VERSION ""

NS_ :

BS_:

BU_: GW ZCU_L ADC10 Tester

BO_ 719 IFC_FD3: 64 ADC10
 SG_ AttentionDivsAlarmTimGrad : 445|2@0+ (1,0) [0|3] "NoUnit" Vector__XXX
 SG_ TraLightCtrlSts : 383|3@0+ (1,0) [0|7] "NoUnit" Vector__XXX
 SG_ RR_SideCamaErrSts : 373|3@0+ (1,0) [0|7] "NoUnit" Vector__XXX
 SG_ LR_SideCamaErrSts : 360|3@0+ (1,0) [0|7] "NoUnit" Vector__XXX
 SG_ TraLightSwtResp : 344|1@0+ (1,0) [0|1] "NoUnit" Vector__XXX
 SG_ TraLightRmdInfoDisp : 349|5@0+ (1,0) [0|31] "NoUnit" Vector__XXX
 SG_ TraLightWarnInfoDisp : 337|4@0+ (1,0) [0|15] "NoUnit" Vector__XXX
 SG_ TSR_TFL_EgoVeh : 341|4@0+ (1,0) [0|15] "NoUnit" Vector__XXX
 SG_ TSR_TFL7_LightColor : 328|3@0+ (1,0) [0|7] "NoUnit" Vector__XXX
 SG_ TSR_TFL7_LightType : 332|4@0+ (1,0) [0|15] "NoUnit" Vector__XXX
 SG_ TSR_TFL6_LightColor : 335|3@0+ (1,0) [0|7] "NoUnit" Vector__XXX
 SG_ TSR_TFL6_LightType : 319|4@0+ (1,0) [0|15] "NoUnit" Vector__XXX
 SG_ TSR_TFL5_LightColor : 307|3@0+ (1,0) [0|7] "NoUnit" Vector__XXX
 SG_ TSR_TFL5_LightType : 311|4@0+ (1,0) [0|15] "NoUnit" Vector__XXX
 SG_ TSR_TFL4_LightColor : 298|3@0+ (1,0) [0|7] "NoUnit" Vector__XXX
 SG_ TSR_TFL4_LightType : 302|4@0+ (1,0) [0|15] "NoUnit" Vector__XXX
 SG_ TSR_TFL3_LightColor : 289|3@0+ (1,0) [0|7] "NoUnit" Vector__XXX
 SG_ TSR_TFL3_LightType : 293|4@0+ (1,0) [0|15] "NoUnit" Vector__XXX
 SG_ TSR_TFL2_LightColor : 280|3@0+ (1,0) [0|7] "NoUnit" Vector__XXX
 SG_ TSR_TFL2_LightType : 284|4@0+ (1,0) [0|15] "NoUnit" Vector__XXX
 SG_ TSR_TFL1_LightColor : 287|3@0+ (1,0) [0|7] "NoUnit" Vector__XXX
 SG_ TSR_TFL7_LightTime : 279|8@0+ (1,0) [0|255] "s" Vector__XXX
 SG_ TSR_TFL6_LightTime : 271|8@0+ (1,0) [0|255] "s" Vector__XXX
 SG_ NavDecActive : 239|4@0+ (1,0) [0|15] "NoUnit" Vector__XXX
 SG_ LCMode_Swt_Resp : 227|2@0+ (1,0) [0|3] "NoUnit" Vector__XXX
 SG_ RainMode_Swt_Resp : 228|1@0+ (1,0) [0|1] "NoUnit" Vector__XXX
 SG_ TSR_Traffic_Light_Ri : 230|2@0+ (1,0) [0|3] "NoUnit" Vector__XXX
 SG_ Zebra_Mark_Dx : 223|9@0+ (0.5,0) [0|150] "m" Vector__XXX
 SG_ TSR_Traffic_Light_Le : 210|2@0+ (1,0) [0|3] "NoUnit" Vector__XXX
 SG_ TSR_Traffic_Light_Through : 212|2@0+ (1,0) [0|3] "NoUnit" Vector__XXX
 SG_ TSR_Traffic_Light : 214|2@0+ (1,0) [0|3] "NoUnit" Vector__XXX
 SG_ Grid_Mark_Dx : 207|9@0+ (0.5,0) [0|150] "m" Vector__XXX
 SG_ LaneChngCfmSwt_Resp : 189|1@0+ (1,0) [0|1] "NoUnit" Vector__XXX
 SG_ ALC_SwtReq_Resp : 190|1@0+ (1,0) [0|1] "NoUnit" Vector__XXX
 SG_ AutoSpdSetSwt_Resp : 191|1@0+ (1,0) [0|1] "NoUnit" Vector__XXX
 SG_ VoiceBrdcSwt_Resp : 176|1@0+ (1,0) [0|1] "NoUnit" Vector__XXX
 SG_ UsrManSts_Resp : 180|4@0+ (1,0) [0|15] "NoUnit" Vector__XXX
 SG_ HWA_InhibitWarn : 183|3@0+ (1,0) [0|7] "NoUnit" Vector__XXX
 SG_ Grid_Mark_Detn : 169|2@0+ (1,0) [0|3] "NoUnit" Vector__XXX
 SG_ Zebra_Mark_Detn : 171|2@0+ (1,0) [0|3] "NoUnit" Vector__XXX
 SG_ Stop_Mark_Detn : 173|2@0+ (1,0) [0|3] "NoUnit" Vector__XXX
 SG_ IFC_Line02_Source : 174|1@0+ (1,0) [0|1] "NoUnit" Vector__XXX
 SG_ Stop_Mark_Dx : 167|9@0+ (0.5,0) [0|150] "m" Vector__XXX
 SG_ TSR_Traffic_Light_Posn : 153|2@0+ (1,0) [0|3] "NoUnit" Vector__XXX
 SG_ NOH_WarnInfoDisp : 157|4@0+ (1,0) [0|15] "NoUnit" Vector__XXX
 SG_ MRC_TakOver_Req : 159|2@0+ (1,0) [0|3] "NoUnit" Vector__XXX
 SG_ IFC_Line01_Source : 144|1@0+ (1,0) [0|1] "NoUnit" Vector__XXX
 SG_ MRC_InterSysInfoDisp : 148|4@0+ (1,0) [0|15] "NoUnit" Vector__XXX
 SG_ HWA_TakOver_Trig : 151|3@0+ (1,0) [0|7] "NoUnit" Vector__XXX
 SG_ HWA_TakOver_Req : 137|2@0+ (1,0) [0|3] "NoUnit" Vector__XXX
 SG_ HWA_WarnInfoDisp : 141|4@0+ (1,0) [0|15] "NoUnit" Vector__XXX
 SG_ HWA_ALC_Trig : 143|2@0+ (1,0) [0|3] "NoUnit" Vector__XXX
 SG_ RollingCounter_IFC7 : 123|4@0+ (1,0) [0|14] "NoUnit" Vector__XXX
 SG_ HMA_Sts : 127|3@0+ (1,0) [0|7] "NoUnit" Vector__XXX
 SG_ HMA_HibeamReq : 113|2@0+ (1,0) [0|3] "NoUnit" Vector__XXX
 SG_ IDC_L2_FWshrReq : 119|2@0+ (1,0) [0|3] "NoUnit" Vector__XXX
 SG_ TSRSpdLimWarnAu : 104|1@0+ (1,0) [0|1] "NoUnit" Vector__XXX
 SG_ IDC_L2_FWiperReq : 107|3@0+ (1,0) [0|7] "NoUnit" Vector__XXX
 SG_ TSRWarnResp : 108|1@0+ (1,0) [0|1] "NoUnit" Vector__XXX
 SG_ IDC_L2_TurnLightReq : 110|2@0+ (1,0) [0|3] "NoUnit" Vector__XXX
 SG_ IDC_L2_EmgyLightReq : 111|1@0+ (1,0) [0|1] "NoUnit" Vector__XXX
 SG_ TSR_Snvty : 100|5@0+ (1,-15) [-15|15] "kph" Vector__XXX
 SG_ TSRSpdLimWarn : 101|1@0+ (1,0) [0|1] "NoUnit" Vector__XXX
 SG_ TSRTrfcSignVal : 93|8@0+ (1,0) [0|255] "NoUnit" Vector__XXX
 SG_ TSRTrfcSignValCfdc : 95|2@0+ (1,0) [0|3] "NoUnit" Vector__XXX
 SG_ TSRSpdLimSts : 81|2@0+ (1,0) [0|3] "NoUnit" Vector__XXX
 SG_ TSRSpdLim : 87|6@0+ (1,0) [0|63] "NoUnit" Vector__XXX
 SG_ TSRSts : 74|3@0+ (1,0) [0|7] "NoUnit" Vector__XXX
 SG_ TSRSpdLimCfdc : 76|2@0+ (1,0) [0|3] "NoUnit" Vector__XXX
 SG_ TSRSpdLimUnit : 78|2@0+ (1,0) [0|3] "NoUnit" Vector__XXX
 SG_ TSRResp : 79|1@0+ (1,0) [0|1] "NoUnit" Vector__XXX
 SG_ Checksum_IFC7 : 71|8@0+ (1,0) [0|255] "NoUnit" Vector__XXX
 SG_ TSR_TFL1_LightType : 63|4@0+ (1,0) [0|15] "NoUnit" Vector__XXX
 SG_ TSR_TFL5_LightTime : 55|8@0+ (1,0) [0|255] "s" Vector__XXX
 SG_ TSR_TFL4_LightTime : 47|8@0+ (1,0) [0|255] "s" Vector__XXX
 SG_ TSR_TFL3_LightTime : 39|8@0+ (1,0) [0|255] "s" Vector__XXX
 SG_ TSR_TFL2_LightTime : 31|8@0+ (1,0) [0|255] "s" Vector__XXX
 SG_ TSR_TFL1_LightTime : 23|8@0+ (1,0) [0|255] "s" Vector__XXX
 SG_ TSRConSpdLimWarn : 9|1@0+ (1,0) [0|1] "NoUnit" Vector__XXX
 SG_ TSRConSpdLim : 15|6@0+ (1,0) [0|63] "NoUnit" Vector__XXX

BO_ 846 ACC_FD5: 16 ADC10
 SG_ Sync_SyncTime : 39|32@0+ (1,0) [0|4294967295] "NoUnit" Vector__XXX
 SG_ Sync_OVS : 25|2@0+ (1,0) [0|3] "NoUnit" Vector__XXX
 SG_ Sync_SGW : 26|1@0+ (1,0) [0|1] "NoUnit" Vector__XXX
 SG_ Sync_Resd : 31|5@0+ (1,0) [0|31] "NoUnit" Vector__XXX
 SG_ Sync_Counter : 19|4@0+ (1,0) [0|15] "NoUnit" Vector__XXX
 SG_ Sync_TimeDomain : 23|4@0+ (1,0) [0|15] "NoUnit" Vector__XXX
 SG_ Sync_CRC : 15|8@0+ (1,0) [0|255] "NoUnit" Vector__XXX
 SG_ Sync_Type : 7|8@0+ (1,0) [0|255] "NoUnit" Vector__XXX

BO_ 259 ECM_FD2: 64 GW
 SG_ MAC_Check_ECM_FD2 : 471|48@0+ (1,0) [0|281474976710655] "NoUnit"  ADC10
 SG_ FreshnessValue_ECM_FD2 : 455|16@0+ (1,0) [0|65535] "NoUnit"  ADC10
 SG_ EngState_PHEV : 351|3@0+ (1,0) [0|7] "NoUnit"  ADC10

BO_ 273 ECM1: 8 GW
 SG_ EngSpdVldty : 63|2@0+ (1,0) [0|3] "NoUnit"  ADC10
 SG_ EngSpd : 47|16@0+ (0.125,0) [0|8191.875] "rpm"  ADC10

BO_ 283 VCU_FD2: 64 GW
 SG_ VMCFucActvSts : 423|4@0+ (1,0) [0|15] "NoUnit"  ADC10
 SG_ AccrPedlAntiMsstpngSts : 209|2@0+ (1,0) [0|3] "NoUnit"  ADC10
 SG_ IOTACoolingResp : 211|2@0+ (1,0) [0|3] "NoUnit"  ADC10
 SG_ VCU_MaxSpdLimit : 207|12@0+ (0.1,0) [0|300] "kph"  ADC10
 SG_ RollingCounter_VCU26 : 187|4@0+ (1,0) [0|14] "NoUnit"  ADC10
 SG_ DrvTrqReqOvld : 189|2@0+ (1,0) [0|3] "NoUnit"  ADC10
 SG_ ActTotWheelTrq : 171|13@0+ (5,-20475) [-20475|20475] "Nm"  ADC10
 SG_ VCU_DrvReqTqWhl : 167|12@0+ (5,-6000) [-6000|14470] "Nm"  ADC10
 SG_ MaxPsblPosWheelTrq : 147|12@0+ (5,0) [0|20470] "Nm"  ADC10
 SG_ MinPsblNegWheelTrq : 143|12@0+ (5,-20470) [-20470|0] "Nm"  ADC10
 SG_ Checksum_VCU26 : 135|8@0+ (1,0) [0|255] "NoUnit"  ADC10
 SG_ RollingCounter_VCU21 : 123|4@0+ (1,0) [0|14] "NoUnit"  ADC10
 SG_ DrvgPrkgTrqRespFlg : 125|2@0+ (1,0) [0|3] "NoUnit"  ADC10
 SG_ DrvgPrkgTrqAvailSts : 127|2@0+ (1,0) [0|3] "NoUnit"  ADC10
 SG_ DrvTrqReqOvrdvld : 89|1@0+ (1,0) [0|1] "NoUnit"  ADC10
 SG_ Checksum_VCU21 : 71|8@0+ (1,0) [0|255] "NoUnit"  ADC10
 SG_ RollingCounter_VCU12 : 59|4@0+ (1,0) [0|14] "NoUnit"  ADC10
 SG_ PTDrvMod : 62|3@0+ (1,0) [0|7] "NoUnit"  ADC10
 SG_ DrvMod : 20|5@0+ (1,0) [0|31] "NoUnit"  ADC10
 SG_ VCU_ACCComIf : 23|1@0+ (1,0) [0|1] "NoUnit"  ADC10
 SG_ ActDrvMod : 15|5@0+ (1,0) [0|31] "NoUnit"  ADC10
 SG_ Checksum_VCU12 : 7|8@0+ (1,0) [0|255] "NoUnit"  ADC10

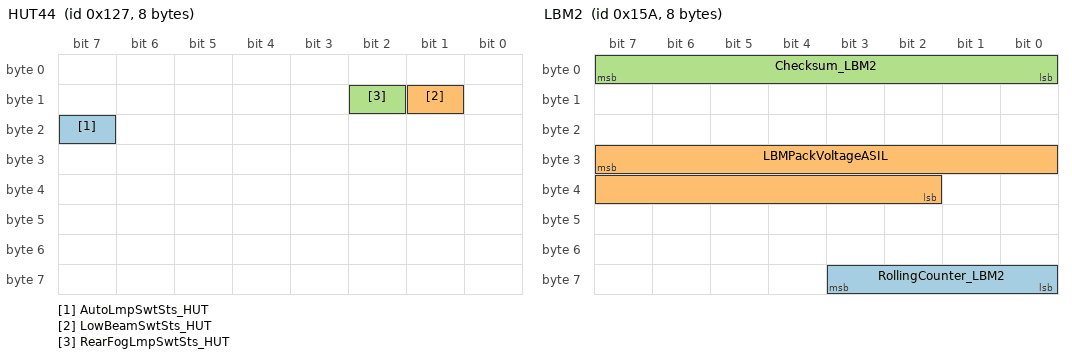
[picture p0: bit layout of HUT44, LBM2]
BO_ 295 HUT44: 8 GW
 SG_ AutoLmpSwtSts_HUT : 23|1@0+ (1,0) [0|1] "NoUnit"  ADC10
 SG_ LowBeamSwtSts_HUT : 9|1@0+ (1,0) [0|1] "NoUnit"  ADC10
 SG_ RearFogLmpSwtSts_HUT : 10|1@0+ (1,0) [0|1] "NoUnit"  ADC10

BO_ 302 IBC_FD1: 64 GW
 SG_ RollingCounter_IBC_FD1_5 : 315|4@0+ (1,0) [0|14] "NoUnit"  ADC10
 SG_ APCFailrSts : 318|3@0+ (1,0) [0|7] "NoUnit"  ADC10
 SG_ BrkgOvrdVld : 306|1@0+ (1,0) [0|1] "NoUnit"  ADC10
 SG_ MEBavailability : 308|1@0+ (1,0) [0|1] "NoUnit"  ADC10
 SG_ APCSts : 311|3@0+ (1,0) [0|7] "NoUnit"  ADC10
 SG_ RPAavailability : 297|2@0+ (1,0) [0|3] "NoUnit"  ADC10
 SG_ APAavailability : 298|1@0+ (1,0) [0|1] "NoUnit"  ADC10
 SG_ CddApActvVehHld : 299|1@0+ (1,0) [0|1] "NoUnit"  ADC10
 SG_ AVPavailability : 301|2@0+ (1,0) [0|3] "NoUnit"  ADC10
 SG_ DrvBrkOvrdFlg : 303|2@0+ (1,0) [0|3] "NoUnit"  ADC10
 SG_ Checksum_IBC_FD1_5 : 263|8@0+ (1,0) [0|255] "NoUnit"  ADC10
 SG_ HydBrkgActTrq : 163|14@0+ (1,-1) [0|16383] "Nm"  ADC10
 SG_ HydBrkgTrqReq : 145|14@0+ (1,-1) [0|16383] "Nm"  ADC10
 SG_ DrvBrkgTrqReq : 143|14@0+ (1,-1) [0|16383] "Nm"  ADC10
 SG_ RollingCounter_IBC_FD1_2 : 123|4@0+ (1,0) [0|14] "NoUnit"  ADC10
 SG_ BrkHldActvSts : 113|2@0+ (1,0) [0|3] "NoUnit"  ADC10
 SG_ BrkHldAvailSts : 115|2@0+ (1,0) [0|3] "NoUnit"  ADC10
 SG_ BrkgTrqModResp : 119|2@0+ (1,0) [0|3] "NoUnit"  ADC10
 SG_ PrkgBrkgTrqAvailSts : 90|3@0+ (1,0) [0|7] "NoUnit"  ADC10
 SG_ DrvgBrkgTrqAvailSts : 93|3@0+ (1,0) [0|7] "NoUnit"  ADC10
 SG_ Checksum_IBC_FD1_2 : 71|8@0+ (1,0) [0|255] "NoUnit"  ADC10
 SG_ RollingCounter_IBC_FD1_1 : 59|4@0+ (1,0) [0|14] "NoUnit"  ADC10
 SG_ PushrodStauts : 51|2@0+ (1,0) [0|3] "NoUnit"  ADC10
 SG_ InpRodStk : 47|10@0+ (0.05,-5) [-5|46.15] "mm"  ADC10
 SG_ InpRodStkSts : 32|1@0+ (1,0) [0|1] "NoUnit"  ADC10
 SG_ FWA_Warn : 34|2@0+ (1,0) [0|3] "NoUnit"  ADC10
 SG_ PlungerPressSts : 35|1@0+ (1,0) [0|1] "NoUnit"  ADC10
 SG_ PlungerPress : 31|12@0+ (0.3,-5) [-5|301.9] "Bar"  ADC10
 SG_ Checksum_IBC_FD1_1 : 7|8@0+ (1,0) [0|255] "NoUnit"  ADC10

BO_ 311 ESP_FD2: 64 GW
 SG_ MAC_Check_ESP_FD2 : 471|48@0+ (1,0) [0|281474976710655] "NoUnit"  ADC10
 SG_ FreshnessValue_ESP_FD2 : 455|16@0+ (1,0) [0|65535] "NoUnit"  ADC10
 SG_ RWSAngMinLimn : 437|10@0+ (0.01,-10) [-10|0] "Deg"  ADC10
 SG_ RWSAngMaxLimn : 431|10@0+ (0.01,0) [0|10] "Deg"  ADC10
 SG_ RollingCounter_ABS3 : 379|4@0+ (1,0) [0|14] "NoUnit"  ADC10
 SG_ ABSActv : 347|1@0+ (1,0) [0|1] "NoUnit"  ADC10
 SG_ EBDActv : 351|1@0+ (1,0) [0|1] "NoUnit"  ADC10
 SG_ VehSpd : 332|13@0+ (0.05625,0) [0|299.98125] "kph"  ADC10
 SG_ VehSpdVld : 333|1@0+ (1,0) [0|1] "NoUnit"  ADC10
 SG_ EBDFailSts : 334|1@0+ (1,0) [0|1] "NoUnit"  ADC10
 SG_ ABSFailSts : 335|1@0+ (1,0) [0|1] "NoUnit"  ADC10
 SG_ Checksum_ABS3 : 327|8@0+ (1,0) [0|255] "NoUnit"  ADC10
 SG_ DrvTrqIncReqActv_FA : 318|1@0+ (1,0) [0|1] "NoUnit"  ADC10
 SG_ DrvTrqRedReqActv_FA : 319|1@0+ (1,0) [0|1] "NoUnit"  ADC10
 SG_ DrvTrqRedFastReq_FA : 287|16@0+ (1,-3000) [-3000|14475] "Nm"  ADC10
 SG_ DrvTrqIncReq_FA : 271|16@0+ (1,-3000) [-3000|5000] "Nm"  ADC10
 SG_ RollingCounter_ESP7 : 251|4@0+ (1,0) [0|14] "NoUnit"  ADC10
 SG_ APS_EngTrqReqEna : 247|1@0+ (1,0) [0|1] "NoUnit"  ADC10
 SG_ EngTrqReq : 231|16@0+ (1,-16383) [-16383|16384] "Nm"  ADC10
 SG_ LgtCtrlrFailr : 220|3@0+ (1,0) [0|7] "NoUnit"  ADC10
 SG_ FourWhlsBrkTrq : 207|14@0+ (1,0) [0|16383] "NoUnit"  ADC10
 SG_ Checksum_ESP7 : 199|8@0+ (1,0) [0|255] "NoUnit"  ADC10
 SG_ RollingCounter_ESP1 : 187|4@0+ (1,0) [0|14] "NoUnit"  ADC10
 SG_ MSRActv_RA : 174|1@0+ (1,0) [0|1] "NoUnit"  ADC10
 SG_ ESP_MasterCylBrkPress : 159|16@0+ (0.03125,-42.5) [-42.5|425] "Bar"  ADC10
 SG_ ESP_MasterCylBrkPressVld : 144|1@0+ (1,0) [0|1] "NoUnit"  ADC10
 SG_ VDCActv : 148|1@0+ (1,0) [0|1] "NoUnit"  ADC10
 SG_ MSRActv : 149|1@0+ (1,0) [0|1] "NoUnit"  ADC10
 SG_ PTCActv : 150|1@0+ (1,0) [0|1] "NoUnit"  ADC10
 SG_ BTCActv : 151|1@0+ (1,0) [0|1] "NoUnit"  ADC10
 SG_ PTCActv_RA : 136|1@0+ (1,0) [0|1] "NoUnit"  ADC10
 SG_ BTCActv_RA : 137|1@0+ (1,0) [0|1] "NoUnit"  ADC10
 SG_ ESPFuncOffSts : 140|1@0+ (1,0) [0|1] "NoUnit"  ADC10
 SG_ ESPBrkLmpCtrl : 142|1@0+ (1,0) [0|1] "NoUnit"  ADC10
 SG_ ESPFailSts : 143|1@0+ (1,0) [0|1] "NoUnit"  ADC10
 SG_ Checksum_ESP1 : 135|8@0+ (1,0) [0|255] "NoUnit"  ADC10
 SG_ RollingCounter_ESP2 : 123|4@0+ (1,0) [0|14] "NoUnit"  ADC10
 SG_ DrivingModDis : 119|5@0+ (1,0) [0|31] "NoUnit"  ADC10
 SG_ DrivingModReq_ESP : 96|5@0+ (1,0) [0|31] "NoUnit"  ADC10
 SG_ AVHErrSts : 99|2@0+ (1,0) [0|3] "NoUnit"  ADC10
 SG_ AVHSts : 101|2@0+ (1,0) [0|3] "NoUnit"  ADC10
 SG_ CDPActv : 103|1@0+ (1,0) [0|1] "NoUnit"  ADC10
 SG_ HDCCtrl : 91|2@0+ (1,0) [0|3] "NoUnit"  ADC10
 SG_ CDDActv : 92|1@0+ (1,0) [0|1] "NoUnit"  ADC10
 SG_ CDDAvailable : 93|1@0+ (1,0) [0|1] "NoUnit"  ADC10
 SG_ AWBAvailable : 94|1@0+ (1,0) [0|1] "NoUnit"  ADC10
 SG_ AWBActv : 95|1@0+ (1,0) [0|1] "NoUnit"  ADC10
 SG_ HHCSts : 80|1@0+ (1,0) [0|1] "NoUnit"  ADC10
 SG_ AEBIBActv : 81|1@0+ (1,0) [0|1] "NoUnit"  ADC10
 SG_ AEBBAActv : 82|1@0+ (1,0) [0|1] "NoUnit"  ADC10
 SG_ AEBAvailable : 83|1@0+ (1,0) [0|1] "NoUnit"  ADC10
 SG_ ABPAvailable : 84|1@0+ (1,0) [0|1] "NoUnit"  ADC10
 SG_ ABPActv : 85|1@0+ (1,0) [0|1] "NoUnit"  ADC10
 SG_ ABAavailable : 86|1@0+ (1,0) [0|1] "NoUnit"  ADC10
 SG_ ABAActv : 87|1@0+ (1,0) [0|1] "NoUnit"  ADC10
 SG_ ESP_DiagActv : 73|1@0+ (1,0) [0|1] "NoUnit"  ADC10
 SG_ CTABrkAvailable : 74|1@0+ (1,0) [0|1] "NoUnit"  ADC10
 SG_ BrkDskOvrheatd : 75|1@0+ (1,0) [0|1] "NoUnit"  ADC10
 SG_ NoBrkForce : 76|1@0+ (1,0) [0|1] "NoUnit"  ADC10
 SG_ VehStandstill : 78|2@0+ (1,0) [0|3] "NoUnit"  ADC10
 SG_ Checksum_ESP2 : 71|8@0+ (1,0) [0|255] "NoUnit"  ADC10
 SG_ RWSAngLimnSts : 54|3@0+ (1,0) [0|7] "NoUnit"  ADC10
 SG_ RWSAngLimnVld : 55|1@0+ (1,0) [0|1] "NoUnit"  ADC10

BO_ 315 ESP_FD3: 64 GW
 SG_ MAC_Check_ESP_FD3 : 471|48@0+ (1,0) [0|281474976710655] "NoUnit"  ADC10
 SG_ FreshnessValue_ESP_FD3 : 455|16@0+ (1,0) [0|65535] "NoUnit"  ADC10
 SG_ RollingCounter_ABS2 : 379|4@0+ (1,0) [0|14] "NoUnit"  ADC10
 SG_ WssRREdgesSumVld : 382|1@0+ (1,0) [0|1] "NoUnit"  ADC10
 SG_ WssRLEdgesSumVld : 383|1@0+ (1,0) [0|1] "NoUnit"  ADC10
 SG_ WssRLEdgesSum : 375|8@0+ (1,0) [0|255] "NoUnit"  ADC10
 SG_ WssRREdgesSum : 367|8@0+ (1,0) [0|255] "NoUnit"  ADC10
 SG_ RRWheelSpd : 348|13@0+ (0.05625,0) [0|299.98125] "kph"  ADC10
 SG_ RRWheelSpdVld : 349|1@0+ (1,0) [0|1] "NoUnit"  ADC10
 SG_ RRWheelDriveDirection : 351|2@0+ (1,0) [0|3] "NoUnit"  ADC10
 SG_ RLWheelSpd : 332|13@0+ (0.05625,0) [0|299.98125] "kph"  ADC10
 SG_ RLWheelSpdVld : 333|1@0+ (1,0) [0|1] "NoUnit"  ADC10
 SG_ RLWheelDriveDirection : 335|2@0+ (1,0) [0|3] "NoUnit"  ADC10
 SG_ Checksum_ABS2 : 327|8@0+ (1,0) [0|255] "NoUnit"  ADC10
 SG_ DrvTrqIncReqActv_RA : 255|1@0+ (1,0) [0|1] "NoUnit"  ADC10
 SG_ DrvTrqRedReqActv_RA : 232|1@0+ (1,0) [0|1] "NoUnit"  ADC10
 SG_ DrvTrqRedReq_RA : 223|16@0+ (1,-6000) [-6000|14475] "Nm"  ADC10
 SG_ DrvTrqIncReq_RA : 207|16@0+ (1,-6000) [-6000|14475] "Nm"  ADC10
 SG_ RollingCounter_EPB1 : 123|4@0+ (1,0) [0|14] "NoUnit"  ADC10
 SG_ ESP_DSTSts : 116|3@0+ (1,0) [0|7] "NoUnit"  ADC10
 SG_ EPBRedLmpSts : 89|2@0+ (1,0) [0|3] "NoUnit"  ADC10
 SG_ EPBErrSts : 91|2@0+ (1,0) [0|3] "NoUnit"  ADC10
 SG_ EPBSts : 93|2@0+ (1,0) [0|3] "NoUnit"  ADC10
 SG_ EPB_SwtPosn : 95|2@0+ (1,0) [0|3] "NoUnit"  ADC10
 SG_ EPB_SwtPosnVld : 80|1@0+ (1,0) [0|1] "NoUnit"  ADC10
 SG_ Checksum_EPB1 : 71|8@0+ (1,0) [0|255] "NoUnit"  ADC10
 SG_ RollingCounter_ABS1 : 59|4@0+ (1,0) [0|14] "NoUnit"  ADC10
 SG_ WssFREdgesSumVld : 62|1@0+ (1,0) [0|1] "NoUnit"  ADC10
 SG_ WssFLEdgesSumVld : 63|1@0+ (1,0) [0|1] "NoUnit"  ADC10
 SG_ WssFREdgesSum : 55|8@0+ (1,0) [0|255] "NoUnit"  ADC10
 SG_ WssFLEdgesSum : 47|8@0+ (1,0) [0|255] "NoUnit"  ADC10
 SG_ FRWheelSpd : 28|13@0+ (0.05625,0) [0|299.98125] "kph"  ADC10
 SG_ FRWheelSpdVld : 29|1@0+ (1,0) [0|1] "NoUnit"  ADC10
 SG_ FRWheelDriveDirection : 31|2@0+ (1,0) [0|3] "NoUnit"  ADC10
 SG_ FLWheelSpd : 12|13@0+ (0.05625,0) [0|299.98125] "kph"  ADC10
 SG_ FLWheelSpdVld : 13|1@0+ (1,0) [0|1] "NoUnit"  ADC10
 SG_ FLWheelDriveDirection : 15|2@0+ (1,0) [0|3] "NoUnit"  ADC10
 SG_ Checksum_ABS1 : 7|8@0+ (1,0) [0|255] "NoUnit"  ADC10

BO_ 320 RWA_FD2: 24 GW
 SG_ RollingCounter_RWA_FD2_2 : 123|4@0+ (1,0) [0|14] "NoUnit"  ADC10
 SG_ SBWActr_PinionAngSpd_Backup : 81|15@0+ (0.1,-1016.1) [-1016|1016] "DegPerSec"  ADC10
 SG_ SBWActr_PinionAng_Backup : 79|14@0+ (0.1,-780.1) [-780|780] "Deg"  ADC10
 SG_ Checksum_RWA_FD2_2 : 71|8@0+ (1,0) [0|255] "NoUnit"  ADC10

BO_ 326 VDC_FD1: 24 GW
 SG_ SuspLvlTrigSrc : 83|3@0+ (1,0) [0|7] "NoUnit"  ADC10
 SG_ TarLvlChg : 51|3@0+ (1,0) [0|7] "NoUnit"  ADC10
 SG_ CurrLvlCtrlMode : 54|3@0+ (1,0) [0|7] "NoUnit"  ADC10
 SG_ LvlAdjmtSts : 10|3@0+ (1,0) [0|7] "NoUnit"  ADC10

BO_ 327 EPS_FD1: 64 GW
 SG_ RollingCounter_EPS3 : 187|4@0+ (1,0) [0|14] "NoUnit"  ADC10
 SG_ EPS_HADHndShkRespSt : 190|3@0+ (1,0) [0|7] "NoUnit"  ADC10
 SG_ EPS_AngCmdOverRange : 191|1@0+ (1,0) [0|1] "NoUnit"  ADC10
 SG_ EPS_AvailStsforHAD : 177|2@0+ (1,0) [0|3] "NoUnit"  ADC10
 SG_ EPS_SteerWheelAngVld : 178|1@0+ (1,0) [0|1] "NoUnit"  ADC10
 SG_ EPS_HADerror_Reason : 183|4@0+ (1,0) [0|15] "NoUnit"  ADC10
 SG_ EPS_SteerWheelSpdSign : 168|1@0+ (1,0) [0|1] "NoUnit"  ADC10
 SG_ EPS_SteerWheelSpd : 167|15@0+ (0.1,0) [0|1016] "DegPerSec"  ADC10
 SG_ EPS_SteerWheelAngSign : 152|1@0+ (1,0) [0|1] "NoUnit"  ADC10
 SG_ EPS_SteerWheelAng : 151|15@0+ (0.1,0) [0|780] "Deg"  ADC10
 SG_ Checksum_EPS3 : 135|8@0+ (1,0) [0|255] "NoUnit"  ADC10
 SG_ RollingCounter_EPS2 : 123|4@0+ (1,0) [0|14] "NoUnit"  ADC10
 SG_ EPS_LKATrqOvlDlvdSts : 125|2@0+ (1,0) [0|3] "NoUnit"  ADC10
 SG_ EPS_DrvInpTrqVal_HighResVld : 126|1@0+ (1,0) [0|1] "NoUnit"  ADC10
 SG_ EPS_LKATorqOvrlDlvdVld : 127|1@0+ (1,0) [0|1] "NoUnit"  ADC10
 SG_ EPS_LKATorqOvrlDlvd : 111|16@0+ (0.01,-15) [-15|15] "Nm"  ADC10
 SG_ EPS_LKAAngDlvdSts : 83|2@0+ (1,0) [0|3] "NoUnit"  ADC10
 SG_ EPS_DrvInpTrqVal_HighReslolution : 79|12@0+ (0.015625,-31.984375) [-31.984375|32] "Nm"  ADC10
 SG_ Checksum_EPS2 : 71|8@0+ (1,0) [0|255] "NoUnit"  ADC10
 SG_ RollingCounter_EPS1 : 59|4@0+ (1,0) [0|14] "NoUnit"  ADC10
 SG_ EPS_SteerMod : 55|3@0+ (1,0) [0|7] "NoUnit"  ADC10
 SG_ SteerSysFltTyp : 39|4@0+ (1,0) [0|15] "NoUnit"  ADC10
 SG_ EPS_AvailSts : 29|2@0+ (1,0) [0|3] "NoUnit"  ADC10
 SG_ EPS_InterferDetdVld : 30|1@0+ (1,0) [0|1] "NoUnit"  ADC10
 SG_ EPS_InterferDetd : 31|1@0+ (1,0) [0|1] "NoUnit"  ADC10
 SG_ EPS_DSTCtrlSts : 11|3@0+ (1,0) [0|7] "NoUnit"  ADC10
 SG_ EPS_FailSts : 13|2@0+ (1,0) [0|3] "NoUnit"  ADC10
 SG_ EPS_TrqSnsrSts : 14|1@0+ (1,0) [0|1] "NoUnit"  ADC10
 SG_ Checksum_EPS1 : 7|8@0+ (1,0) [0|255] "NoUnit"  ADC10

BO_ 332 RWA_FD1: 24 GW
 SG_ RollingCounter_RWA_FD1_2 : 123|4@0+ (1,0) [0|14] "NoUnit"  ADC10
 SG_ SBWActr_PinionAngSpd : 81|15@0+ (0.1,-1016.1) [-1016|1016] "DegPerSec"  ADC10
 SG_ SBWActr_PinionAng : 79|14@0+ (0.1,-780.1) [-780|780] "Deg"  ADC10
 SG_ Checksum_RWA_FD1_2 : 71|8@0+ (1,0) [0|255] "NoUnit"  ADC10

BO_ 346 LBM2: 8 GW
 SG_ RollingCounter_LBM2 : 59|4@0+ (1,0) [0|14] "NoUnit"  ADC10
 SG_ LBMPackVoltageASIL : 31|14@0+ (0.001,0) [0|16.382] "V"  ADC10
 SG_ Checksum_LBM2 : 7|8@0+ (1,0) [0|255] "NoUnit"  ADC10

BO_ 356 EPS_FD2: 64 GW
 SG_ RollingCounter_EPS_FD2_3 : 187|4@0+ (1,0) [0|14] "NoUnit"  ADC10
 SG_ Checksum_EPS_FD2_3 : 135|8@0+ (1,0) [0|255] "NoUnit"  ADC10
 SG_ RollingCounter_EPS_FD2_2 : 123|4@0+ (1,0) [0|14] "NoUnit"  ADC10
 SG_ EPS_LKATrqOvlDlvdSts_Backup : 115|2@0+ (1,0) [0|3] "NoUnit"  ADC10
 SG_ EPS_LKAAngDlvdSts_Backup : 117|2@0+ (1,0) [0|3] "NoUnit"  ADC10
 SG_ EPS_HADHndShkRespSt_Backup : 104|3@0+ (1,0) [0|7] "NoUnit"  ADC10
 SG_ EPS_AvailSts_Backup : 107|3@0+ (1,0) [0|3] "NoUnit"  ADC10
 SG_ EPS_DrvInpTrqVal_HiRes_Backup : 103|12@0+ (0.015625,-31.984375) [-31.984375|32] "Nm"  ADC10
 SG_ EPS_DrvInpTrqVal_HiResVld_Backup : 88|1@0+ (1,0) [0|1] "NoUnit"  ADC10
 SG_ EPS_AvailStsforHAD_Backup : 90|2@0+ (1,0) [0|3] "NoUnit"  ADC10
 SG_ EPS_HADerror_Reason_Backup : 94|4@0+ (1,0) [0|15] "NoUnit"  ADC10
 SG_ EPS_LKATorqOvrlDlvdVld_Backup : 95|1@0+ (1,0) [0|1] "NoUnit"  ADC10
 SG_ EPS_LKATorqOvrlDlvd_Backup : 79|16@0+ (0.01,-15) [-15|15] "Nm"  ADC10
 SG_ Checksum_EPS_FD2_2 : 71|8@0+ (1,0) [0|255] "NoUnit"  ADC10
 SG_ RollingCounter_EPS_FD2_1 : 59|4@0+ (1,0) [0|14] "NoUnit"  ADC10
 SG_ EPS_TrqSnsrSts_Backup : 60|1@0+ (1,0) [0|1] "NoUnit"  ADC10
 SG_ EPS_InterferDetdVld_Backup : 48|1@0+ (1,0) [0|1] "NoUnit"  ADC10
 SG_ EPS_SteerWheelSpd_Backup : 47|15@0+ (0.1,0) [0|1016] "DegPerSec"  ADC10
 SG_ EPS_SteerWheelSpdSign_Backup : 32|1@0+ (1,0) [0|1] "NoUnit"  ADC10
 SG_ EPS_SteerWheelAng_Backup : 31|15@0+ (0.1,0) [0|780] "Deg"  ADC10
 SG_ EPS_SteerWheelAngVld_Backup : 16|1@0+ (1,0) [0|1] "NoUnit"  ADC10
 SG_ EPS_SteerWheelAngSign_Backup : 17|1@0+ (1,0) [0|1] "NoUnit"  ADC10
 SG_ EPS_InterferDetd_Backup : 12|1@0+ (1,0) [0|1] "NoUnit"  ADC10
 SG_ EPS_AngCmdOverRange_Backup : 13|1@0+ (1,0) [0|1] "NoUnit"  ADC10
 SG_ EPS_FailSts_Backup : 15|2@0+ (1,0) [0|3] "NoUnit"  ADC10
 SG_ Checksum_EPS_FD2_1 : 7|8@0+ (1,0) [0|255] "NoUnit"  ADC10

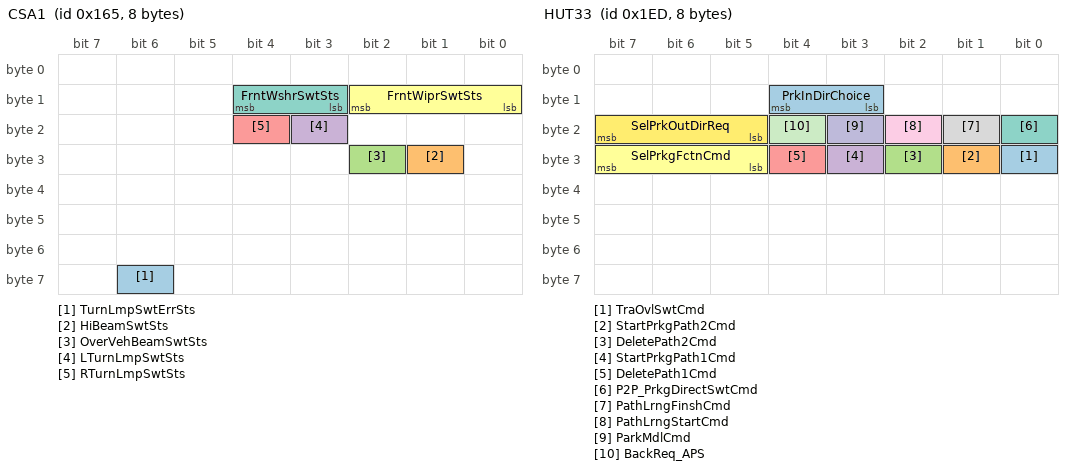
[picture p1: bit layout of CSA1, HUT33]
BO_ 357 CSA1: 8 GW
 SG_ TurnLmpSwtErrSts : 62|1@0+ (1,0) [0|1] "NoUnit"  ADC10
 SG_ HiBeamSwtSts : 25|1@0+ (1,0) [0|1] "NoUnit"  ADC10
 SG_ OverVehBeamSwtSts : 26|1@0+ (1,0) [0|1] "NoUnit"  ADC10
 SG_ LTurnLmpSwtSts : 19|1@0+ (1,0) [0|1] "NoUnit"  ADC10
 SG_ RTurnLmpSwtSts : 20|1@0+ (1,0) [0|1] "NoUnit"  ADC10
 SG_ FrntWiprSwtSts : 10|3@0+ (1,0) [0|7] "NoUnit"  ADC10
 SG_ FrntWshrSwtSts : 12|2@0+ (1,0) [0|3] "NoUnit"  ADC10

BO_ 367 RSDS_FD1: 64 GW
 SG_ RSDS_ObjRelAccelY_Ri : 427|10@0+ (0.03125,-16) [-16|15.9688] "MtrPerSecSq"  ADC10
 SG_ RSDS_ObjRelAccelX_Ri : 421|10@0+ (0.03125,-16) [-16|15.9688] "MtrPerSecSq"  ADC10
 SG_ RSDS_ObjRelAccelX_Le : 415|10@0+ (0.03125,-16) [-16|15.9688] "MtrPerSecSq"  ADC10
 SG_ RSDS_ObjRAccelYStd_Ri : 405|5@0+ (0.375,0) [0|11.625] "MtrPerSecSq"  ADC10
 SG_ RSDS_ObjRAccelXStd_Ri : 394|5@0+ (0.375,0) [0|11.625] "MtrPerSecSq"  ADC10
 SG_ RSDS_ObjRelVelYStd_Ri : 399|5@0+ (0.375,0) [0|11.625] "mps"  ADC10
 SG_ RSDS_ObjRelVelXStd_Ri : 375|5@0+ (0.375,0) [0|11.625] "mps"  ADC10
 SG_ RSDS_ObjDistYStd_Ri : 364|5@0+ (0.375,0) [0|11.625] "m"  ADC10
 SG_ RSDS_ObjDistXStd_Ri : 353|5@0+ (0.375,0) [0|11.625] "m"  ADC10
 SG_ RSDS_ObjRAccelYStd_Le : 358|5@0+ (0.375,0) [0|11.625] "MtrPerSecSq"  ADC10
 SG_ RSDS_ObjRAccelXStd_Le : 347|5@0+ (0.375,0) [0|11.625] "MtrPerSecSq"  ADC10
 SG_ RSDS_ObjRelVelYStd_Le : 336|5@0+ (0.375,0) [0|11.625] "mps"  ADC10
 SG_ RSDS_ObjRelVelXStd_Le : 341|5@0+ (0.375,0) [0|11.625] "mps"  ADC10
 SG_ RSDS_ObjDistYStd_Le : 330|5@0+ (0.375,0) [0|11.625] "m"  ADC10
 SG_ RSDS_ObjDistXStd_Le : 335|5@0+ (0.375,0) [0|11.625] "m"  ADC10
 SG_ RollingCounter_RSDS_R_5 : 315|4@0+ (1,0) [0|14] "NoUnit"  ADC10
 SG_ ObjTTCRi : 308|7@0+ (0.1,0) [0|12.7] "s"  ADC10
 SG_ ObjLatSpdCurvRi : 299|7@0+ (0.1,-6.4) [-6.4|6.3] "mps"  ADC10
 SG_ ObjLgtSpdCurvRi : 293|10@0+ (0.1,-10) [-10|92.3] "mps"  ADC10
 SG_ ObjLatPosnCurvRi : 285|8@0+ (0.1,-12.8) [-12.8|12.7] "m"  ADC10
 SG_ ObjLgtPosnCurvRi : 279|10@0+ (0.1,-92.3) [-92.3|10] "m"  ADC10
 SG_ ObjIDRi : 269|6@0+ (1,0) [0|63] "NoUnit"  ADC10
 SG_ RiTarSts : 271|2@0+ (1,0) [0|3] "NoUnit"  ADC10
 SG_ Checksum_RSDS_R_5 : 263|8@0+ (1,0) [0|255] "NoUnit"  ADC10
 SG_ RollingCounter_RSDS_R_4 : 251|4@0+ (1,0) [0|14] "NoUnit"  ADC10
 SG_ ObjStsRi : 217|2@0+ (1,0) [0|3] "NoUnit"  ADC10
 SG_ ZoneIndRi : 219|2@0+ (1,0) [0|3] "NoUnit"  ADC10
 SG_ ObjStatyRi : 220|1@0+ (1,0) [0|1] "NoUnit"  ADC10
 SG_ ObjWidthRi : 223|3@0+ (0.5,0) [0|3.5] "m"  ADC10
 SG_ ObjRinRi : 211|4@0+ (1,0) [0|15] "m"  ADC10
 SG_ ObjStsLe : 213|2@0+ (1,0) [0|3] "NoUnit"  ADC10
 SG_ ZoneIndLe : 215|2@0+ (1,0) [0|3] "NoUnit"  ADC10
 SG_ ObjStatyLe : 200|1@0+ (1,0) [0|1] "NoUnit"  ADC10
 SG_ ObjWidthLe : 203|3@0+ (0.5,0) [0|3.5] "m"  ADC10
 SG_ ObjLenLe : 207|4@0+ (1,0) [0|15] "m"  ADC10
 SG_ Checksum_RSDS_R_4 : 199|8@0+ (1,0) [0|255] "NoUnit"  ADC10
 SG_ RollingCounter_RSDS_R_3 : 187|4@0+ (1,0) [0|14] "NoUnit"  ADC10
 SG_ ObjTTCLe : 180|7@0+ (0.1,0) [0|12.7] "s"  ADC10
 SG_ ObjLatSpdCurvLe : 171|7@0+ (0.1,-6.4) [-6.4|6.3] "mps"  ADC10
 SG_ ObjLgtSpdCurvLe : 165|10@0+ (0.1,-10) [-10|92.3] "mps"  ADC10
 SG_ ObjLatPosnCurvLe : 157|8@0+ (0.1,-12.8) [-12.8|12.7] "m"  ADC10
 SG_ ObjLgtPosnCurvLe : 151|10@0+ (0.1,-92.3) [-92.3|10] "m"  ADC10
 SG_ ObjIDLe : 141|6@0+ (1,0) [0|63] "NoUnit"  ADC10
 SG_ LeTarSts : 143|2@0+ (1,0) [0|3] "NoUnit"  ADC10
 SG_ Checksum_RSDS_R_3 : 135|8@0+ (1,0) [0|255] "NoUnit"  ADC10
 SG_ RSDS_ObjRelAccelY_Le : 15|10@0+ (0.03125,-16) [-16|15.9688] "MtrPerSecSq"  ADC10

BO_ 388 VCU_FD28: 16 GW
 SG_ RollingCounter_VCU_FD28_2 : 123|4@0+ (1,0) [0|14] ""  ADC10
 SG_ RRIntgrtdWheelSpd : 81|14@0+ (0.01,-25.01) [-25|138] "mps"  ADC10
 SG_ RLIntgrtdWheelSpd : 79|14@0+ (0.01,-25.01) [-25|138] "mps"  ADC10
 SG_ Checksum_VCU_FD28_2 : 71|8@0+ (1,0) [0|255] ""  ADC10
 SG_ RollingCounter_VCU_FD28_1 : 59|4@0+ (1,0) [0|14] ""  ADC10
 SG_ EstimrResutReliabt : 61|2@0+ (1,0) [0|3] ""  ADC10
 SG_ EstimdRoadFricCoeff : 53|5@0+ (0.05,-0.05) [0|1] ""  ADC10
 SG_ FRIntgrtdWheelSpd : 35|14@0+ (0.01,-25.01) [-25|138] "mps"  ADC10
 SG_ FLIntgrtdWheelSpd : 17|14@0+ (0.01,-25.01) [-25|138] "mps"  ADC10
 SG_ IntgrtdVehSpd : 15|14@0+ (0.01,-25.01) [-25|138] "mps"  ADC10
 SG_ Checksum_VCU_FD28_1 : 7|8@0+ (1,0) [0|255] "NoUnit"  ADC10

BO_ 474 HUT_FD4: 64 GW
 SG_ TSRLimSpdChngSoundSet : 153|2@0+ (1,0) [0|3] "NoUnit"  ADC10
 SG_ ACC_OverTakingAsscSet : 155|2@0+ (1,0) [0|3] "NoUnit"  ADC10
 SG_ OneclickClsIntellgntDrvgReq : 147|2@0+ (1,0) [0|3] "NoUnit"  ADC10
 SG_ OutdPrkgReq : 149|2@0+ (1,0) [0|3] "NoUnit"  ADC10
 SG_ CamFolwSwtReq : 140|1@0+ (1,0) [0|1] "NoUnit"  ADC10
 SG_ PrkModReq : 57|2@0+ (1,0) [0|3] "NoUnit"  ADC10
 SG_ TJA_ASCruise : 59|2@0+ (1,0) [0|3] "NoUnit"  ADC10
 SG_ RCTA_DispSwtReq : 60|1@0+ (1,0) [0|1] "NoUnit"  ADC10
 SG_ AutoPrkOutSwtReq : 61|1@0+ (1,0) [0|1] "NoUnit"  ADC10
 SG_ PrkgSlotId : 55|10@0+ (1,0) [1|1023] "NoUnit"  ADC10
 SG_ HAVP_UseMod : 41|2@0+ (1,0) [0|3] "NoUnit"  ADC10
 SG_ HUT_HAVP_APA_Permit : 43|2@0+ (1,0) [0|3] "NoUnit"  ADC10
 SG_ UserDefinedParkCmd : 44|1@0+ (1,0) [0|1] "NoUnit"  ADC10
 SG_ SlotNum_VR : 35|4@0+ (1,0) [0|15] "NoUnit"  ADC10
 SG_ UserDefPrkMenuSelCmd : 18|3@0+ (1,0) [0|7] "NoUnit"  ADC10
 SG_ HUT_HAVP_Set_Path_Ending : 21|1@0+ (1,0) [0|1] "NoUnit"  ADC10
 SG_ HUT_HAVP_Comfirm_Btn : 8|1@0+ (1,0) [0|1] "NoUnit"  ADC10
 SG_ HUT_HAVP_SelfParLot_Ending : 9|1@0+ (1,0) [0|1] "NoUnit"  ADC10
 SG_ HUT_HAVP_Set_Starting : 10|1@0+ (1,0) [0|1] "NoUnit"  ADC10
 SG_ BackReq_RPA : 15|1@0+ (1,0) [0|1] "NoUnit"  ADC10
 SG_ SteerWheelsilentReq : 1|2@0+ (1,0) [0|3] "NoUnit"  ADC10

BO_ 489 HUT30: 8 GW
 SG_ BackReq_AVM : 13|1@0+ (1,0) [0|1] "NoUnit"  ADC10

BO_ 490 BLE2: 8 GW
 SG_ RmtPrkRadShieldSet : 34|2@0+ (1,0) [0|3] "NoUnit"  ADC10

BO_ 493 HUT33: 8 GW
 SG_ TraOvlSwtCmd : 24|1@0+ (1,0) [0|1] "NoUnit"  ADC10
 SG_ StartPrkgPath2Cmd : 25|1@0+ (1,0) [0|1] "NoUnit"  ADC10
 SG_ DeletePath2Cmd : 26|1@0+ (1,0) [0|1] "NoUnit"  ADC10
 SG_ StartPrkgPath1Cmd : 27|1@0+ (1,0) [0|1] "NoUnit"  ADC10
 SG_ DeletePath1Cmd : 28|1@0+ (1,0) [0|1] "NoUnit"  ADC10
 SG_ SelPrkgFctnCmd : 31|3@0+ (1,0) [0|7] "NoUnit"  ADC10
 SG_ P2P_PrkgDirectSwtCmd : 16|1@0+ (1,0) [0|1] "NoUnit"  ADC10
 SG_ PathLrngFinshCmd : 17|1@0+ (1,0) [0|1] "NoUnit"  ADC10
 SG_ PathLrngStartCmd : 18|1@0+ (1,0) [0|1] "NoUnit"  ADC10
 SG_ ParkMdlCmd : 19|1@0+ (1,0) [0|1] "NoUnit"  ADC10
 SG_ BackReq_APS : 20|1@0+ (1,0) [0|1] "NoUnit"  ADC10
 SG_ SelPrkOutDirReq : 23|3@0+ (1,0) [0|7] "NoUnit"  ADC10
 SG_ PrkInDirChoice : 12|2@0+ (1,0) [0|3] "NoUnit"  ADC10

BO_ 494 HUT15: 16 GW
 SG_ APSSwtReq_VR : 55|2@0+ (1,0) [0|3] "NoUnit"  ADC10
 SG_ APSPrkgTypSeln : 34|2@0+ (1,0) [0|3] "NoUnit"  ADC10
 SG_ SDWSwtSet : 39|1@0+ (1,0) [0|1] "NoUnit"  ADC10

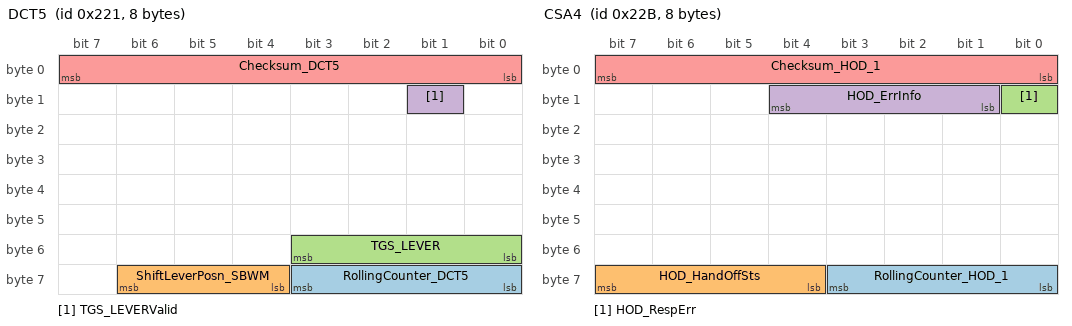
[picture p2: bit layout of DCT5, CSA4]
BO_ 545 DCT5: 8 GW
 SG_ RollingCounter_DCT5 : 59|4@0+ (1,0) [0|14] "NoUnit"  ADC10
 SG_ ShiftLeverPosn_SBWM : 62|3@0+ (1,0) [0|7] "NoUnit"  ADC10
 SG_ TGS_LEVER : 51|4@0+ (1,0) [0|15] "NoUnit"  ADC10
 SG_ TGS_LEVERValid : 9|1@0+ (1,0) [0|1] "NoUnit"  ADC10
 SG_ Checksum_DCT5 : 7|8@0+ (1,0) [0|255] "NoUnit"  ADC10

BO_ 555 CSA4: 8 GW
 SG_ RollingCounter_HOD_1 : 59|4@0+ (1,0) [0|14] "NoUnit"  ADC10
 SG_ HOD_HandOffSts : 63|4@0+ (1,0) [0|15] "NoUnit"  ADC10
 SG_ HOD_RespErr : 8|1@0+ (1,0) [0|1] "NoUnit"  ADC10
 SG_ HOD_ErrInfo : 12|4@0+ (1,0) [0|15] "NoUnit"  ADC10
 SG_ Checksum_HOD_1 : 7|8@0+ (1,0) [0|255] "NoUnit"  ADC10

BO_ 570 CSA5: 8 GW
 SG_ CustomSwtSts_Park : 13|2@0+ (1,0) [0|3] "NoUnit"  ADC10

BO_ 579 HUT_FD3: 64 GW
 SG_ LgtFolwDistanceSet : 378|3@0+ (1,0) [0|7] "NoUnit"  ADC10
 SG_ IntellgntAsscLmpEnaReq : 369|2@0+ (1,0) [0|3] "NoUnit"  ADC10
 SG_ UsrExperiProgAuthorSts : 371|2@0+ (1,0) [0|3] "NoUnit"  ADC10
 SG_ SidePrkgReq : 373|2@0+ (1,0) [0|3] "NoUnit"  ADC10
 SG_ NOAFuncSet : 375|2@0+ (1,0) [0|3] "NoUnit"  ADC10
 SG_ OvertakingLightModReq : 361|2@0+ (1,0) [0|3] "NoUnit"  ADC10
 SG_ IDsceneModReq : 365|4@0+ (1,0) [0|15] "NoUnit"  ADC10
 SG_ PassETCEnaReq : 367|2@0+ (1,0) [0|3] "NoUnit"  ADC10
 SG_ DeviateSpdPreReq : 357|6@0+ (1,-1) [-1|39] "Perc"  ADC10
 SG_ StartReminderEnaReq : 359|2@0+ (1,0) [0|3] "NoUnit"  ADC10
 SG_ DeviateSpdFixdValReq : 349|6@0+ (1,-1) [-1|39] "NoUnit"  ADC10
 SG_ HandsoffModReq : 351|2@0+ (1,0) [0|3] "NoUnit"  ADC10
 SG_ HWA_FaststSwtReq : 337|2@0+ (1,0) [0|3] "NoUnit"  ADC10
 SG_ DeviateSpdModSwtReq : 339|2@0+ (1,0) [0|3] "NoUnit"  ADC10
 SG_ MapStatus : 343|4@0+ (1,0) [0|15] "NoUnit"  ADC10
 SG_ ADAS_gpsAuthSys : 329|1@0+ (1,0) [0|1] "NoUnit"  ADC10
 SG_ PrivacySts : 330|1@0+ (1,0) [0|1] "NoUnit"  ADC10
 SG_ UNP_SwtReq : 331|1@0+ (1,0) [0|1] "NoUnit"  ADC10
 SG_ NOH_Act_Req : 334|1@0+ (1,0) [0|1] "NoUnit"  ADC10
 SG_ NOH_Swt_Req : 335|1@0+ (1,0) [0|1] "NoUnit"  ADC10
 SG_ AVM_3DAngleReq : 239|9@0+ (1,0) [1|361] "NoUnit"  ADC10
 SG_ PrkAreaSts : 225|2@0+ (1,0) [0|3] "NoUnit"  ADC10
 SG_ BeginnerModSts : 191|2@0+ (1,0) [0|3] "NoUnit"  ADC10
 SG_ OneClickAutDrvgSts : 125|1@0+ (1,0) [0|1] "NoUnit"  ADC10
 SG_ HandsoffTimSet : 127|2@0+ (1,0) [0|3] "NoUnit"  ADC10
 SG_ TraLightSwtReq : 62|1@0+ (1,0) [0|1] "NoUnit"  ADC10

BO_ 580 CSA3: 8 GW
 SG_ InrMalfct : 43|1@0+ (1,0) [0|1] "NoUnit"  ADC10

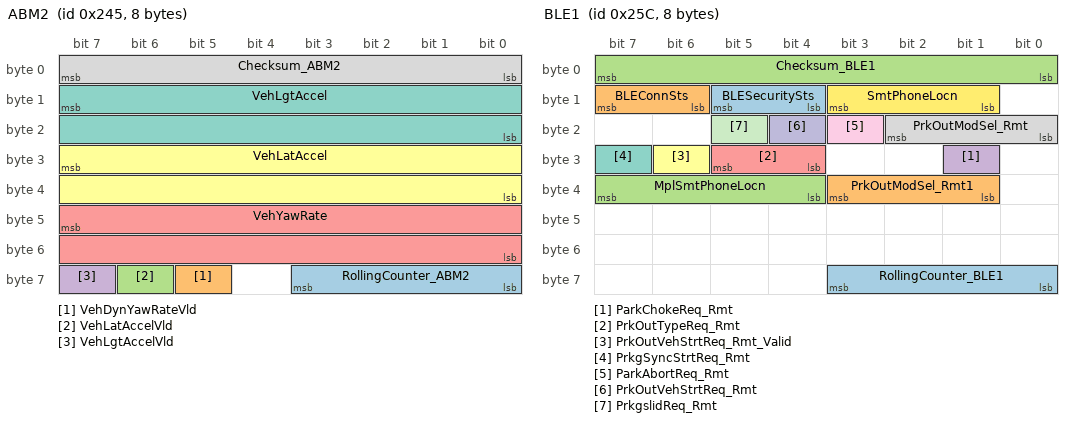
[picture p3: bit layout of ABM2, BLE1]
BO_ 581 ABM2: 8 GW
 SG_ RollingCounter_ABM2 : 59|4@0+ (1,0) [0|14] "NoUnit"  ADC10
 SG_ VehDynYawRateVld : 61|1@0+ (1,0) [0|1] "NoUnit"  ADC10
 SG_ VehLatAccelVld : 62|1@0+ (1,0) [0|1] "NoUnit"  ADC10
 SG_ VehLgtAccelVld : 63|1@0+ (1,0) [0|1] "NoUnit"  ADC10
 SG_ VehYawRate : 47|16@0+ (0.00024,-2.093) [-2.093|2.093] "radPerSec"  ADC10
 SG_ VehLatAccel : 31|16@0+ (0.00098,-21.592) [-21.592|21.592] "MtrPerSecSq"  ADC10
 SG_ VehLgtAccel : 15|16@0+ (0.00098,-21.592) [-21.592|21.592] "MtrPerSecSq"  ADC10
 SG_ Checksum_ABM2 : 7|8@0+ (1,0) [0|255] "NoUnit"  ADC10

BO_ 589 DMS_FD1: 64 GW
 SG_ DrvBehvSts : 370|3@0+ (1,0) [0|7] "NoUnit"  ADC10
 SG_ DMSSts : 303|3@0+ (1,0) [0|7] "NoUnit"  ADC10
 SG_ HeadDetn : 288|1@0+ (1,0) [0|1] "NoUnit"  ADC10
 SG_ DrowsnsLvl_ACC : 92|3@0+ (1,0) [0|7] "NoUnit"  ADC10
 SG_ DistrctnLvl_ACC : 95|3@0+ (1,0) [0|7] "NoUnit"  ADC10
 SG_ DrvGazSts : 2|3@0+ (1,0) [0|7] ""  ADC10

BO_ 596 CSA6: 8 GW
 SG_ LeSideDoRollSts : 19|4@0+ (1,0) [0|15] "NoUnit"  ADC10
 SG_ LeSideUpRollSts : 23|4@0+ (1,0) [0|15] "NoUnit"  ADC10

BO_ 604 BLE1: 8 GW
 SG_ RollingCounter_BLE1 : 59|4@0+ (1,0) [0|14] "NoUnit"  ADC10
 SG_ PrkOutModSel_Rmt1 : 35|3@0+ (1,0) [0|7] "NoUnit"  ADC10
 SG_ MplSmtPhoneLocn : 39|4@0+ (1,0) [0|15] "NoUnit"  ADC10
 SG_ ParkChokeReq_Rmt : 25|1@0+ (1,0) [0|1] "NoUnit"  ADC10
 SG_ PrkOutTypeReq_Rmt : 29|2@0+ (1,0) [0|3] "NoUnit"  ADC10
 SG_ PrkOutVehStrtReq_Rmt_Valid : 30|1@0+ (1,0) [0|1] "NoUnit"  ADC10
 SG_ PrkgSyncStrtReq_Rmt : 31|1@0+ (1,0) [0|1] "NoUnit"  ADC10
 SG_ PrkOutModSel_Rmt : 18|3@0+ (1,0) [0|7] "NoUnit"  ADC10
 SG_ ParkAbortReq_Rmt : 19|1@0+ (1,0) [0|1] "NoUnit"  ADC10
 SG_ PrkOutVehStrtReq_Rmt : 20|1@0+ (1,0) [0|1] "NoUnit"  ADC10
 SG_ PrkgslidReq_Rmt : 21|1@0+ (1,0) [0|1] "NoUnit"  ADC10
 SG_ SmtPhoneLocn : 11|3@0+ (1,0) [0|7] "NoUnit"  ADC10
 SG_ BLESecuritySts : 13|2@0+ (1,0) [0|3] "NoUnit"  ADC10
 SG_ BLEConnSts : 15|2@0+ (1,0) [0|3] "NoUnit"  ADC10
 SG_ Checksum_BLE1 : 7|8@0+ (1,0) [0|255] "NoUnit"  ADC10

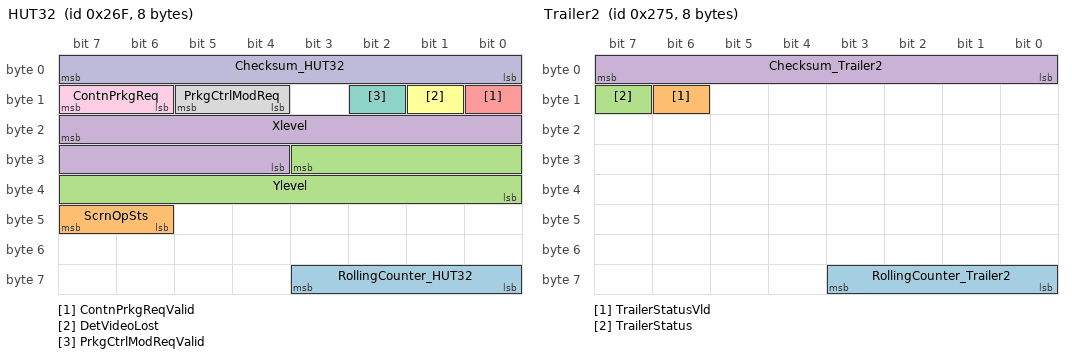
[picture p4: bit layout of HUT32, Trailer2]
BO_ 623 HUT32: 8 GW
 SG_ RollingCounter_HUT32 : 59|4@0+ (1,0) [0|14] "NoUnit"  ADC10
 SG_ ScrnOpSts : 47|2@0+ (1,0) [0|3] "NoUnit"  ADC10
 SG_ Ylevel : 27|12@0+ (1,0) [0|4094] "NoUnit"  ADC10
 SG_ Xlevel : 23|12@0+ (1,0) [0|4094] "NoUnit"  ADC10
 SG_ ContnPrkgReqValid : 8|1@0+ (1,0) [0|1] "NoUnit"  ADC10
 SG_ DetVideoLost : 9|1@0+ (1,0) [0|1] "NoUnit"  ADC10
 SG_ PrkgCtrlModReqValid : 10|1@0+ (1,0) [0|1] "NoUnit"  ADC10
 SG_ PrkgCtrlModReq : 13|2@0+ (1,0) [0|3] "NoUnit"  ADC10
 SG_ ContnPrkgReq : 15|2@0+ (1,0) [0|3] "NoUnit"  ADC10
 SG_ Checksum_HUT32 : 7|8@0+ (1,0) [0|255] "NoUnit"  ADC10

BO_ 627 Trailer1: 8 GW
 SG_ TrailerSts : 7|1@0+ (1,0) [0|1] "NoUnit"  ADC10

BO_ 629 Trailer2: 8 GW
 SG_ RollingCounter_Trailer2 : 59|4@0+ (1,0) [0|14] "NoUnit"  ADC10
 SG_ TrailerStatusVld : 14|1@0+ (1,0) [0|1] "NoUnit"  ADC10
 SG_ TrailerStatus : 15|1@0+ (1,0) [0|1] "NoUnit"  ADC10
 SG_ Checksum_Trailer2 : 7|8@0+ (1,0) [0|255] "NoUnit"  ADC10

BO_ 639 IP2: 16 GW
 SG_ MAC_Check_IP2 : 87|48@0+ (1,0) [0|281474976710655] "NoUnit"  ADC10
 SG_ FreshnessValue_IP2 : 71|16@0+ (1,0) [0|65535] "NoUnit"  ADC10
 SG_ IP_Err : 52|1@0+ (1,0) [0|1] "NoUnit"  ADC10
 SG_ IP_VehSpdUnit : 53|1@0+ (1,0) [0|1] "NoUnit"  ADC10
 SG_ IP_VehTotDistanceValid : 46|1@0+ (1,0) [0|1] "NoUnit"  ADC10
 SG_ IP_ACCErr : 47|1@0+ (1,0) [0|1] "NoUnit"  ADC10
 SG_ IP_VehTotDistance : 15|24@0+ (0.1,0) [0|999999.9] "km"  ADC10

BO_ 647 ALS1: 16 GW
 SG_ RollingCounter_HC1 : 59|4@0+ (1,0) [0|14] "NoUnit"  ADC10
 SG_ ALS_FailSts : 8|1@0+ (1,0) [0|1] "NoUnit"  ADC10
 SG_ Checksum_HC1 : 7|8@0+ (1,0) [0|255] "NoUnit"  ADC10

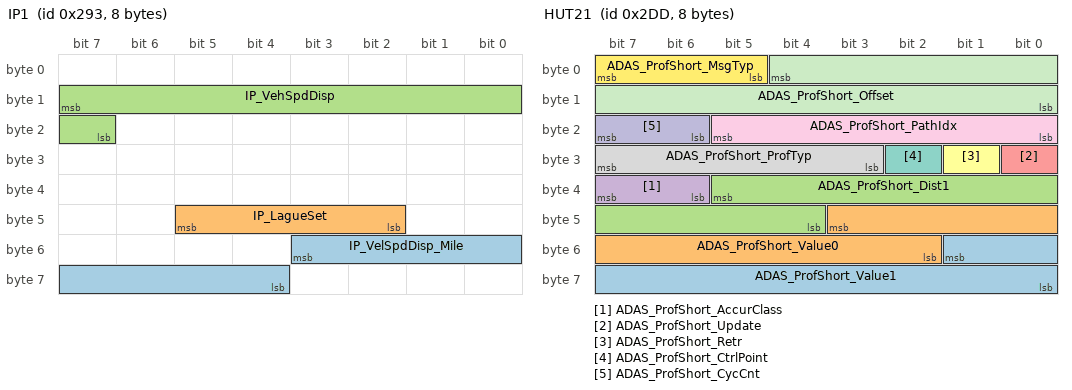
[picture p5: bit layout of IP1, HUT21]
BO_ 659 IP1: 8 GW
 SG_ IP_VelSpdDisp_Mile : 51|8@0+ (1,0) [0|254] "mph"  ADC10
 SG_ IP_LagueSet : 45|4@0+ (1,0) [0|15] "NoUnit"  ADC10
 SG_ IP_VehSpdDisp : 15|9@0+ (0.5,0) [0|255] "kph"  ADC10

BO_ 670 BMS_FD2: 64 GW
 SG_ BMS_CC2LineSts : 211|2@0+ (1,0) [0|3] "NoUnit"  ADC10

BO_ 707 HUT_FD1: 64 GW
 SG_ MAC_Check_HUT_FD1 : 471|48@0+ (1,0) [0|281474976710655] "NoUnit"  ADC10
 SG_ FreshnessValue_HUT_FD1 : 455|16@0+ (1,0) [0|65535] "NoUnit"  ADC10
 SG_ ADAS_Posn_Rehead : 383|8@0+ (1.41732283464567,0) [2.83464566929134|357.165354330709] "NoUnit"  ADC10
 SG_ ADAS_Posn_Spd : 360|9@0+ (0.2,-12.8) [-12.6|89] "mps"  ADC10
 SG_ ADAS_Posn_CurLane : 363|3@0+ (1,0) [0|7] "NoUnit"  ADC10
 SG_ ADAS_Posn_PosConfdc : 366|3@0+ (1,0) [0|6] "NoUnit"  ADC10
 SG_ ADAS_Posn_Age : 344|9@0+ (5,0) [0|2545] "ms"  ADC10
 SG_ ADAS_Posn_PosProbb : 349|5@0+ (3.33,0) [3.33|99.9] "NoUnit"  ADC10
 SG_ ADAS_Posn_Idx : 351|2@0+ (1,0) [0|3] "m"  ADC10
 SG_ ADAS_Posn_Pathldx : 341|6@0+ (1,0) [0|63] "NoUnit"  ADC10
 SG_ ADAS_Posn_CycCnt : 343|2@0+ (1,0) [0|3] "NoUnit"  ADC10
 SG_ ADAS_Posn_Offset : 324|13@0+ (1,0) [0|8190] "m"  ADC10
 SG_ ADAS_Posn_MsgTye : 327|3@0+ (1,0) [0|7] "NoUnit"  ADC10
 SG_ NavSpdLimType : 307|2@0+ (1,0) [0|3] "NoUnit"  ADC10
 SG_ NavigationRoadType : 311|4@0+ (1,0) [0|15] "NoUnit"  ADC10
 SG_ ALC_SwtReq : 296|1@0+ (1,0) [0|1] "NoUnit"  ADC10
 SG_ AESSwtReq : 298|1@0+ (1,0) [0|1] "NoUnit"  ADC10
 SG_ AEB_JASwtReq : 299|1@0+ (1,0) [0|1] "NoUnit"  ADC10
 SG_ FCTABrkSwtReq : 300|1@0+ (1,0) [0|1] "NoUnit"  ADC10
 SG_ FCTASwtReq : 301|1@0+ (1,0) [0|1] "NoUnit"  ADC10
 SG_ HWA_SnvtySet : 303|2@0+ (1,0) [0|3] "NoUnit"  ADC10
 SG_ NavTSRTrafSign : 295|8@0+ (1,0) [0|255] "NoUnit"  ADC10
 SG_ HWA_SwtReq : 280|1@0+ (1,0) [0|1] "NoUnit"  ADC10
 SG_ NavSpdLimSignSts : 285|3@0+ (1,0) [0|7] "NoUnit"  ADC10
 SG_ NavCtryType : 279|10@0+ (1,0) [0|1023] "NoUnit"  ADC10
 SG_ NavSpdLimUnit_HUT : 265|2@0+ (1,0) [0|3] "NoUnit"  ADC10
 SG_ NavSpdLimValue : 271|6@0+ (1,0) [0|63] "NoUnit"  ADC10
 SG_ NavVehToTrafEyeDist : 239|10@0+ (1,0) [0|1023] "NoUnit"  ADC10
 SG_ TSR_SnvtySet : 125|5@0+ (1,-15) [-15|15] "kph"  ADC10
 SG_ ISLSwtReq : 126|1@0+ (1,0) [0|1] "NoUnit"  ADC10
 SG_ DOWSwtReq : 104|1@0+ (1,0) [0|1] "NoUnit"  ADC10
 SG_ AEB_PedSwtReq : 105|1@0+ (1,0) [0|1] "NoUnit"  ADC10
 SG_ LSSSwtReq : 106|1@0+ (1,0) [0|1] "NoUnit"  ADC10
 SG_ IntelligentEvaSwtReq : 107|1@0+ (1,0) [0|1] "NoUnit"  ADC10
 SG_ LSSWarnFormSwtReq : 100|2@0+ (1,0) [0|3] "NoUnit"  ADC10
 SG_ TSRWarnSwtReq : 101|1@0+ (1,0) [0|1] "NoUnit"  ADC10
 SG_ TSRSwtReq : 102|1@0+ (1,0) [0|1] "NoUnit"  ADC10
 SG_ LDWSwtReq : 88|1@0+ (1,0) [0|1] "NoUnit"  ADC10
 SG_ ESS_VehSwtReq : 89|1@0+ (1,0) [0|1] "NoUnit"  ADC10
 SG_ ESS_PedSwtReq : 90|1@0+ (1,0) [0|1] "NoUnit"  ADC10
 SG_ ELKSwtReq : 91|1@0+ (1,0) [0|1] "NoUnit"  ADC10
 SG_ LCKSwtReq : 92|1@0+ (1,0) [0|1] "NoUnit"  ADC10
 SG_ LKASwtReq : 93|1@0+ (1,0) [0|1] "NoUnit"  ADC10
 SG_ AEB_VehSwtReq : 95|1@0+ (1,0) [0|1] "NoUnit"  ADC10
 SG_ FCW_SnvtySet : 81|2@0+ (1,0) [0|3] "NoUnit"  ADC10
 SG_ RCWSwtReq : 82|1@0+ (1,0) [0|1] "NoUnit"  ADC10
 SG_ RCTABrkSwtReq : 83|1@0+ (1,0) [0|1] "NoUnit"  ADC10
 SG_ RCTASwtReq : 84|1@0+ (1,0) [0|1] "NoUnit"  ADC10
 SG_ LCASwtReq : 85|1@0+ (1,0) [0|1] "NoUnit"  ADC10
 SG_ IFC_SnvtySet : 77|2@0+ (1,0) [0|3] "NoUnit"  ADC10
 SG_ NOH_Btn_Sts : 65|1@0+ (1,0) [0|1] "NoUnit"  ADC10
 SG_ DR_CalibratedSts : 69|1@0+ (1,0) [0|1] "NoUnit"  ADC10
 SG_ IntellgntcurveReq : 9|1@0+ (1,0) [0|1] "NoUnit"  ADC10

BO_ 717 PDCM1: 8 GW
 SG_ PassWinPosnSts_Perc : 39|5@0+ (1,0) [0|31] "NoUnit"  ADC10
 SG_ RSDS_Pass_LED_Sts : 8|1@0+ (1,0) [0|1] "NoUnit"  ADC10

BO_ 725 PRDCM1: 8 GW
 SG_ PassRearDoorWinPosnSts_Perc : 15|5@0+ (1,0) [0|31] "NoUnit"  ADC10

BO_ 726 VCU_FD4: 64 GW
 SG_ DrvgRWSModFailSts : 447|4@0+ (1,0) [0|15] "NoUnit"  ADC10
 SG_ WtrAirCoolrPmp_FltSts : 272|1@0+ (1,0) [0|1] "NoUnit"  ADC10
 SG_ RollingCounter_VCU13 : 251|4@0+ (1,0) [0|14] "NoUnit"  ADC10
 SG_ VCU_LTRadrOutlWtrTemp : 223|8@0+ (1,-40) [-40|130] "DegC"  ADC10
 SG_ VCU_WtrPmpOpenRateCtrl : 215|7@0+ (1,0) [0|100] "Perc"  ADC10
 SG_ Checksum_VCU13 : 199|8@0+ (1,0) [0|255] "NoUnit"  ADC10
 SG_ RollingCounter_VCU3 : 123|4@0+ (1,0) [0|14] "NoUnit"  ADC10
 SG_ VCU_RdyLEDSts : 103|2@0+ (1,0) [0|3] "NoUnit"  ADC10
 SG_ Checksum_VCU3 : 71|8@0+ (1,0) [0|255] "NoUnit"  ADC10

BO_ 728 HUT23: 8 GW
 SG_ ADAS_Stub_NumOfLaneDrvDir : 58|3@0+ (1,0) [0|7] "NoUnit"  ADC10
 SG_ ADAS_Stub_NumOfLaneOppDir : 60|2@0+ (1,0) [0|3] "NoUnit"  ADC10
 SG_ ADAS_Stub_RtOfWay : 62|2@0+ (1,0) [0|3] "NoUnit"  ADC10
 SG_ ADAS_Stub_LastStub : 63|1@0+ (1,0) [0|1] "NoUnit"  ADC10
 SG_ ADAS_Stub_TurnAngl : 55|8@0+ (1.417,0) [2.834|357.084] "NoUnit"  ADC10
 SG_ ADAS_Stub_FormOfWay : 43|4@0+ (1,0) [0|15] "NoUnit"  ADC10
 SG_ ADAS_Stub_CmplxInsct : 45|2@0+ (1,0) [0|3] "NoUnit"  ADC10
 SG_ ADAS_Stub_PartOfCalcRoute : 47|2@0+ (1,0) [0|3] "NoUnit"  ADC10
 SG_ ADAS_Stub_FuncRoadClass : 34|3@0+ (1,0) [0|7] "NoUnit"  ADC10
 SG_ ADAS_Stub_RelProbb : 39|5@0+ (3.33333,0) [3.33333|99.9999] "NoUnit"  ADC10
 SG_ ADAS_Stub_Update : 24|1@0+ (1,0) [0|1] "NoUnit"  ADC10
 SG_ ADAS_Stub_Retr : 25|1@0+ (1,0) [0|1] "NoUnit"  ADC10
 SG_ ADAS_Stub_StubPathIdx : 31|6@0+ (1,0) [0|63] "NoUnit"  ADC10
 SG_ ADAS_Stub_PathIdx : 21|6@0+ (1,0) [0|63] "NoUnit"  ADC10
 SG_ ADAS_Stub_CycCnt : 23|2@0+ (1,0) [0|3] "NoUnit"  ADC10
 SG_ ADAS_Stub_Offset : 4|13@0+ (1,0) [0|8190] "m"  ADC10
 SG_ ADAS_Stub_MsgTyp : 7|3@0+ (1,0) [0|7] "NoUnit"  ADC10

BO_ 730 HUT22: 8 GW
 SG_ ADAS_Seg_NumOfLaneDrvDir : 58|3@0+ (1,0) [0|7] "NoUnit"  ADC10
 SG_ ADAS_Seg_NumOfLaneOppDir : 60|2@0+ (1,0) [0|3] "NoUnit"  ADC10
 SG_ ADAS_Seg_DivideRoad : 62|2@0+ (1,0) [0|3] "NoUnit"  ADC10
 SG_ ADAS_Seg_EffSpdLmtTyp : 50|3@0+ (1,0) [0|7] "NoUnit"  ADC10
 SG_ ADAS_Seg_EffSpdLmt : 55|5@0+ (1,0) [0|31] "NoUnit"  ADC10
 SG_ ADAS_Seg_FormOfWay : 43|4@0+ (1,0) [0|15] "NoUnit"  ADC10
 SG_ ADAS_Seg_CmplxInsct : 45|2@0+ (1,0) [0|3] "NoUnit"  ADC10
 SG_ ADAS_Seg_PartOfCalcRoute : 47|2@0+ (1,0) [0|3] "NoUnit"  ADC10
 SG_ ADAS_Seg_FuncRoadClass : 34|3@0+ (1,0) [0|7] "NoUnit"  ADC10
 SG_ ADAS_Seg_RelProbb : 39|5@0+ (3.33333333333333,0) [3.33333333333333|99.9999999999999] "NoUnit"  ADC10
 SG_ ADAS_Seg_Update : 24|1@0+ (1,0) [0|1] "NoUnit"  ADC10
 SG_ ADAS_Seg_Retr : 25|1@0+ (1,0) [0|1] "NoUnit"  ADC10
 SG_ ADAS_Seg_BuildUpArea : 27|2@0+ (1,0) [0|3] "NoUnit"  ADC10
 SG_ ADAS_Seg_Brdg : 29|2@0+ (1,0) [0|3] "NoUnit"  ADC10
 SG_ ADAS_Seg_Tunnel : 31|2@0+ (1,0) [0|3] "NoUnit"  ADC10
 SG_ ADAS_Seg_PathIdx : 21|6@0+ (1,0) [0|63] "NoUnit"  ADC10
 SG_ ADAS_Seg_CycCnt : 23|2@0+ (1,0) [0|3] "NoUnit"  ADC10
 SG_ ADAS_Seg_Offset : 4|13@0+ (1,0) [0|8190] "m"  ADC10
 SG_ ADAS_Seg_MsgTyp : 7|3@0+ (1,0) [0|7] "NoUnit"  ADC10

BO_ 733 HUT21: 8 GW
 SG_ ADAS_ProfShort_Value1 : 49|10@0+ (1,0) [0|1022] "NoUnit"  ADC10
 SG_ ADAS_ProfShort_Value0 : 43|10@0+ (1,0) [0|1022] "NoUnit"  ADC10
 SG_ ADAS_ProfShort_Dist1 : 37|10@0+ (1,0) [1|1022] "m"  ADC10
 SG_ ADAS_ProfShort_AccurClass : 39|2@0+ (1,0) [0|3] "NoUnit"  ADC10
 SG_ ADAS_ProfShort_Update : 24|1@0+ (1,0) [0|1] "NoUnit"  ADC10
 SG_ ADAS_ProfShort_Retr : 25|1@0+ (1,0) [0|1] "NoUnit"  ADC10
 SG_ ADAS_ProfShort_CtrlPoint : 26|1@0+ (1,0) [0|1] "NoUnit"  ADC10
 SG_ ADAS_ProfShort_ProfTyp : 31|5@0+ (1,0) [0|31] "NoUnit"  ADC10
 SG_ ADAS_ProfShort_PathIdx : 21|6@0+ (1,0) [0|63] "NoUnit"  ADC10
 SG_ ADAS_ProfShort_CycCnt : 23|2@0+ (1,0) [0|3] "NoUnit"  ADC10
 SG_ ADAS_ProfShort_Offset : 4|13@0+ (1,0) [0|8190] "m"  ADC10
 SG_ ADAS_ProfShort_MsgTyp : 7|3@0+ (1,0) [0|7] "NoUnit"  ADC10

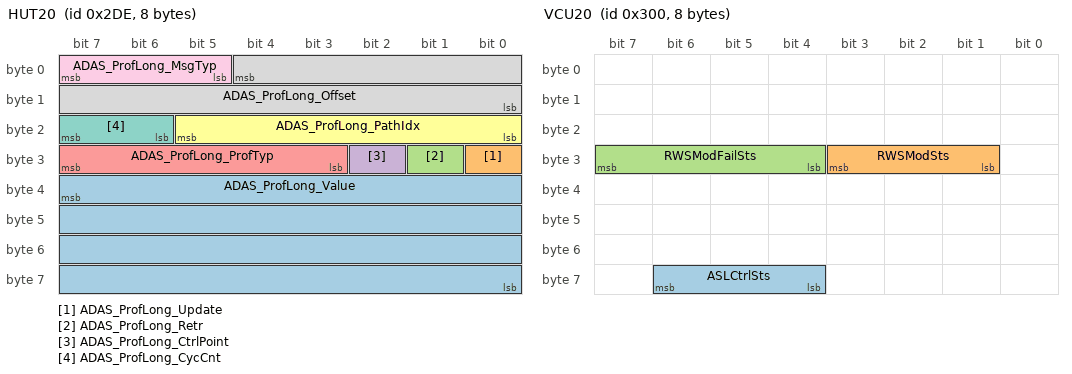
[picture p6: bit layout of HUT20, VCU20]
BO_ 734 HUT20: 8 GW
 SG_ ADAS_ProfLong_Value : 39|32@0+ (1,0) [0|4294967294] "NoUnit"  ADC10
 SG_ ADAS_ProfLong_Update : 24|1@0+ (1,0) [0|1] "NoUnit"  ADC10
 SG_ ADAS_ProfLong_Retr : 25|1@0+ (1,0) [0|1] "NoUnit"  ADC10
 SG_ ADAS_ProfLong_CtrlPoint : 26|1@0+ (1,0) [0|1] "NoUnit"  ADC10
 SG_ ADAS_ProfLong_ProfTyp : 31|5@0+ (1,0) [0|31] "NoUnit"  ADC10
 SG_ ADAS_ProfLong_PathIdx : 21|6@0+ (1,0) [0|63] "NoUnit"  ADC10
 SG_ ADAS_ProfLong_CycCnt : 23|2@0+ (1,0) [0|3] "NoUnit"  ADC10
 SG_ ADAS_ProfLong_Offset : 4|13@0+ (1,0) [0|8190] "m"  ADC10
 SG_ ADAS_ProfLong_MsgTyp : 7|3@0+ (1,0) [0|7] "NoUnit"  ADC10

BO_ 768 VCU20: 8 GW
 SG_ ASLCtrlSts : 62|3@0+ (1,0) [0|7] "NoUnit"  ADC10
 SG_ RWSModSts : 27|3@0+ (1,0) [0|7] "NoUnit"  ADC10
 SG_ RWSModFailSts : 31|4@0+ (1,0) [0|15] "NoUnit"  ADC10

BO_ 795 VCU5: 8 GW
 SG_ VCU_SysFltLvl : 62|3@0+ (1,0) [0|7] "NoUnit"  ADC10

BO_ 796 HUT13: 8 GW
 SG_ HUT_EPB_SwtPosn : 51|2@0+ (1,0) [0|3] "NoUnit"  ADC10

BO_ 799 OBC_FD2: 8 GW
 SG_ OBC_CCLineSts : 48|2@0+ (1,0) [0|3] "NoUnit"  ADC10

BO_ 822 HUT_FD10: 32 GW
 SG_ DrvImpairmAsstReq : 185|2@0+ (1,0) [0|3] "NoUnit"  ADC10

BO_ 827 HUT17: 8 GW
 SG_ LowPowerEgyMngmntModReq : 57|2@0+ (1,0) [0|3] "NoUnit"  ADC10

BO_ 829 T_BOX_FD6: 16 GW
 SG_ T_BOX_AVPActvReq : 3|2@0+ (1,0) [0|3] "NoUnit"  ADC10

BO_ 840 HUT16: 8 GW
 SG_ SentinelMode_HUT : 35|2@0+ (1,0) [0|3] "NoUnit"  ADC10

BO_ 849 ABM1: 16 GW
 SG_ MAC_Check_ABM1 : 87|48@0+ (1,0) [0|281474976710655] "NoUnit"  ADC10
 SG_ FreshnessValue_ABM1 : 71|16@0+ (1,0) [0|65535] "NoUnit"  ADC10
 SG_ RollingCounter_ABM1 : 59|4@0+ (1,0) [0|14] "NoUnit"  ADC10
 SG_ CrashSev_1 : 60|1@0+ (1,0) [0|1] "NoUnit"  ADC10
 SG_ CrashSev_2 : 61|1@0+ (1,0) [0|1] "NoUnit"  ADC10
 SG_ SecRowRSBR_Visual : 33|2@0+ (1,0) [0|3] "NoUnit"  ADC10
 SG_ DrvSBR_Visual : 25|2@0+ (1,0) [0|3] "NoUnit"  ADC10
 SG_ PassSBR_Visual : 27|2@0+ (1,0) [0|3] "NoUnit"  ADC10
 SG_ SecRowLSBR_Visual : 29|2@0+ (1,0) [0|3] "NoUnit"  ADC10
 SG_ SecRowMidSBR_Visual : 31|2@0+ (1,0) [0|3] "NoUnit"  ADC10
 SG_ CrashOutputSts : 23|8@0+ (1,0) [0|18] "NoUnit"  ADC10
 SG_ PassSBLockSts : 9|1@0+ (1,0) [0|1] "NoUnit"  ADC10
 SG_ SecRowRSBLockSts : 10|1@0+ (1,0) [0|1] "NoUnit"  ADC10
 SG_ DrvSBR : 11|1@0+ (1,0) [0|1] "NoUnit"  ADC10
 SG_ SecRowMidSBLockSts : 12|1@0+ (1,0) [0|1] "NoUnit"  ADC10
 SG_ AirbFailLmpCmd : 13|1@0+ (1,0) [0|1] "NoUnit"  ADC10
 SG_ SecRowLSBLockSts : 14|1@0+ (1,0) [0|1] "NoUnit"  ADC10
 SG_ PABSwtSts : 15|1@0+ (1,0) [0|1] "NoUnit"  ADC10
 SG_ Checksum_ABM1 : 7|8@0+ (1,0) [0|255] "NoUnit"  ADC10

BO_ 860 HUT29: 8 GW
 SG_ ValetParkingModSts : 43|2@0+ (1,0) [0|3] "NoUnit"  ADC10

BO_ 879 VCU_FD15: 64 GW
 SG_ WtrPmpSts : 285|2@0+ (1,0) [0|3] "NoUnit"  ADC10
 SG_ WtrPmpActRotSpd : 271|8@0+ (0.4,-0.4) [0|100] "Perc"  ADC10

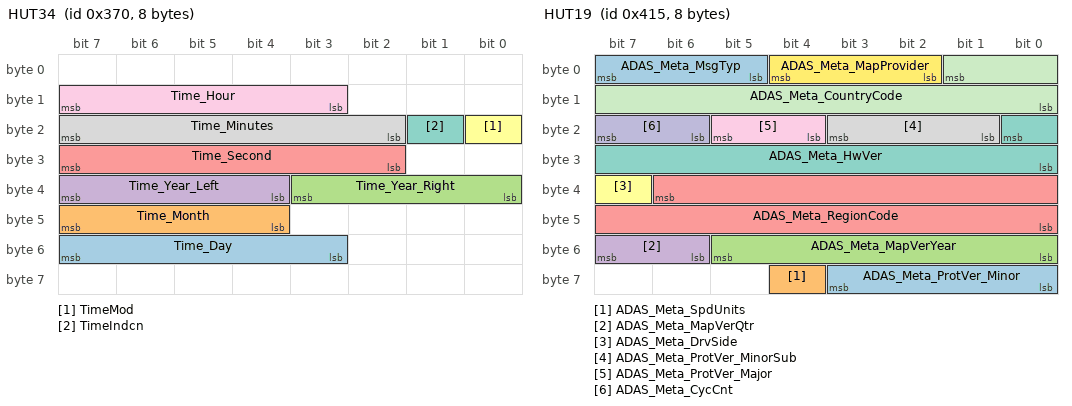
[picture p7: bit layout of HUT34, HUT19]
BO_ 880 HUT34: 8 GW
 SG_ Time_Day : 55|5@0+ (1,0) [1|31] "NoUnit"  ADC10
 SG_ Time_Month : 47|4@0+ (1,0) [0|15] "NoUnit"  ADC10
 SG_ Time_Year_Right : 35|4@0+ (1,0) [0|15] "NoUnit"  ADC10
 SG_ Time_Year_Left : 39|4@0+ (1,0) [0|15] "NoUnit"  ADC10
 SG_ Time_Second : 31|6@0+ (1,0) [0|59] "NoUnit"  ADC10
 SG_ TimeMod : 16|1@0+ (1,0) [0|1] "NoUnit"  ADC10
 SG_ TimeIndcn : 17|1@0+ (1,0) [0|1] "NoUnit"  ADC10
 SG_ Time_Minutes : 23|6@0+ (1,0) [0|59] "NoUnit"  ADC10
 SG_ Time_Hour : 15|5@0+ (1,0) [0|23] "NoUnit"  ADC10

BO_ 907 PTCC1: 24 GW
 SG_ RollingCounter_PTCC1_1 : 59|4@0+ (1,0) [0|14] "NoUnit"  ADC10
 SG_ BSCSts : 15|3@0+ (1,0) [0|7] "NoUnit"  ADC10
 SG_ Checksum_PTCC1_1 : 7|8@0+ (1,0) [0|255] "NoUnit"  ADC10

BO_ 1001 T_BOX_FD3: 16 GW
 SG_ MAC_Check_T_BOX_FD3 : 87|48@0+ (1,0) [0|281474976710655] "NoUnit"  ADC10
 SG_ FreshnessValue_T_BOX_FD3 : 71|16@0+ (1,0) [0|65535] "NoUnit"  ADC10
 SG_ T_BOX_SysErrSts : 7|5@0+ (1,0) [0|31] "NoUnit"  ADC10

BO_ 1045 HUT19: 8 GW
 SG_ ADAS_Meta_ProtVer_Minor : 59|4@0+ (1,0) [0|15] "NoUnit"  ADC10
 SG_ ADAS_Meta_SpdUnits : 60|1@0+ (1,0) [0|1] "NoUnit"  ADC10
 SG_ ADAS_Meta_MapVerYear : 53|6@0+ (1,0) [0|62] "NoUnit"  ADC10
 SG_ ADAS_Meta_MapVerQtr : 55|2@0+ (1,0) [0|3] "NoUnit"  ADC10
 SG_ ADAS_Meta_RegionCode : 38|15@0+ (1,0) [1|32766] "NoUnit"  ADC10
 SG_ ADAS_Meta_DrvSide : 39|1@0+ (1,0) [0|1] "NoUnit"  ADC10
 SG_ ADAS_Meta_HwVer : 16|9@0+ (1,0) [1|511] "NoUnit"  ADC10
 SG_ ADAS_Meta_ProtVer_MinorSub : 19|3@0+ (1,0) [0|7] "NoUnit"  ADC10
 SG_ ADAS_Meta_ProtVer_Major : 21|2@0+ (1,0) [0|3] "NoUnit"  ADC10
 SG_ ADAS_Meta_CycCnt : 23|2@0+ (1,0) [0|3] "NoUnit"  ADC10
 SG_ ADAS_Meta_CountryCode : 1|10@0+ (1,0) [1|1023] "NoUnit"  ADC10
 SG_ ADAS_Meta_MapProvider : 4|3@0+ (1,0) [0|7] "NoUnit"  ADC10
 SG_ ADAS_Meta_MsgTyp : 7|3@0+ (1,0) [0|7] "NoUnit"  ADC10

BO_ 68 HUT7: 8 GW
 SG_ CarWashModeReq : 50|2@0+ (1,0) [0|3] "NoUnit"  ADC10

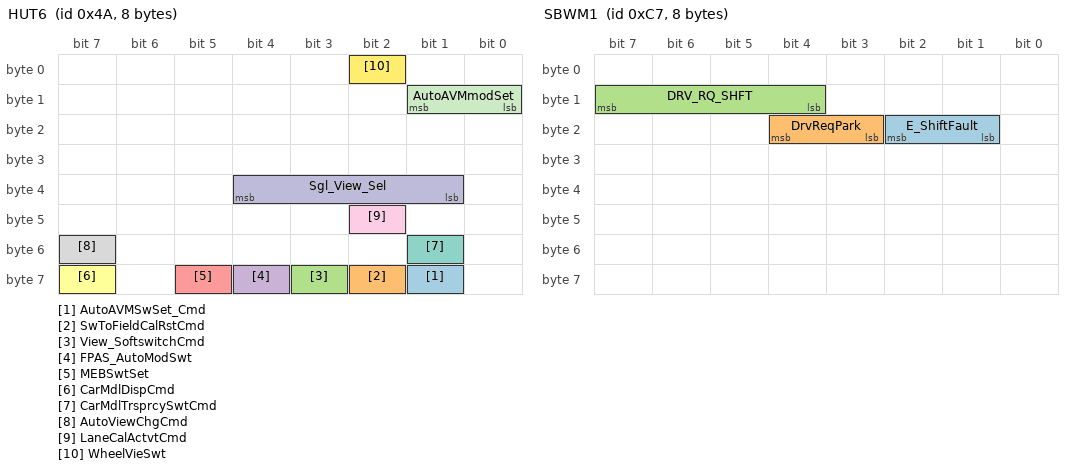
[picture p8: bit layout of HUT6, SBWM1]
BO_ 74 HUT6: 8 GW
 SG_ AutoAVMSwSet_Cmd : 57|1@0+ (1,0) [0|1] "NoUnit"  ADC10
 SG_ SwToFieldCalRstCmd : 58|1@0+ (1,0) [0|1] "NoUnit"  ADC10
 SG_ View_SoftswitchCmd : 59|1@0+ (1,0) [0|1] "NoUnit"  ADC10
 SG_ FPAS_AutoModSwt : 60|1@0+ (1,0) [0|1] "NoUnit"  ADC10
 SG_ MEBSwtSet : 61|1@0+ (1,0) [0|1] "NoUnit"  ADC10
 SG_ CarMdlDispCmd : 63|1@0+ (1,0) [0|1] "NoUnit"  ADC10
 SG_ CarMdlTrsprcySwtCmd : 49|1@0+ (1,0) [0|1] "NoUnit"  ADC10
 SG_ AutoViewChgCmd : 55|1@0+ (1,0) [0|1] "NoUnit"  ADC10
 SG_ LaneCalActvtCmd : 42|1@0+ (1,0) [0|1] "NoUnit"  ADC10
 SG_ Sgl_View_Sel : 36|4@0+ (1,0) [0|15] "NoUnit"  ADC10
 SG_ AutoAVMmodSet : 9|2@0+ (1,0) [0|3] "NoUnit"  ADC10
 SG_ WheelVieSwt : 2|1@0+ (1,0) [0|1] "NoUnit"  ADC10

BO_ 96 HCU_FD1: 64 GW
 SG_ MAC_Check_HCU_FD1 : 471|48@0+ (1,0) [0|281474976710655] "NoUnit"  ADC10
 SG_ FreshnessValue_HCU_FD1 : 455|16@0+ (1,0) [0|65535] "NoUnit"  ADC10
 SG_ RollingCounter_HCU_HP10 : 315|4@0+ (1,0) [0|14] "NoUnit"  ADC10
 SG_ HCU_PowertrainSts : 303|5@0+ (1,0) [0|31] "NoUnit"  ADC10
 SG_ Checksum_HCU_HP10 : 263|8@0+ (1,0) [0|255] "NoUnit"  ADC10
 SG_ RollingCounter_HCU_PT1 : 123|4@0+ (1,0) [0|14] "NoUnit"  ADC10
 SG_ ActWheelTrqDmd : 83|12@0+ (5,-6000) [-6000|14475] "Nm"  ADC10
 SG_ Checksum_HCU_PT1 : 71|8@0+ (1,0) [0|255] "NoUnit"  ADC10

BO_ 161 CSA2: 8 GW
 SG_ RollingCounter_CSA2 : 59|4@0+ (1,0) [0|14] "NoUnit"  ADC10
 SG_ HWA_OK_OFFSwt : 60|1@0+ (1,0) [0|1] "NoUnit"  ADC10
 SG_ ManualShiftReq : 63|3@0+ (1,0) [0|7] "NoUnit"  ADC10
 SG_ CC_ACCSwtErr : 48|1@0+ (1,0) [0|1] "NoUnit"  ADC10
 SG_ ACCTimeGapSetSwt : 49|1@0+ (1,0) [0|1] "NoUnit"  ADC10
 SG_ CC_ACC_DecSetSpd_SetSwt : 50|1@0+ (1,0) [0|1] "NoUnit"  ADC10
 SG_ CC_ACC_IncSetSpd_ResuSwt : 51|1@0+ (1,0) [0|1] "NoUnit"  ADC10
 SG_ SAS_Sts : 55|2@0+ (1,0) [0|3] "NoUnit"  ADC10
 SG_ ACC_TimeGap_DecSetSwt : 44|1@0+ (1,0) [0|1] "NoUnit"  ADC10
 SG_ ACC_TimeGap_IncSetSwt : 45|1@0+ (1,0) [0|1] "NoUnit"  ADC10
 SG_ CC_ACC_CANCEL_OFFSwt : 46|1@0+ (1,0) [0|1] "NoUnit"  ADC10
 SG_ CC_ACC_CRUISE_OFFSwt : 47|1@0+ (1,0) [0|1] "NoUnit"  ADC10
 SG_ SteerWheelSpdSign : 32|1@0+ (1,0) [0|1] "NoUnit"  ADC10
 SG_ SteerWheelSpd : 31|15@0+ (0.1,0) [0|1016] "DegPerSec"  ADC10
 SG_ SteerWheelAngSign : 16|1@0+ (1,0) [0|1] "NoUnit"  ADC10
 SG_ SteerWheelAng : 15|15@0+ (0.1,0) [0|780] "Deg"  ADC10
 SG_ Checksum_CSA2 : 7|8@0+ (1,0) [0|255] "NoUnit"  ADC10

BO_ 181 VCU_FD1: 64 GW
 SG_ MAC_Check_VCU_FD1 : 471|48@0+ (1,0) [0|281474976710655] "NoUnit"  ADC10
 SG_ FreshnessValue_VCU_FD1 : 455|16@0+ (1,0) [0|65535] "NoUnit"  ADC10
 SG_ RollingCounter_VCU15 : 315|4@0+ (1,0) [0|14] "NoUnit"  ADC10
 SG_ VCU_RespHWP : 296|1@0+ (1,0) [0|1] "NoUnit"  ADC10
 SG_ VCU_HWPInterface : 289|2@0+ (1,0) [0|3] "NoUnit"  ADC10
 SG_ VCU_HWPInterErrReason : 287|4@0+ (1,0) [0|15] "NoUnit"  ADC10
 SG_ VCU_DrvrIntvGearSts : 271|1@0+ (1,0) [0|1] "NoUnit"  ADC10
 SG_ Checksum_VCU15 : 263|8@0+ (1,0) [0|255] "NoUnit"  ADC10
 SG_ RollingCounter_VCU6 : 251|4@0+ (1,0) [0|14] "NoUnit"  ADC10
 SG_ VCU_ActAccrPedlRat : 247|8@0+ (0.3937,0) [0|100.3935] "Perc"  ADC10
 SG_ VCU_AutParkAvlSts : 227|1@0+ (1,0) [0|1] "NoUnit"  ADC10
 SG_ VCU_BrkPedlSts : 217|2@0+ (1,0) [0|3] "NoUnit"  ADC10
 SG_ HCU_BrkPedalStsValid : 218|1@0+ (1,0) [0|1] "NoUnit"  ADC10
 SG_ VCU_APedlPosVld : 219|1@0+ (1,0) [0|1] "NoUnit"  ADC10
 SG_ VCU_AccelPedalPosnValid : 220|1@0+ (1,0) [0|1] "NoUnit"  ADC10
 SG_ VCU_VirtAccrPedlRat : 207|8@0+ (0.3937,0) [0|100.3935] "Perc"  ADC10
 SG_ Checksum_VCU6 : 199|8@0+ (1,0) [0|255] "NoUnit"  ADC10

BO_ 188 RWS1: 16 GW
 SG_ RWS_FailSts : 63|2@0+ (1,0) [0|3] "NoUnit"  ADC10
 SG_ RWS_SteerSpd : 38|9@0+ (0.1,-0.1) [0|27] "DegPerSec"  ADC10
 SG_ RWS_SteerSpdVld : 39|1@0+ (1,0) [0|1] "NoUnit"  ADC10
 SG_ RWS_AngActVld : 24|1@0+ (1,0) [0|1] "NoUnit"  ADC10
 SG_ RWS_AngAct : 23|12@0+ (0.01,-10) [-10|10] "Deg"  ADC10
 SG_ RWS_StsResp : 15|2@0+ (1,0) [0|3] "NoUnit"  ADC10

BO_ 189 ESP_FD1: 16 GW
 SG_ RollingCounter_ESP12 : 123|4@0+ (1,0) [0|14] "NoUnit"  ADC10
 SG_ ESP_VehHldSts : 107|1@0+ (1,0) [0|1] "NoUnit"  ADC10
 SG_ TgtRcprtnTrqReq : 79|14@0+ (1,-16383) [-16383|0] "Nm"  ADC10
 SG_ Checksum_ESP12 : 71|8@0+ (1,0) [0|255] "NoUnit"  ADC10
 SG_ TgtRcprtnTrqSts : 53|2@0+ (1,0) [0|3] "NoUnit"  ADC10

BO_ 199 SBWM1: 8 GW
 SG_ E_ShiftFault : 18|2@0+ (1,0) [0|3] "NoUnit"  ADC10
 SG_ DrvReqPark : 20|2@0+ (1,0) [0|3] "NoUnit"  ADC10
 SG_ DRV_RQ_SHFT : 15|4@0+ (1,0) [0|15] "NoUnit"  ADC10

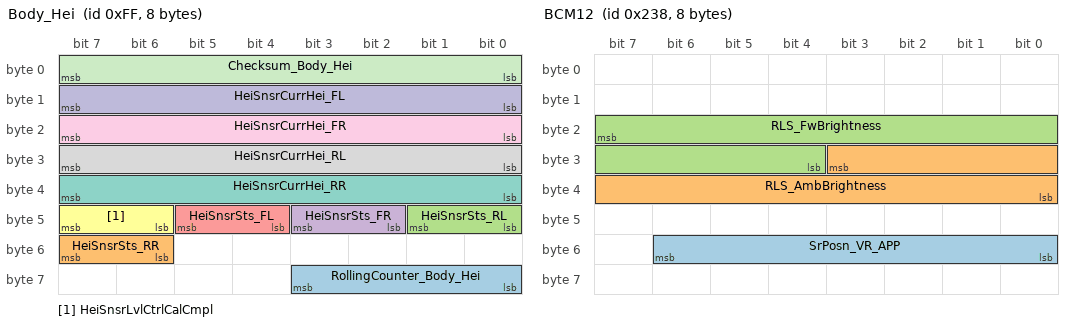
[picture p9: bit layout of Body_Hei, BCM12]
BO_ 255 Body_Hei: 8 GW
 SG_ RollingCounter_Body_Hei : 59|4@0+ (1,0) [0|14] "NoUnit"  ADC10
 SG_ HeiSnsrSts_RR : 55|2@0+ (1,0) [0|3] "NoUnit"  ADC10
 SG_ HeiSnsrSts_RL : 41|2@0+ (1,0) [0|3] "NoUnit"  ADC10
 SG_ HeiSnsrSts_FR : 43|2@0+ (1,0) [0|3] "NoUnit"  ADC10
 SG_ HeiSnsrSts_FL : 45|2@0+ (1,0) [0|3] "NoUnit"  ADC10
 SG_ HeiSnsrLvlCtrlCalCmpl : 47|2@0+ (1,0) [0|3] "NoUnit"  ADC10
 SG_ HeiSnsrCurrHei_RR : 39|8@0+ (1.2,-151.2) [-150|153.6] "mm"  ADC10
 SG_ HeiSnsrCurrHei_RL : 31|8@0+ (1.2,-151.2) [-150|153.6] "mm"  ADC10
 SG_ HeiSnsrCurrHei_FR : 23|8@0+ (1.2,-151.2) [-150|153.6] "mm"  ADC10
 SG_ HeiSnsrCurrHei_FL : 15|8@0+ (1.2,-151.2) [-150|153.6] "mm"  ADC10
 SG_ Checksum_Body_Hei : 7|8@0+ (1,0) [0|255] "NoUnit"  ADC10

BO_ 473 GW_OTA: 8 ZCU_L
 SG_ OTApowertrainmode : 12|2@0+ (1,0) [0|3] "NoUnit"  ADC10

BO_ 568 BCM12: 8 ZCU_L
 SG_ SrPosn_VR_APP : 54|7@0+ (1,0) [0|127] "NoUnit"  ADC10
 SG_ RLS_AmbBrightness : 27|12@0+ (20,0) [0|81880] "lx"  ADC10
 SG_ RLS_FwBrightness : 23|12@0+ (6,0) [0|24564] "lx"  ADC10

BO_ 569 GW1: 8 ZCU_L
 SG_ BasicFunReq : 31|8@0+ (1,0) [1|254] "NoUnit"  ADC10
 SG_ BasicFunID : 23|8@0+ (1,0) [1|254] "NoUnit"  ADC10

BO_ 597 ZCU_L1: 8 ZCU_L
 SG_ PhyHazardSwt : 63|1@0+ (1,0) [0|1] "NoUnit"  ADC10
 SG_ RFPosnLmpFailSts_Zone : 40|1@0+ (1,0) [0|1] "NoUnit"  ADC10
 SG_ LFPosnLmpFailSts_Zone : 41|1@0+ (1,0) [0|1] "NoUnit"  ADC10
 SG_ RFTurnLmpFailSts_Zone : 42|1@0+ (1,0) [0|1] "NoUnit"  ADC10
 SG_ LFTurnLmpFailSts_Zone : 43|1@0+ (1,0) [0|1] "NoUnit"  ADC10
 SG_ RLowBeamFailSts_Zone : 46|1@0+ (1,0) [0|1] "NoUnit"  ADC10
 SG_ LLowBeamFailSts_Zone : 47|1@0+ (1,0) [0|1] "NoUnit"  ADC10
 SG_ RHiBeamFailSts_Zone : 32|1@0+ (1,0) [0|1] "NoUnit"  ADC10
 SG_ LHiBeamFailSts_Zone : 33|1@0+ (1,0) [0|1] "NoUnit"  ADC10
 SG_ HiPosnBrkLmpFailSts_Zone : 35|1@0+ (1,0) [0|1] "NoUnit"  ADC10
 SG_ RRFogLmpFailSts_Zone : 38|1@0+ (1,0) [0|1] "NoUnit"  ADC10
 SG_ LRFogLmpFailSts_Zone : 39|1@0+ (1,0) [0|1] "NoUnit"  ADC10
 SG_ RFFogLmpFailSts_Zone : 24|1@0+ (1,0) [0|1] "NoUnit"  ADC10
 SG_ LFFogLmpFailSts_Zone : 25|1@0+ (1,0) [0|1] "NoUnit"  ADC10
 SG_ RBrkLmpFailSts_Zone : 26|1@0+ (1,0) [0|1] "NoUnit"  ADC10
 SG_ LBrkLmpFailSts_Zone : 27|1@0+ (1,0) [0|1] "NoUnit"  ADC10
 SG_ RRPosnLmpFailSts_Zone : 28|1@0+ (1,0) [0|1] "NoUnit"  ADC10
 SG_ LRPosnLmpFailSts_Zone : 29|1@0+ (1,0) [0|1] "NoUnit"  ADC10
 SG_ RRTurnLmpFailSts_Zone : 30|1@0+ (1,0) [0|1] "NoUnit"  ADC10
 SG_ LRTurnLmpFailSts_Zone : 31|1@0+ (1,0) [0|1] "NoUnit"  ADC10
 SG_ HiPosnBrkLmpOutpSts_Zone : 22|1@0+ (1,0) [0|1] "NoUnit"  ADC10
 SG_ PosnLmpOutpSts_Zone : 23|1@0+ (1,0) [0|1] "NoUnit"  ADC10
 SG_ RBrkLmpOutpSts_Zone : 8|1@0+ (1,0) [0|1] "NoUnit"  ADC10
 SG_ LBrkLmpOutpSts_Zone : 9|1@0+ (1,0) [0|1] "NoUnit"  ADC10
 SG_ RFogLmpSts_Zone : 10|1@0+ (1,0) [0|1] "NoUnit"  ADC10
 SG_ FFogLmpSts_Zone : 11|1@0+ (1,0) [0|1] "NoUnit"  ADC10
 SG_ RTurnLmpSts_Zone : 12|1@0+ (1,0) [0|1] "NoUnit"  ADC10
 SG_ LTurnLmpSts_Zone : 13|1@0+ (1,0) [0|1] "NoUnit"  ADC10
 SG_ LowBeamSts_Zone : 14|1@0+ (1,0) [0|1] "NoUnit"  ADC10
 SG_ HiBeamSts_Zone : 15|1@0+ (1,0) [0|1] "NoUnit"  ADC10

BO_ 661 PEPS2: 8 ZCU_L
 SG_ SysPowerModVld : 13|1@0+ (1,0) [0|1] "NoUnit"  ADC10
 SG_ SysPowerMod : 15|2@0+ (1,0) [0|3] "NoUnit"  ADC10

BO_ 669 AC1: 8 ZCU_L
 SG_ InCarTemp : 15|8@0+ (0.5,-40) [-40|86.5] "DegC"  ADC10

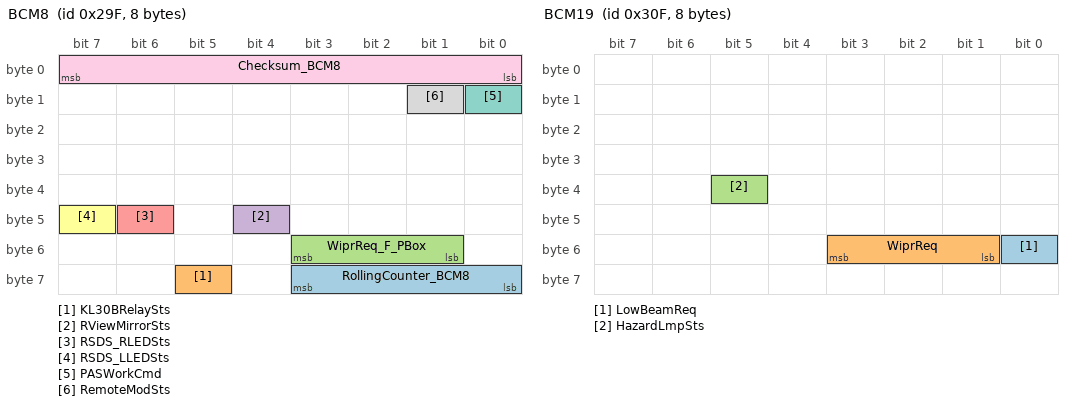
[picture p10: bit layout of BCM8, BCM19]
BO_ 671 BCM8: 8 ZCU_L
 SG_ RollingCounter_BCM8 : 59|4@0+ (1,0) [0|14] "NoUnit"  ADC10
 SG_ KL30BRelaySts : 61|1@0+ (1,0) [0|1] "NoUnit"  ADC10
 SG_ WiprReq_F_PBox : 51|3@0+ (1,0) [0|7] "NoUnit"  ADC10
 SG_ RViewMirrorSts : 44|1@0+ (1,0) [0|1] "NoUnit"  ADC10
 SG_ RSDS_RLEDSts : 46|1@0+ (1,0) [0|1] "NoUnit"  ADC10
 SG_ RSDS_LLEDSts : 47|1@0+ (1,0) [0|1] "NoUnit"  ADC10
 SG_ PASWorkCmd : 8|1@0+ (1,0) [0|1] "NoUnit"  ADC10
 SG_ RemoteModSts : 9|1@0+ (1,0) [0|1] "NoUnit"  ADC10
 SG_ Checksum_BCM8 : 7|8@0+ (1,0) [0|255] "NoUnit"  ADC10

BO_ 680 EEM1: 8 ZCU_L
 SG_ TranPMode_Sts : 7|1@0+ (1,0) [0|1] "NoUnit"  ADC10

BO_ 688 DRDCM1: 8 ZCU_L
 SG_ DrvRearDoorWinPosnSts_Perc : 15|5@0+ (1,0) [0|31] "NoUnit"  ADC10

BO_ 699 GW_FD1: 64 ZCU_L
 SG_ OTA_UpgrdModSts : 343|2@0+ (1,0) [0|3] "NoUnit"  ADC10

BO_ 714 DDCM1: 8 ZCU_L
 SG_ DrvWinPosnSts_Perc : 42|5@0+ (1,0) [0|31] "NoUnit"  ADC10
 SG_ RSDS_Driver_LED_Sts : 9|1@0+ (1,0) [0|1] "NoUnit"  ADC10

BO_ 770 PEPS4: 8 ZCU_L
 SG_ WarnKeyInCarWhenExit : 10|1@0+ (1,0) [0|1] "NoUnit"  ADC10

BO_ 783 BCM19: 8 ZCU_L
 SG_ LowBeamReq : 48|1@0+ (1,0) [0|1] "NoUnit"  ADC10
 SG_ WiprReq : 51|3@0+ (1,0) [0|7] "NoUnit"  ADC10
 SG_ HazardLmpSts : 37|1@0+ (1,0) [0|1] "NoUnit"  ADC10

BO_ 793 BCM1: 16 ZCU_L
 SG_ MAC_Check_BCM1 : 87|48@0+ (1,0) [0|281474976710655] "NoUnit"  ADC10
 SG_ FreshnessValue_BCM1 : 71|16@0+ (1,0) [0|65535] "NoUnit"  ADC10
 SG_ RollingCounter_BCM1 : 59|4@0+ (1,0) [0|14] "NoUnit"  ADC10
 SG_ RLSFailSts : 63|1@0+ (1,0) [0|1] "NoUnit"  ADC10
 SG_ HoodSts : 40|1@0+ (1,0) [0|1] "NoUnit"  ADC10
 SG_ WindshldWiprActvSts : 17|1@0+ (1,0) [0|1] "NoUnit"  ADC10
 SG_ RRDoorSts : 19|1@0+ (1,0) [0|1] "NoUnit"  ADC10
 SG_ PassengerDoorSts : 20|1@0+ (1,0) [0|1] "NoUnit"  ADC10
 SG_ LRDoorSts : 21|1@0+ (1,0) [0|1] "NoUnit"  ADC10
 SG_ DrvDoorSts : 22|1@0+ (1,0) [0|1] "NoUnit"  ADC10
 SG_ TrunkSts : 23|1@0+ (1,0) [0|1] "NoUnit"  ADC10
 SG_ Checksum_BCM1 : 7|8@0+ (1,0) [0|255] "NoUnit"  ADC10

BO_ 833 TPMS1: 16 ZCU_L
 SG_ MAC_Check_TPMS1 : 87|48@0+ (1,0) [0|281474976710655] "NoUnit"  ADC10
 SG_ FreshnessValue_TPMS1 : 71|16@0+ (1,0) [0|65535] "NoUnit"  ADC10
 SG_ TPMS_AutoLoctSts : 39|4@0+ (1,0) [0|5] "NoUnit"  ADC10
 SG_ RRTireTempSts : 25|2@0+ (1,0) [0|3] "NoUnit"  ADC10
 SG_ RLTireTempSts : 27|2@0+ (1,0) [0|3] "NoUnit"  ADC10
 SG_ FRTireTempSts : 29|2@0+ (1,0) [0|3] "NoUnit"  ADC10
 SG_ FLTireTempSts : 31|2@0+ (1,0) [0|3] "NoUnit"  ADC10
 SG_ RRTirePressIndSts : 20|3@0+ (1,0) [0|7] "NoUnit"  ADC10
 SG_ RLTirePressIndSts : 23|3@0+ (1,0) [0|7] "NoUnit"  ADC10
 SG_ TirePressSysFailrIndcn : 9|2@0+ (1,0) [0|3] "NoUnit"  ADC10
 SG_ FRTirePressIndSts : 12|3@0+ (1,0) [0|7] "NoUnit"  ADC10
 SG_ FLTirePressIndSts : 15|3@0+ (1,0) [0|7] "NoUnit"  ADC10

BO_ 837 BCM3: 16 ZCU_L
 SG_ MAC_Check_BCM3 : 87|48@0+ (1,0) [0|281474976710655] "NoUnit"  ADC10
 SG_ FreshnessValue_BCM3 : 71|16@0+ (1,0) [0|65535] "NoUnit"  ADC10
 SG_ EnvModDetn : 44|2@0+ (1,0) [0|3] "NoUnit"  ADC10
 SG_ DrvDoorLockSts : 34|1@0+ (1,0) [0|1] "NoUnit"  ADC10

BO_ 901 AC2: 8 ZCU_L
 SG_ ACAmbTemp : 23|8@0+ (0.5,-40) [-40|86.5] "DegC"  ADC10
 SG_ ACFrntBlwrSpd : 11|4@0+ (1,0) [0|15] "NoUnit"  ADC10

BO_ 917 TPMS2: 16 ZCU_L
 SG_ RRTireTemp : 63|8@0+ (1,-50) [-50|204] "DegC"  ADC10
 SG_ RRTirePress : 55|8@0+ (1.3725,0) [0|348.615] "kPa"  ADC10
 SG_ RLTireTemp : 47|8@0+ (1,-50) [-50|204] "DegC"  ADC10
 SG_ RLTirePress : 39|8@0+ (1.3725,0) [0|348.615] "kPa"  ADC10
 SG_ FRTireTemp : 31|8@0+ (1,-50) [-50|204] "DegC"  ADC10
 SG_ FRTirePress : 23|8@0+ (1.3725,0) [0|348.615] "kPa"  ADC10
 SG_ FLTireTemp : 15|8@0+ (1,-50) [-50|204] "DegC"  ADC10
 SG_ FLTirePress : 7|8@0+ (1.3725,0) [0|348.615] "kPa"  ADC10

BO_ 1121 CEM_Sync: 16 ZCU_L
 SG_ CEM_Sync : 7|128@0+ (1,0) [0|0] ""  ADC10

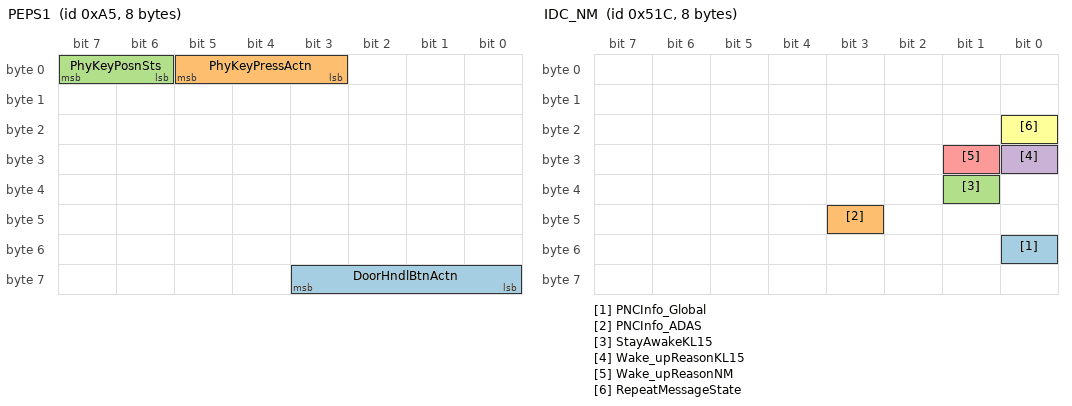
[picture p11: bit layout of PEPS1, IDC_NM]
BO_ 165 PEPS1: 8 ZCU_L
 SG_ DoorHndlBtnActn : 59|4@0+ (1,0) [0|15] "NoUnit"  ADC10
 SG_ PhyKeyPressActn : 5|3@0+ (1,0) [0|7] "NoUnit"  ADC10
 SG_ PhyKeyPosnSts : 7|2@0+ (1,0) [0|3] "NoUnit"  ADC10

BO_ 1308 IDC_NM: 8 ADC10
 SG_ PNCInfo_Global : 48|1@0+ (1,0) [0|1] "" Vector__XXX
 SG_ PNCInfo_ADAS : 43|1@0+ (1,0) [0|1] "" Vector__XXX
 SG_ StayAwakeKL15 : 33|1@0+ (1,0) [0|1] "" Vector__XXX
 SG_ Wake_upReasonKL15 : 24|1@0+ (1,0) [0|1] "" Vector__XXX
 SG_ Wake_upReasonNM : 25|1@0+ (1,0) [0|1] "" Vector__XXX
 SG_ RepeatMessageState : 16|1@0+ (1,0) [0|1] "" Vector__XXX

BO_ 1493 FR_DTC_Code: 64 ADC10
 SG_ FR_DTC_Code : 7|507@0+ (1,0) [0|4.18993997810706E+152] "NoUnit" Vector__XXX

BO_ 1751 IDC_Phy_Req: 8 Tester
 SG_ IDC_Phy_Req : 7|64@0+ (1,0) [0|1.84467440737096E+019] ""  ADC10

BO_ 1888 DiagFuncReq: 8 Tester
 SG_ DiagFuncReq : 7|64@0+ (1,0) [0|1.84467440737096E+019] ""  ADC10

BO_ 1906 FR_Phy_Req: 8 Tester
 SG_ FR_Phy_Req : 7|64@0+ (1,0) [0|1.84467440737096E+019] ""  ADC10

BO_ 1759 IDC_Phy_Resp: 8 ADC10
 SG_ IDC_Phy_Resp : 7|64@0+ (1,0) [0|1.84467440737096E+019] ""  Tester

BO_ 1970 FR_Phy_Resp: 8 ADC10
 SG_ FR_Phy_Resp : 7|64@0+ (1,0) [0|1.84467440737096E+019] "" Vector__XXX

CM_ SG_ 283 AccrPedlAntiMsstpngSts "/";
CM_ SG_ 283 VCU_DrvReqTqWhl "/";
CM_ SG_ 283 RollingCounter_VCU21 "/";
CM_ SG_ 283 Checksum_VCU21 "/";
CM_ SG_ 283 ActDrvMod "/";
CM_ SG_ 346 RollingCounter_LBM2 "/";
CM_ SG_ 346 LBMPackVoltageASIL "ASIL B ";
CM_ SG_ 346 Checksum_LBM2 "/";
CM_ SG_ 388 RollingCounter_VCU_FD28_2 "/";
CM_ SG_ 388 RRIntgrtdWheelSpd "/";
CM_ SG_ 388 RLIntgrtdWheelSpd "/";
CM_ SG_ 388 Checksum_VCU_FD28_2 "/";
CM_ SG_ 388 RollingCounter_VCU_FD28_1 "/";
CM_ SG_ 388 EstimrResutReliabt "/";
CM_ SG_ 388 EstimdRoadFricCoeff "/";
CM_ SG_ 388 FRIntgrtdWheelSpd "/";
CM_ SG_ 388 FLIntgrtdWheelSpd "/";
CM_ SG_ 388 IntgrtdVehSpd "/";
CM_ SG_ 388 Checksum_VCU_FD28_1 "/";
CM_ SG_ 474 TSRLimSpdChngSoundSet "/";
CM_ SG_ 474 ACC_OverTakingAsscSet "/";
CM_ SG_ 474 TJA_ASCruise "A";
CM_ SG_ 474 PrkgSlotId "/";
CM_ SG_ 474 HAVP_UseMod "/";
CM_ SG_ 474 BackReq_RPA "/";
CM_ SG_ 545 TGS_LEVERValid "/";
CM_ SG_ 589 DrvGazSts "/";
CM_ SG_ 629 RollingCounter_Trailer2 "ASIL A";
CM_ SG_ 629 TrailerStatusVld "ASIL A";
CM_ SG_ 629 TrailerStatus "ASIL A";
CM_ SG_ 629 Checksum_Trailer2 "ASIL A";
CM_ SG_ 639 IP_VehTotDistanceValid "B";
CM_ SG_ 639 IP_VehTotDistance "B";
CM_ SG_ 707 IntellgntcurveReq "/";
CM_ SG_ 726 VCU_LTRadrOutlWtrTemp "/";
CM_ SG_ 726 VCU_WtrPmpOpenRateCtrl "/";
CM_ SG_ 726 VCU_RdyLEDSts "/";
CM_ SG_ 879 WtrPmpSts "/";
CM_ SG_ 879 WtrPmpActRotSpd "/";
CM_ SG_ 161 HWA_OK_OFFSwt "B";
CM_ SG_ 161 CC_ACCSwtErr "A";
CM_ SG_ 161 CC_ACC_DecSetSpd_SetSwt "A";
CM_ SG_ 161 CC_ACC_IncSetSpd_ResuSwt "A";
CM_ SG_ 161 ACC_TimeGap_DecSetSwt "A";
CM_ SG_ 161 ACC_TimeGap_IncSetSwt "A";
CM_ SG_ 161 CC_ACC_CANCEL_OFFSwt "A";
CM_ SG_ 161 CC_ACC_CRUISE_OFFSwt "A";
CM_ SG_ 181 VCU_DrvrIntvGearSts "/";
CM_ SG_ 181 HCU_BrkPedalStsValid "/";
CM_ SG_ 181 VCU_AccelPedalPosnValid "/";
CM_ SG_ 837 EnvModDetn "/";
BA_DEF_ BO_  "GenMsgILSupport" ENUM  "No","Yes";
BA_DEF_ BO_  "VFrameFormat" ENUM  "StandardCAN","ExtendedCAN","reserved","reserved","reserved","reserved","reserved","reserved","reserved","reserved","reserved","reserved","reserved","reserved","StandardCAN_FD","ExtendedCAN_FD";
BA_DEF_ BO_  "DiagState" ENUM  "No","Yes";
BA_DEF_ BO_  "DiagRequest" ENUM  "No","Yes";
BA_DEF_ BO_  "DiagResponse" ENUM  "No","Yes";
BA_DEF_ BO_  "NmAsrMessage" ENUM  "No","Yes";
BA_DEF_ SG_  "GenSigSendType" ENUM  "Cyclic","OnWrite","OnWriteWithRepetition","OnChange","OnChangeWithRepetition","IfActive","IfActiveWithRepetition","NoSigSendType","CyclicAndSpontanX","NotUsed","Event","CE";
BA_DEF_ SG_  "IsMonitor" ENUM  "*","Monitor";
BA_DEF_ SG_  "NormValue" STRING ;
BA_DEF_ SG_  "UnitConversionFactor" FLOAT -100 100;
BA_DEF_ SG_  "SigInvalidSetFlag" ENUM  "*","Yes";
BA_DEF_ SG_  "Internal_type" ENUM  "*","UB","UW","UL","SB","SW","SL";
BA_DEF_ SG_  "IsCrcSignal" ENUM  "No","Yes";
BA_DEF_ SG_  "IsRcSignal" ENUM  "No","Yes";
BA_DEF_ BO_  "GenMsgSendType" ENUM  "Cyclic","Event","CE","NotUsed","NotUsed","NotUsed","NotUsed","NotUsed","NoMsgSendType","IfActive","IfActiveWithRepetition","CyclicAndSpontanX";
BA_DEF_ SG_  "GenSigStartValue" INT 0 2147483647;
BA_DEF_ BO_  "MsgType" ENUM  "Normal","NM","Diag","vector_leerstring";
BA_DEF_ BO_  "GenMsgCycleTime" INT 0 65535;
BA_DEF_DEF_  "GenMsgILSupport" "Yes";
BA_DEF_DEF_  "VFrameFormat" "StandardCAN";
BA_DEF_DEF_  "DiagState" "No";
BA_DEF_DEF_  "DiagRequest" "No";
BA_DEF_DEF_  "DiagResponse" "No";
BA_DEF_DEF_  "NmAsrMessage" "No";
BA_DEF_DEF_  "GenSigSendType" "Cyclic";
BA_DEF_DEF_  "IsMonitor" "*";
BA_DEF_DEF_  "NormValue" "";
BA_DEF_DEF_  "UnitConversionFactor" 1;
BA_DEF_DEF_  "SigInvalidSetFlag" "*";
BA_DEF_DEF_  "Internal_type" "*";
BA_DEF_DEF_  "IsCrcSignal" "No";
BA_DEF_DEF_  "IsRcSignal" "No";
BA_DEF_DEF_  "GenMsgSendType" "Cyclic";
BA_DEF_DEF_  "GenSigStartValue" 0;
BA_DEF_DEF_  "MsgType" "";
BA_DEF_DEF_  "GenMsgCycleTime" 0;
BA_ "GenMsgCycleTime" BO_ 719 100;
BA_ "MsgType" BO_ 719 0;
BA_ "VFrameFormat" BO_ 719 14;
BA_ "GenMsgCycleTime" BO_ 846 500;
BA_ "MsgType" BO_ 846 0;
BA_ "VFrameFormat" BO_ 846 14;
BA_ "GenMsgCycleTime" BO_ 259 20;
BA_ "MsgType" BO_ 259 0;
BA_ "VFrameFormat" BO_ 259 14;
BA_ "GenMsgCycleTime" BO_ 273 10;
BA_ "MsgType" BO_ 273 0;
BA_ "VFrameFormat" BO_ 273 14;
BA_ "GenMsgCycleTime" BO_ 283 20;
BA_ "MsgType" BO_ 283 0;
BA_ "VFrameFormat" BO_ 283 14;
BA_ "GenMsgCycleTime" BO_ 295 20;
BA_ "MsgType" BO_ 295 0;
BA_ "VFrameFormat" BO_ 295 14;
BA_ "GenMsgCycleTime" BO_ 302 20;
BA_ "MsgType" BO_ 302 0;
BA_ "VFrameFormat" BO_ 302 14;
BA_ "GenMsgCycleTime" BO_ 311 20;
BA_ "MsgType" BO_ 311 0;
BA_ "VFrameFormat" BO_ 311 14;
BA_ "GenMsgCycleTime" BO_ 315 20;
BA_ "MsgType" BO_ 315 0;
BA_ "VFrameFormat" BO_ 315 14;
BA_ "GenMsgCycleTime" BO_ 320 20;
BA_ "MsgType" BO_ 320 0;
BA_ "VFrameFormat" BO_ 320 14;
BA_ "GenMsgCycleTime" BO_ 326 20;
BA_ "MsgType" BO_ 326 0;
BA_ "VFrameFormat" BO_ 326 14;
BA_ "GenMsgCycleTime" BO_ 327 20;
BA_ "MsgType" BO_ 327 0;
BA_ "VFrameFormat" BO_ 327 14;
BA_ "GenMsgCycleTime" BO_ 332 20;
BA_ "MsgType" BO_ 332 0;
BA_ "VFrameFormat" BO_ 332 14;
BA_ "GenMsgCycleTime" BO_ 346 20;
BA_ "MsgType" BO_ 346 0;
BA_ "VFrameFormat" BO_ 346 14;
BA_ "GenMsgCycleTime" BO_ 356 20;
BA_ "MsgType" BO_ 356 0;
BA_ "VFrameFormat" BO_ 356 14;
BA_ "GenMsgCycleTime" BO_ 357 20;
BA_ "MsgType" BO_ 357 0;
BA_ "VFrameFormat" BO_ 357 14;
BA_ "GenMsgCycleTime" BO_ 367 20;
BA_ "MsgType" BO_ 367 0;
BA_ "VFrameFormat" BO_ 367 14;
BA_ "GenMsgCycleTime" BO_ 388 20;
BA_ "MsgType" BO_ 388 0;
BA_ "VFrameFormat" BO_ 388 14;
BA_ "MsgType" BO_ 474 0;
BA_ "GenMsgSendType" BO_ 474 1;
BA_ "VFrameFormat" BO_ 474 14;
BA_ "MsgType" BO_ 489 0;
BA_ "GenMsgSendType" BO_ 489 1;
BA_ "VFrameFormat" BO_ 489 14;
BA_ "MsgType" BO_ 490 0;
BA_ "GenMsgSendType" BO_ 490 1;
BA_ "VFrameFormat" BO_ 490 14;
BA_ "MsgType" BO_ 493 0;
BA_ "GenMsgSendType" BO_ 493 1;
BA_ "VFrameFormat" BO_ 493 14;
BA_ "MsgType" BO_ 494 0;
BA_ "GenMsgSendType" BO_ 494 1;
BA_ "VFrameFormat" BO_ 494 14;
BA_ "GenMsgCycleTime" BO_ 545 20;
BA_ "MsgType" BO_ 545 0;
BA_ "VFrameFormat" BO_ 545 14;
BA_ "GenMsgCycleTime" BO_ 555 50;
BA_ "MsgType" BO_ 555 0;
BA_ "VFrameFormat" BO_ 555 14;
BA_ "GenMsgCycleTime" BO_ 570 50;
BA_ "MsgType" BO_ 570 0;
BA_ "VFrameFormat" BO_ 570 14;
BA_ "GenMsgCycleTime" BO_ 579 50;
BA_ "MsgType" BO_ 579 0;
BA_ "VFrameFormat" BO_ 579 14;
BA_ "GenMsgCycleTime" BO_ 580 50;
BA_ "MsgType" BO_ 580 0;
BA_ "VFrameFormat" BO_ 580 14;
BA_ "GenMsgCycleTime" BO_ 581 20;
BA_ "MsgType" BO_ 581 0;
BA_ "VFrameFormat" BO_ 581 14;
BA_ "GenMsgCycleTime" BO_ 589 50;
BA_ "MsgType" BO_ 589 0;
BA_ "VFrameFormat" BO_ 589 14;
BA_ "GenMsgCycleTime" BO_ 596 50;
BA_ "MsgType" BO_ 596 0;
BA_ "VFrameFormat" BO_ 596 14;
BA_ "GenMsgCycleTime" BO_ 604 50;
BA_ "MsgType" BO_ 604 0;
BA_ "VFrameFormat" BO_ 604 14;
BA_ "GenMsgCycleTime" BO_ 623 50;
BA_ "MsgType" BO_ 623 0;
BA_ "VFrameFormat" BO_ 623 14;
BA_ "GenMsgCycleTime" BO_ 627 50;
BA_ "MsgType" BO_ 627 0;
BA_ "VFrameFormat" BO_ 627 14;
BA_ "GenMsgCycleTime" BO_ 629 50;
BA_ "MsgType" BO_ 629 0;
BA_ "VFrameFormat" BO_ 629 14;
BA_ "GenMsgCycleTime" BO_ 639 50;
BA_ "MsgType" BO_ 639 0;
BA_ "VFrameFormat" BO_ 639 14;
BA_ "GenMsgCycleTime" BO_ 647 100;
BA_ "MsgType" BO_ 647 0;
BA_ "VFrameFormat" BO_ 647 14;
BA_ "GenMsgCycleTime" BO_ 659 100;
BA_ "MsgType" BO_ 659 0;
BA_ "VFrameFormat" BO_ 659 14;
BA_ "GenMsgCycleTime" BO_ 670 100;
BA_ "MsgType" BO_ 670 0;
BA_ "VFrameFormat" BO_ 670 14;
BA_ "GenMsgCycleTime" BO_ 707 100;
BA_ "MsgType" BO_ 707 0;
BA_ "VFrameFormat" BO_ 707 14;
BA_ "GenMsgCycleTime" BO_ 717 100;
BA_ "MsgType" BO_ 717 0;
BA_ "VFrameFormat" BO_ 717 14;
BA_ "GenMsgCycleTime" BO_ 725 100;
BA_ "MsgType" BO_ 725 0;
BA_ "VFrameFormat" BO_ 725 14;
BA_ "GenMsgCycleTime" BO_ 726 100;
BA_ "MsgType" BO_ 726 0;
BA_ "VFrameFormat" BO_ 726 14;
BA_ "MsgType" BO_ 728 0;
BA_ "GenMsgSendType" BO_ 728 1;
BA_ "VFrameFormat" BO_ 728 14;
BA_ "MsgType" BO_ 730 0;
BA_ "GenMsgSendType" BO_ 730 1;
BA_ "VFrameFormat" BO_ 730 14;
BA_ "MsgType" BO_ 733 0;
BA_ "GenMsgSendType" BO_ 733 1;
BA_ "VFrameFormat" BO_ 733 14;
BA_ "MsgType" BO_ 734 0;
BA_ "GenMsgSendType" BO_ 734 1;
BA_ "VFrameFormat" BO_ 734 14;
BA_ "GenMsgCycleTime" BO_ 768 100;
BA_ "MsgType" BO_ 768 0;
BA_ "VFrameFormat" BO_ 768 14;
BA_ "GenMsgCycleTime" BO_ 795 200;
BA_ "MsgType" BO_ 795 0;
BA_ "VFrameFormat" BO_ 795 14;
BA_ "GenMsgCycleTime" BO_ 796 100;
BA_ "MsgType" BO_ 796 0;
BA_ "VFrameFormat" BO_ 796 14;
BA_ "GenMsgCycleTime" BO_ 799 100;
BA_ "MsgType" BO_ 799 0;
BA_ "VFrameFormat" BO_ 799 14;
BA_ "GenMsgCycleTime" BO_ 822 200;
BA_ "MsgType" BO_ 822 0;
BA_ "VFrameFormat" BO_ 822 14;
BA_ "MsgType" BO_ 827 0;
BA_ "GenMsgSendType" BO_ 827 1;
BA_ "VFrameFormat" BO_ 827 14;
BA_ "MsgType" BO_ 829 0;
BA_ "GenMsgSendType" BO_ 829 1;
BA_ "VFrameFormat" BO_ 829 14;
BA_ "GenMsgCycleTime" BO_ 840 500;
BA_ "MsgType" BO_ 840 0;
BA_ "VFrameFormat" BO_ 840 14;
BA_ "GenMsgCycleTime" BO_ 849 500;
BA_ "MsgType" BO_ 849 0;
BA_ "GenMsgSendType" BO_ 849 11;
BA_ "VFrameFormat" BO_ 849 14;
BA_ "GenMsgCycleTime" BO_ 860 500;
BA_ "MsgType" BO_ 860 0;
BA_ "VFrameFormat" BO_ 860 14;
BA_ "GenMsgCycleTime" BO_ 879 500;
BA_ "MsgType" BO_ 879 0;
BA_ "VFrameFormat" BO_ 879 14;
BA_ "GenMsgCycleTime" BO_ 880 1000;
BA_ "MsgType" BO_ 880 0;
BA_ "VFrameFormat" BO_ 880 14;
BA_ "GenMsgCycleTime" BO_ 907 500;
BA_ "MsgType" BO_ 907 0;
BA_ "GenMsgSendType" BO_ 907 11;
BA_ "VFrameFormat" BO_ 907 14;
BA_ "GenMsgCycleTime" BO_ 1001 1000;
BA_ "MsgType" BO_ 1001 0;
BA_ "VFrameFormat" BO_ 1001 14;
BA_ "GenMsgCycleTime" BO_ 1045 5000;
BA_ "MsgType" BO_ 1045 0;
BA_ "VFrameFormat" BO_ 1045 14;
BA_ "MsgType" BO_ 68 0;
BA_ "GenMsgSendType" BO_ 68 1;
BA_ "VFrameFormat" BO_ 68 14;
BA_ "MsgType" BO_ 74 0;
BA_ "GenMsgSendType" BO_ 74 1;
BA_ "VFrameFormat" BO_ 74 14;
BA_ "GenMsgCycleTime" BO_ 96 10;
BA_ "MsgType" BO_ 96 0;
BA_ "VFrameFormat" BO_ 96 14;
BA_ "GenMsgCycleTime" BO_ 161 10;
BA_ "MsgType" BO_ 161 0;
BA_ "VFrameFormat" BO_ 161 14;
BA_ "GenMsgCycleTime" BO_ 181 10;
BA_ "MsgType" BO_ 181 0;
BA_ "VFrameFormat" BO_ 181 14;
BA_ "GenMsgCycleTime" BO_ 188 10;
BA_ "MsgType" BO_ 188 0;
BA_ "VFrameFormat" BO_ 188 14;
BA_ "GenMsgCycleTime" BO_ 189 20;
BA_ "MsgType" BO_ 189 0;
BA_ "VFrameFormat" BO_ 189 14;
BA_ "GenMsgCycleTime" BO_ 199 50;
BA_ "MsgType" BO_ 199 0;
BA_ "VFrameFormat" BO_ 199 14;
BA_ "GenMsgCycleTime" BO_ 255 10;
BA_ "MsgType" BO_ 255 0;
BA_ "VFrameFormat" BO_ 255 14;
BA_ "MsgType" BO_ 473 0;
BA_ "GenMsgSendType" BO_ 473 1;
BA_ "VFrameFormat" BO_ 473 14;
BA_ "GenMsgCycleTime" BO_ 568 50;
BA_ "MsgType" BO_ 568 0;
BA_ "VFrameFormat" BO_ 568 14;
BA_ "GenMsgCycleTime" BO_ 569 50;
BA_ "MsgType" BO_ 569 0;
BA_ "VFrameFormat" BO_ 569 14;
BA_ "GenMsgCycleTime" BO_ 597 50;
BA_ "MsgType" BO_ 597 0;
BA_ "VFrameFormat" BO_ 597 14;
BA_ "GenMsgCycleTime" BO_ 661 50;
BA_ "MsgType" BO_ 661 0;
BA_ "VFrameFormat" BO_ 661 14;
BA_ "GenMsgCycleTime" BO_ 669 100;
BA_ "MsgType" BO_ 669 0;
BA_ "VFrameFormat" BO_ 669 14;
BA_ "GenMsgCycleTime" BO_ 671 100;
BA_ "MsgType" BO_ 671 0;
BA_ "VFrameFormat" BO_ 671 14;
BA_ "GenMsgCycleTime" BO_ 680 100;
BA_ "MsgType" BO_ 680 0;
BA_ "VFrameFormat" BO_ 680 14;
BA_ "GenMsgCycleTime" BO_ 688 100;
BA_ "MsgType" BO_ 688 0;
BA_ "VFrameFormat" BO_ 688 14;
BA_ "GenMsgCycleTime" BO_ 699 100;
BA_ "MsgType" BO_ 699 0;
BA_ "VFrameFormat" BO_ 699 14;
BA_ "GenMsgCycleTime" BO_ 714 100;
BA_ "MsgType" BO_ 714 0;
BA_ "VFrameFormat" BO_ 714 14;
BA_ "GenMsgCycleTime" BO_ 770 200;
BA_ "MsgType" BO_ 770 0;
BA_ "GenMsgSendType" BO_ 770 11;
BA_ "VFrameFormat" BO_ 770 14;
BA_ "GenMsgCycleTime" BO_ 783 100;
BA_ "MsgType" BO_ 783 0;
BA_ "VFrameFormat" BO_ 783 14;
BA_ "GenMsgCycleTime" BO_ 793 50;
BA_ "MsgType" BO_ 793 0;
BA_ "VFrameFormat" BO_ 793 14;
BA_ "GenMsgCycleTime" BO_ 833 500;
BA_ "MsgType" BO_ 833 0;
BA_ "VFrameFormat" BO_ 833 14;
BA_ "GenMsgCycleTime" BO_ 837 50;
BA_ "MsgType" BO_ 837 0;
BA_ "VFrameFormat" BO_ 837 14;
BA_ "GenMsgCycleTime" BO_ 901 100;
BA_ "MsgType" BO_ 901 0;
BA_ "VFrameFormat" BO_ 901 14;
BA_ "GenMsgCycleTime" BO_ 917 500;
BA_ "MsgType" BO_ 917 0;
BA_ "VFrameFormat" BO_ 917 14;
BA_ "GenMsgCycleTime" BO_ 1121 30000;
BA_ "MsgType" BO_ 1121 0;
BA_ "VFrameFormat" BO_ 1121 14;
BA_ "MsgType" BO_ 165 0;
BA_ "GenMsgSendType" BO_ 165 1;
BA_ "VFrameFormat" BO_ 165 14;
BA_ "MsgType" BO_ 1308 0;
BA_ "NmAsrMessage" BO_ 1308 1;
BA_ "GenMsgSendType" BO_ 1308 8;
BA_ "GenMsgCycleTime" BO_ 1493 1000;
BA_ "MsgType" BO_ 1493 0;
BA_ "GenMsgILSupport" BO_ 1493 0;
BA_ "VFrameFormat" BO_ 1493 14;
BA_ "MsgType" BO_ 1751 0;
BA_ "DiagRequest" BO_ 1751 1;
BA_ "GenMsgILSupport" BO_ 1751 0;
BA_ "GenMsgSendType" BO_ 1751 1;
BA_ "MsgType" BO_ 1888 0;
BA_ "DiagState" BO_ 1888 1;
BA_ "GenMsgILSupport" BO_ 1888 0;
BA_ "GenMsgSendType" BO_ 1888 1;
BA_ "MsgType" BO_ 1906 0;
BA_ "GenMsgILSupport" BO_ 1906 0;
BA_ "GenMsgSendType" BO_ 1906 1;
BA_ "MsgType" BO_ 1759 0;
BA_ "DiagResponse" BO_ 1759 1;
BA_ "GenMsgILSupport" BO_ 1759 0;
BA_ "GenMsgSendType" BO_ 1759 8;
BA_ "MsgType" BO_ 1970 0;
BA_ "GenMsgILSupport" BO_ 1970 0;
BA_ "GenMsgSendType" BO_ 1970 8;
BA_ "IsRcSignal" SG_ 719 RollingCounter_IFC7 1;
BA_ "GenSigStartValue" SG_ 719 TSR_Snvty 15;
BA_ "GenSigStartValue" SG_ 719 TSRSpdLimUnit 1;
BA_ "IsCrcSignal" SG_ 719 Checksum_IFC7 1;
BA_ "GenSigStartValue" SG_ 273 EngSpdVldty 2;
BA_ "GenSigStartValue" SG_ 283 VCU_MaxSpdLimit 3000;
BA_ "IsRcSignal" SG_ 283 RollingCounter_VCU26 1;
BA_ "GenSigStartValue" SG_ 283 ActTotWheelTrq 4094;
BA_ "GenSigStartValue" SG_ 283 VCU_DrvReqTqWhl 1200;
BA_ "GenSigStartValue" SG_ 283 MinPsblNegWheelTrq 4094;
BA_ "IsCrcSignal" SG_ 283 Checksum_VCU26 1;
BA_ "IsRcSignal" SG_ 283 RollingCounter_VCU21 1;
BA_ "IsCrcSignal" SG_ 283 Checksum_VCU21 1;
BA_ "IsRcSignal" SG_ 283 RollingCounter_VCU12 1;
BA_ "IsCrcSignal" SG_ 283 Checksum_VCU12 1;
BA_ "IsRcSignal" SG_ 302 RollingCounter_IBC_FD1_5 1;
BA_ "GenSigStartValue" SG_ 302 RPAavailability 1;
BA_ "GenSigStartValue" SG_ 302 APAavailability 1;
BA_ "GenSigStartValue" SG_ 302 AVPavailability 1;
BA_ "IsCrcSignal" SG_ 302 Checksum_IBC_FD1_5 1;
BA_ "IsRcSignal" SG_ 302 RollingCounter_IBC_FD1_2 1;
BA_ "IsCrcSignal" SG_ 302 Checksum_IBC_FD1_2 1;
BA_ "IsRcSignal" SG_ 302 RollingCounter_IBC_FD1_1 1;
BA_ "IsCrcSignal" SG_ 302 Checksum_IBC_FD1_1 1;
BA_ "GenSigStartValue" SG_ 311 RWSAngMinLimn 1023;
BA_ "GenSigStartValue" SG_ 311 RWSAngMaxLimn 1023;
BA_ "IsRcSignal" SG_ 311 RollingCounter_ABS3 1;
BA_ "GenSigStartValue" SG_ 311 ABSFailSts 1;
BA_ "IsCrcSignal" SG_ 311 Checksum_ABS3 1;
BA_ "GenSigStartValue" SG_ 311 DrvTrqRedFastReq_FA 65535;
BA_ "IsRcSignal" SG_ 311 RollingCounter_ESP7 1;
BA_ "IsCrcSignal" SG_ 311 Checksum_ESP7 1;
BA_ "IsRcSignal" SG_ 311 RollingCounter_ESP1 1;
BA_ "GenSigStartValue" SG_ 311 ESP_MasterCylBrkPressVld 1;
BA_ "IsCrcSignal" SG_ 311 Checksum_ESP1 1;
BA_ "IsRcSignal" SG_ 311 RollingCounter_ESP2 1;
BA_ "GenSigStartValue" SG_ 311 DrivingModReq_ESP 1;
BA_ "IsCrcSignal" SG_ 311 Checksum_ESP2 1;
BA_ "IsRcSignal" SG_ 315 RollingCounter_ABS2 1;
BA_ "GenSigStartValue" SG_ 315 WssRREdgesSumVld 1;
BA_ "GenSigStartValue" SG_ 315 WssRLEdgesSumVld 1;
BA_ "IsCrcSignal" SG_ 315 Checksum_ABS2 1;
BA_ "GenSigStartValue" SG_ 315 DrvTrqRedReq_RA 65535;
BA_ "IsRcSignal" SG_ 315 RollingCounter_EPB1 1;
BA_ "IsCrcSignal" SG_ 315 Checksum_EPB1 1;
BA_ "IsRcSignal" SG_ 315 RollingCounter_ABS1 1;
BA_ "GenSigStartValue" SG_ 315 WssFREdgesSumVld 1;
BA_ "GenSigStartValue" SG_ 315 WssFLEdgesSumVld 1;
BA_ "IsCrcSignal" SG_ 315 Checksum_ABS1 1;
BA_ "IsRcSignal" SG_ 320 RollingCounter_RWA_FD2_2 1;
BA_ "IsCrcSignal" SG_ 320 Checksum_RWA_FD2_2 1;
BA_ "IsRcSignal" SG_ 327 RollingCounter_EPS3 1;
BA_ "IsCrcSignal" SG_ 327 Checksum_EPS3 1;
BA_ "IsRcSignal" SG_ 327 RollingCounter_EPS2 1;
BA_ "GenSigStartValue" SG_ 327 EPS_LKATorqOvrlDlvd 1500;
BA_ "GenSigStartValue" SG_ 327 EPS_DrvInpTrqVal_HighReslolution 2047;
BA_ "IsCrcSignal" SG_ 327 Checksum_EPS2 1;
BA_ "IsRcSignal" SG_ 327 RollingCounter_EPS1 1;
BA_ "GenSigStartValue" SG_ 327 EPS_DSTCtrlSts 1;
BA_ "GenSigStartValue" SG_ 327 EPS_TrqSnsrSts 1;
BA_ "IsCrcSignal" SG_ 327 Checksum_EPS1 1;
BA_ "IsRcSignal" SG_ 332 RollingCounter_RWA_FD1_2 1;
BA_ "IsCrcSignal" SG_ 332 Checksum_RWA_FD1_2 1;
BA_ "IsRcSignal" SG_ 346 RollingCounter_LBM2 1;
BA_ "IsCrcSignal" SG_ 346 Checksum_LBM2 1;
BA_ "IsRcSignal" SG_ 356 RollingCounter_EPS_FD2_3 1;
BA_ "IsCrcSignal" SG_ 356 Checksum_EPS_FD2_3 1;
BA_ "IsRcSignal" SG_ 356 RollingCounter_EPS_FD2_2 1;
BA_ "GenSigStartValue" SG_ 356 EPS_DrvInpTrqVal_HiRes_Backup 2047;
BA_ "GenSigStartValue" SG_ 356 EPS_LKATorqOvrlDlvd_Backup 1500;
BA_ "IsCrcSignal" SG_ 356 Checksum_EPS_FD2_2 1;
BA_ "IsRcSignal" SG_ 356 RollingCounter_EPS_FD2_1 1;
BA_ "GenSigStartValue" SG_ 356 EPS_TrqSnsrSts_Backup 1;
BA_ "IsCrcSignal" SG_ 356 Checksum_EPS_FD2_1 1;
BA_ "GenSigStartValue" SG_ 367 RSDS_ObjRelAccelY_Ri 512;
BA_ "GenSigStartValue" SG_ 367 RSDS_ObjRelAccelX_Ri 512;
BA_ "GenSigStartValue" SG_ 367 RSDS_ObjRelAccelX_Le 512;
BA_ "IsRcSignal" SG_ 367 RollingCounter_RSDS_R_5 1;
BA_ "GenSigStartValue" SG_ 367 ObjTTCRi 127;
BA_ "GenSigStartValue" SG_ 367 ObjLatSpdCurvRi 64;
BA_ "GenSigStartValue" SG_ 367 ObjLatPosnCurvRi 128;
BA_ "GenSigStartValue" SG_ 367 RiTarSts 2;
BA_ "IsCrcSignal" SG_ 367 Checksum_RSDS_R_5 1;
BA_ "IsRcSignal" SG_ 367 RollingCounter_RSDS_R_4 1;
BA_ "IsCrcSignal" SG_ 367 Checksum_RSDS_R_4 1;
BA_ "IsRcSignal" SG_ 367 RollingCounter_RSDS_R_3 1;
BA_ "GenSigStartValue" SG_ 367 ObjTTCLe 127;
BA_ "GenSigStartValue" SG_ 367 ObjLatSpdCurvLe 64;
BA_ "GenSigStartValue" SG_ 367 ObjLatPosnCurvLe 128;
BA_ "GenSigStartValue" SG_ 367 LeTarSts 2;
BA_ "IsCrcSignal" SG_ 367 Checksum_RSDS_R_3 1;
BA_ "GenSigStartValue" SG_ 367 RSDS_ObjRelAccelY_Le 512;
BA_ "IsRcSignal" SG_ 388 RollingCounter_VCU_FD28_2 1;
BA_ "IsCrcSignal" SG_ 388 Checksum_VCU_FD28_2 1;
BA_ "IsRcSignal" SG_ 388 RollingCounter_VCU_FD28_1 1;
BA_ "IsCrcSignal" SG_ 388 Checksum_VCU_FD28_1 1;
BA_ "GenSigSendType" SG_ 474 TSRLimSpdChngSoundSet 9;
BA_ "GenSigSendType" SG_ 474 ACC_OverTakingAsscSet 9;
BA_ "GenSigSendType" SG_ 474 OneclickClsIntellgntDrvgReq 9;
BA_ "GenSigSendType" SG_ 474 OutdPrkgReq 9;
BA_ "GenSigSendType" SG_ 474 CamFolwSwtReq 9;
BA_ "GenSigSendType" SG_ 474 PrkModReq 9;
BA_ "GenSigSendType" SG_ 474 TJA_ASCruise 9;
BA_ "GenSigSendType" SG_ 474 RCTA_DispSwtReq 9;
BA_ "GenSigSendType" SG_ 474 AutoPrkOutSwtReq 9;
BA_ "GenSigSendType" SG_ 474 PrkgSlotId 9;
BA_ "GenSigSendType" SG_ 474 HAVP_UseMod 9;
BA_ "GenSigSendType" SG_ 474 HUT_HAVP_APA_Permit 9;
BA_ "GenSigSendType" SG_ 474 UserDefinedParkCmd 9;
BA_ "GenSigSendType" SG_ 474 SlotNum_VR 9;
BA_ "GenSigSendType" SG_ 474 UserDefPrkMenuSelCmd 9;
BA_ "GenSigSendType" SG_ 474 HUT_HAVP_Set_Path_Ending 9;
BA_ "GenSigSendType" SG_ 474 HUT_HAVP_Comfirm_Btn 9;
BA_ "GenSigSendType" SG_ 474 HUT_HAVP_SelfParLot_Ending 9;
BA_ "GenSigSendType" SG_ 474 HUT_HAVP_Set_Starting 9;
BA_ "GenSigSendType" SG_ 474 BackReq_RPA 9;
BA_ "GenSigSendType" SG_ 474 SteerWheelsilentReq 9;
BA_ "GenSigSendType" SG_ 489 BackReq_AVM 9;
BA_ "GenSigSendType" SG_ 490 RmtPrkRadShieldSet 9;
BA_ "GenSigSendType" SG_ 493 TraOvlSwtCmd 9;
BA_ "GenSigSendType" SG_ 493 StartPrkgPath2Cmd 9;
BA_ "GenSigSendType" SG_ 493 DeletePath2Cmd 9;
BA_ "GenSigSendType" SG_ 493 StartPrkgPath1Cmd 9;
BA_ "GenSigSendType" SG_ 493 DeletePath1Cmd 9;
BA_ "GenSigSendType" SG_ 493 SelPrkgFctnCmd 9;
BA_ "GenSigSendType" SG_ 493 P2P_PrkgDirectSwtCmd 9;
BA_ "GenSigSendType" SG_ 493 PathLrngFinshCmd 9;
BA_ "GenSigSendType" SG_ 493 PathLrngStartCmd 9;
BA_ "GenSigSendType" SG_ 493 ParkMdlCmd 9;
BA_ "GenSigSendType" SG_ 493 BackReq_APS 9;
BA_ "GenSigSendType" SG_ 493 SelPrkOutDirReq 9;
BA_ "GenSigSendType" SG_ 493 PrkInDirChoice 9;
BA_ "GenSigSendType" SG_ 494 APSSwtReq_VR 9;
BA_ "GenSigSendType" SG_ 494 APSPrkgTypSeln 9;
BA_ "GenSigSendType" SG_ 494 SDWSwtSet 9;
BA_ "IsRcSignal" SG_ 545 RollingCounter_DCT5 1;
BA_ "GenSigStartValue" SG_ 545 ShiftLeverPosn_SBWM 7;
BA_ "GenSigStartValue" SG_ 545 TGS_LEVER 14;
BA_ "IsCrcSignal" SG_ 545 Checksum_DCT5 1;
BA_ "IsRcSignal" SG_ 555 RollingCounter_HOD_1 1;
BA_ "GenSigStartValue" SG_ 555 HOD_HandOffSts 15;
BA_ "GenSigStartValue" SG_ 555 HOD_ErrInfo 15;
BA_ "IsCrcSignal" SG_ 555 Checksum_HOD_1 1;
BA_ "IsRcSignal" SG_ 581 RollingCounter_ABM2 1;
BA_ "GenSigStartValue" SG_ 581 VehYawRate 8721;
BA_ "GenSigStartValue" SG_ 581 VehLatAccel 22033;
BA_ "GenSigStartValue" SG_ 581 VehLgtAccel 22033;
BA_ "IsCrcSignal" SG_ 581 Checksum_ABM2 1;
BA_ "GenSigStartValue" SG_ 589 DrvBehvSts 7;
BA_ "GenSigStartValue" SG_ 589 DMSSts 7;
BA_ "GenSigStartValue" SG_ 589 DrowsnsLvl_ACC 7;
BA_ "GenSigStartValue" SG_ 589 DistrctnLvl_ACC 7;
BA_ "IsRcSignal" SG_ 604 RollingCounter_BLE1 1;
BA_ "IsCrcSignal" SG_ 604 Checksum_BLE1 1;
BA_ "IsRcSignal" SG_ 623 RollingCounter_HUT32 1;
BA_ "GenSigStartValue" SG_ 623 Ylevel 4094;
BA_ "GenSigStartValue" SG_ 623 Xlevel 4094;
BA_ "IsCrcSignal" SG_ 623 Checksum_HUT32 1;
BA_ "IsRcSignal" SG_ 629 RollingCounter_Trailer2 1;
BA_ "GenSigStartValue" SG_ 629 TrailerStatusVld 1;
BA_ "IsCrcSignal" SG_ 629 Checksum_Trailer2 1;
BA_ "IsRcSignal" SG_ 647 RollingCounter_HC1 1;
BA_ "IsCrcSignal" SG_ 647 Checksum_HC1 1;
BA_ "GenSigStartValue" SG_ 659 IP_LagueSet 15;
BA_ "GenSigStartValue" SG_ 707 ADAS_Posn_Spd 511;
BA_ "GenSigStartValue" SG_ 707 ADAS_Posn_Offset 8191;
BA_ "GenSigStartValue" SG_ 707 HWA_SwtReq 1;
BA_ "GenSigStartValue" SG_ 707 NavCtryType 156;
BA_ "GenSigStartValue" SG_ 707 NavSpdLimUnit_HUT 1;
BA_ "GenSigStartValue" SG_ 707 TSR_SnvtySet 15;
BA_ "GenSigStartValue" SG_ 707 AEB_PedSwtReq 1;
BA_ "GenSigStartValue" SG_ 707 AEB_VehSwtReq 1;
BA_ "IsRcSignal" SG_ 726 RollingCounter_VCU13 1;
BA_ "IsCrcSignal" SG_ 726 Checksum_VCU13 1;
BA_ "IsRcSignal" SG_ 726 RollingCounter_VCU3 1;
BA_ "IsCrcSignal" SG_ 726 Checksum_VCU3 1;
BA_ "GenSigSendType" SG_ 728 ADAS_Stub_NumOfLaneDrvDir 9;
BA_ "GenSigSendType" SG_ 728 ADAS_Stub_NumOfLaneOppDir 9;
BA_ "GenSigSendType" SG_ 728 ADAS_Stub_RtOfWay 9;
BA_ "GenSigSendType" SG_ 728 ADAS_Stub_LastStub 9;
BA_ "GenSigSendType" SG_ 728 ADAS_Stub_TurnAngl 9;
BA_ "GenSigSendType" SG_ 728 ADAS_Stub_FormOfWay 9;
BA_ "GenSigSendType" SG_ 728 ADAS_Stub_CmplxInsct 9;
BA_ "GenSigSendType" SG_ 728 ADAS_Stub_PartOfCalcRoute 9;
BA_ "GenSigSendType" SG_ 728 ADAS_Stub_FuncRoadClass 9;
BA_ "GenSigSendType" SG_ 728 ADAS_Stub_RelProbb 9;
BA_ "GenSigSendType" SG_ 728 ADAS_Stub_Update 9;
BA_ "GenSigSendType" SG_ 728 ADAS_Stub_Retr 9;
BA_ "GenSigSendType" SG_ 728 ADAS_Stub_StubPathIdx 9;
BA_ "GenSigSendType" SG_ 728 ADAS_Stub_PathIdx 9;
BA_ "GenSigSendType" SG_ 728 ADAS_Stub_CycCnt 9;
BA_ "GenSigSendType" SG_ 728 ADAS_Stub_Offset 9;
BA_ "GenSigSendType" SG_ 728 ADAS_Stub_MsgTyp 9;
BA_ "GenSigSendType" SG_ 730 ADAS_Seg_NumOfLaneDrvDir 9;
BA_ "GenSigSendType" SG_ 730 ADAS_Seg_NumOfLaneOppDir 9;
BA_ "GenSigSendType" SG_ 730 ADAS_Seg_DivideRoad 9;
BA_ "GenSigSendType" SG_ 730 ADAS_Seg_EffSpdLmtTyp 9;
BA_ "GenSigSendType" SG_ 730 ADAS_Seg_EffSpdLmt 9;
BA_ "GenSigSendType" SG_ 730 ADAS_Seg_FormOfWay 9;
BA_ "GenSigSendType" SG_ 730 ADAS_Seg_CmplxInsct 9;
BA_ "GenSigSendType" SG_ 730 ADAS_Seg_PartOfCalcRoute 9;
BA_ "GenSigSendType" SG_ 730 ADAS_Seg_FuncRoadClass 9;
BA_ "GenSigSendType" SG_ 730 ADAS_Seg_RelProbb 9;
BA_ "GenSigSendType" SG_ 730 ADAS_Seg_Update 9;
BA_ "GenSigSendType" SG_ 730 ADAS_Seg_Retr 9;
BA_ "GenSigSendType" SG_ 730 ADAS_Seg_BuildUpArea 9;
BA_ "GenSigSendType" SG_ 730 ADAS_Seg_Brdg 9;
BA_ "GenSigSendType" SG_ 730 ADAS_Seg_Tunnel 9;
BA_ "GenSigSendType" SG_ 730 ADAS_Seg_PathIdx 9;
BA_ "GenSigSendType" SG_ 730 ADAS_Seg_CycCnt 9;
BA_ "GenSigSendType" SG_ 730 ADAS_Seg_Offset 9;
BA_ "GenSigSendType" SG_ 730 ADAS_Seg_MsgTyp 9;
BA_ "GenSigSendType" SG_ 733 ADAS_ProfShort_Value1 9;
BA_ "GenSigSendType" SG_ 733 ADAS_ProfShort_Value0 9;
BA_ "GenSigSendType" SG_ 733 ADAS_ProfShort_Dist1 9;
BA_ "GenSigSendType" SG_ 733 ADAS_ProfShort_AccurClass 9;
BA_ "GenSigStartValue" SG_ 733 ADAS_ProfShort_AccurClass 3;
BA_ "GenSigSendType" SG_ 733 ADAS_ProfShort_Update 9;
BA_ "GenSigSendType" SG_ 733 ADAS_ProfShort_Retr 9;
BA_ "GenSigSendType" SG_ 733 ADAS_ProfShort_CtrlPoint 9;
BA_ "GenSigSendType" SG_ 733 ADAS_ProfShort_ProfTyp 9;
BA_ "GenSigSendType" SG_ 733 ADAS_ProfShort_PathIdx 9;
BA_ "GenSigSendType" SG_ 733 ADAS_ProfShort_CycCnt 9;
BA_ "GenSigSendType" SG_ 733 ADAS_ProfShort_Offset 9;
BA_ "GenSigSendType" SG_ 733 ADAS_ProfShort_MsgTyp 9;
BA_ "GenSigSendType" SG_ 734 ADAS_ProfLong_Value 9;
BA_ "GenSigSendType" SG_ 734 ADAS_ProfLong_Update 9;
BA_ "GenSigSendType" SG_ 734 ADAS_ProfLong_Retr 9;
BA_ "GenSigSendType" SG_ 734 ADAS_ProfLong_CtrlPoint 9;
BA_ "GenSigSendType" SG_ 734 ADAS_ProfLong_ProfTyp 9;
BA_ "GenSigSendType" SG_ 734 ADAS_ProfLong_PathIdx 9;
BA_ "GenSigSendType" SG_ 734 ADAS_ProfLong_CycCnt 9;
BA_ "GenSigSendType" SG_ 734 ADAS_ProfLong_Offset 9;
BA_ "GenSigSendType" SG_ 734 ADAS_ProfLong_MsgTyp 9;
BA_ "GenSigSendType" SG_ 827 LowPowerEgyMngmntModReq 9;
BA_ "GenSigSendType" SG_ 829 T_BOX_AVPActvReq 9;
BA_ "IsRcSignal" SG_ 849 RollingCounter_ABM1 1;
BA_ "GenSigStartValue" SG_ 849 SecRowRSBR_Visual 1;
BA_ "GenSigStartValue" SG_ 849 DrvSBR_Visual 1;
BA_ "GenSigStartValue" SG_ 849 PassSBR_Visual 1;
BA_ "GenSigStartValue" SG_ 849 SecRowLSBR_Visual 1;
BA_ "GenSigStartValue" SG_ 849 SecRowMidSBR_Visual 1;
BA_ "GenSigStartValue" SG_ 849 PassSBLockSts 1;
BA_ "GenSigStartValue" SG_ 849 SecRowRSBLockSts 1;
BA_ "GenSigStartValue" SG_ 849 DrvSBR 1;
BA_ "GenSigStartValue" SG_ 849 SecRowMidSBLockSts 1;
BA_ "GenSigStartValue" SG_ 849 AirbFailLmpCmd 1;
BA_ "GenSigStartValue" SG_ 849 SecRowLSBLockSts 1;
BA_ "GenSigStartValue" SG_ 849 PABSwtSts 1;
BA_ "IsCrcSignal" SG_ 849 Checksum_ABM1 1;
BA_ "GenSigStartValue" SG_ 880 Time_Year_Right 15;
BA_ "GenSigStartValue" SG_ 880 Time_Year_Left 15;
BA_ "GenSigStartValue" SG_ 880 Time_Second 63;
BA_ "GenSigStartValue" SG_ 880 Time_Minutes 63;
BA_ "GenSigStartValue" SG_ 880 Time_Hour 31;
BA_ "IsRcSignal" SG_ 907 RollingCounter_PTCC1_1 1;
BA_ "IsCrcSignal" SG_ 907 Checksum_PTCC1_1 1;
BA_ "GenSigStartValue" SG_ 1045 ADAS_Meta_DrvSide 1;
BA_ "GenSigSendType" SG_ 68 CarWashModeReq 9;
BA_ "GenSigStartValue" SG_ 68 CarWashModeReq 2;
BA_ "GenSigSendType" SG_ 74 AutoAVMSwSet_Cmd 9;
BA_ "GenSigSendType" SG_ 74 SwToFieldCalRstCmd 9;
BA_ "GenSigSendType" SG_ 74 View_SoftswitchCmd 9;
BA_ "GenSigSendType" SG_ 74 FPAS_AutoModSwt 9;
BA_ "GenSigSendType" SG_ 74 MEBSwtSet 9;
BA_ "GenSigSendType" SG_ 74 CarMdlDispCmd 9;
BA_ "GenSigSendType" SG_ 74 CarMdlTrsprcySwtCmd 9;
BA_ "GenSigSendType" SG_ 74 AutoViewChgCmd 9;
BA_ "GenSigSendType" SG_ 74 LaneCalActvtCmd 9;
BA_ "GenSigSendType" SG_ 74 Sgl_View_Sel 9;
BA_ "GenSigSendType" SG_ 74 AutoAVMmodSet 9;
BA_ "GenSigSendType" SG_ 74 WheelVieSwt 9;
BA_ "IsRcSignal" SG_ 96 RollingCounter_HCU_HP10 1;
BA_ "IsCrcSignal" SG_ 96 Checksum_HCU_HP10 1;
BA_ "IsRcSignal" SG_ 96 RollingCounter_HCU_PT1 1;
BA_ "GenSigStartValue" SG_ 96 ActWheelTrqDmd 1200;
BA_ "IsCrcSignal" SG_ 96 Checksum_HCU_PT1 1;
BA_ "IsRcSignal" SG_ 161 RollingCounter_CSA2 1;
BA_ "IsCrcSignal" SG_ 161 Checksum_CSA2 1;
BA_ "IsRcSignal" SG_ 181 RollingCounter_VCU15 1;
BA_ "IsCrcSignal" SG_ 181 Checksum_VCU15 1;
BA_ "IsRcSignal" SG_ 181 RollingCounter_VCU6 1;
BA_ "GenSigStartValue" SG_ 181 VCU_AccelPedalPosnValid 1;
BA_ "IsCrcSignal" SG_ 181 Checksum_VCU6 1;
BA_ "GenSigStartValue" SG_ 188 RWS_AngAct 4095;
BA_ "IsRcSignal" SG_ 189 RollingCounter_ESP12 1;
BA_ "GenSigStartValue" SG_ 189 TgtRcprtnTrqReq 8192;
BA_ "IsCrcSignal" SG_ 189 Checksum_ESP12 1;
BA_ "GenSigStartValue" SG_ 199 DRV_RQ_SHFT 8;
BA_ "IsRcSignal" SG_ 255 RollingCounter_Body_Hei 1;
BA_ "IsCrcSignal" SG_ 255 Checksum_Body_Hei 1;
BA_ "GenSigSendType" SG_ 473 OTApowertrainmode 9;
BA_ "GenSigStartValue" SG_ 568 SrPosn_VR_APP 127;
BA_ "GenSigStartValue" SG_ 669 InCarTemp 254;
BA_ "IsRcSignal" SG_ 671 RollingCounter_BCM8 1;
BA_ "IsCrcSignal" SG_ 671 Checksum_BCM8 1;
BA_ "IsRcSignal" SG_ 793 RollingCounter_BCM1 1;
BA_ "IsCrcSignal" SG_ 793 Checksum_BCM1 1;
BA_ "GenSigStartValue" SG_ 901 ACAmbTemp 254;
BA_ "GenSigStartValue" SG_ 901 ACFrntBlwrSpd 15;
BA_ "GenSigSendType" SG_ 165 DoorHndlBtnActn 9;
BA_ "GenSigSendType" SG_ 165 PhyKeyPressActn 9;
BA_ "GenSigSendType" SG_ 165 PhyKeyPosnSts 9;
BA_ "NormValue" SG_ 1308 PNCInfo_Global "No";
BA_ "GenSigSendType" SG_ 1308 PNCInfo_Global 9;
BA_ "NormValue" SG_ 1308 PNCInfo_ADAS "No";
BA_ "GenSigSendType" SG_ 1308 PNCInfo_ADAS 9;
BA_ "NormValue" SG_ 1308 StayAwakeKL15 "No";
BA_ "GenSigSendType" SG_ 1308 StayAwakeKL15 9;
BA_ "NormValue" SG_ 1308 Wake_upReasonKL15 "No";
BA_ "GenSigSendType" SG_ 1308 Wake_upReasonKL15 9;
BA_ "NormValue" SG_ 1308 Wake_upReasonNM "No";
BA_ "GenSigSendType" SG_ 1308 Wake_upReasonNM 9;
BA_ "NormValue" SG_ 1308 RepeatMessageState "No";
BA_ "GenSigSendType" SG_ 1308 RepeatMessageState 9;
BA_ "NormValue" SG_ 1493 FR_DTC_Code "No";
BA_ "NormValue" SG_ 1751 IDC_Phy_Req "Yes";
BA_ "GenSigSendType" SG_ 1751 IDC_Phy_Req 9;
BA_ "NormValue" SG_ 1888 DiagFuncReq "Yes";
BA_ "GenSigSendType" SG_ 1888 DiagFuncReq 9;
BA_ "NormValue" SG_ 1906 FR_Phy_Req "Yes";
BA_ "GenSigSendType" SG_ 1906 FR_Phy_Req 9;
BA_ "NormValue" SG_ 1759 IDC_Phy_Resp "No";
BA_ "GenSigSendType" SG_ 1759 IDC_Phy_Resp 9;
BA_ "NormValue" SG_ 1970 FR_Phy_Resp "No";
BA_ "GenSigSendType" SG_ 1970 FR_Phy_Resp 9;
VAL_ 719 AttentionDivsAlarmTimGrad 0 "Initial_Value" 1 "Warning_Level_1" 2 "Warning_Level_2" 3 "Warning_Level_3" ;
VAL_ 719 TraLightCtrlSts 0 "No_Display" 1 "OFF" 2 "Passive" 3 "Standby" 4 "Active" 5 "Fault" ;
VAL_ 719 RR_SideCamaErrSts 0 "No_Error" 1 "Error" 2 "Blindness" ;
VAL_ 719 LR_SideCamaErrSts 0 "No_Error" 1 "Error" 2 "Blindness" ;
VAL_ 719 TraLightSwtResp 0 "OFF" 1 "ON" ;
VAL_ 719 TraLightRmdInfoDisp 0 "No_Display" 1 "TLC_Activated" 2 "TLC_Deactivated" 3 "Stopping_by_yellow_light" 4 "Stopping_by_red_light" 5 "Launching_by_green_light" 6 "Stepping_into_waiting_area" 7 "Going_straight" 8 "Going_straight_pay_attention_pls" 9 "Left_turning" 10 "Left_turning_pay_attention_pls" 11 "Right_turning" 12 "Right_turning_pay_attention_pls" 13 "Turning_around,_pay_attention_pls" 14 "Warning" 15 "Take_over_pls" ;
VAL_ 719 TraLightWarnInfoDisp 0 "No_Traffic_light" 1 "Left_Turn" 2 "Straight" 3 "Right_Turn" 4 "Warning" 5 "Turn_round_Warning" 6 "Run_Ared_Light" 7 "Stop_About_To_Cross_The_Line" 8 "Slow_Down_The_Yellow_Light" 9 "Camera_is_covered" 10 "Traffic_Light_Observation_Limited" 11 "Roundabout" ;
VAL_ 719 TSR_TFL_EgoVeh 0 "No_warning" 1 "One" 2 "Two" 3 "Three" 4 "Four" 5 "Five" 6 "Six" 7 "Seven" 8 "Eight" ;
VAL_ 719 TSR_TFL7_LightColor 0 "No_warning" 1 "Red_light" 2 "Green_light" 3 "Yellow_light" 4 "Red_light_flash" 5 "Green_light_flash" 6 "Yellow_light_flash" ;
VAL_ 719 TSR_TFL7_LightType 0 "No_warning" 1 "S" 2 "LT" 3 "RT" 4 "TA" 5 "SLT" 6 "SRT" 7 "SLRT" 8 "STA" 9 "Red_light_allow_to_turn_left" 10 "Red_light_allow_to_turn_right" ;
VAL_ 719 TSR_TFL6_LightColor 0 "No_warning" 1 "Red_light" 2 "Green_light" 3 "Yellow_light" 4 "Red_light_flash" 5 "Green_light_flash" 6 "Yellow_light_flash" ;
VAL_ 719 TSR_TFL6_LightType 0 "No_warning" 1 "S" 2 "LT" 3 "RT" 4 "TA" 5 "SLT" 6 "SRT" 7 "SLRT" 8 "STA" 9 "Red_light_allow_to_turn_left" 10 "Red_light_allow_to_turn_right" ;
VAL_ 719 TSR_TFL5_LightColor 0 "No_warning" 1 "Red_light" 2 "Green_light" 3 "Yellow_light" 4 "Red_light_flash" 5 "Green_light_flash" 6 "Yellow_light_flash" ;
VAL_ 719 TSR_TFL5_LightType 0 "No_warning" 1 "S" 2 "LT" 3 "RT" 4 "TA" 5 "SLT" 6 "SRT" 7 "SLRT" 8 "STA" 9 "Red_light_allow_to_turn_left" 10 "Red_light_allow_to_turn_right" ;
VAL_ 719 TSR_TFL4_LightColor 0 "No_warning" 1 "Red_light" 2 "Green_light" 3 "Yellow_light" 4 "Red_light_flash" 5 "Green_light_flash" 6 "Yellow_light_flash" ;
VAL_ 719 TSR_TFL4_LightType 0 "No_warning" 1 "S" 2 "LT" 3 "RT" 4 "TA" 5 "SLT" 6 "SRT" 7 "SLRT" 8 "STA" 9 "Red_light_allow_to_turn_left" 10 "Red_light_allow_to_turn_right" ;
VAL_ 719 TSR_TFL3_LightColor 0 "No_warning" 1 "Red_light" 2 "Green_light" 3 "Yellow_light" 4 "Red_light_flash" 5 "Green_light_flash" 6 "Yellow_light_flash" ;
VAL_ 719 TSR_TFL3_LightType 0 "No_warning" 1 "S" 2 "LT" 3 "RT" 4 "TA" 5 "SLT" 6 "SRT" 7 "SLRT" 8 "STA" 9 "Red_light_allow_to_turn_left" 10 "Red_light_allow_to_turn_right" ;
VAL_ 719 TSR_TFL2_LightColor 0 "No_warning" 1 "Red_light" 2 "Green_light" 3 "Yellow_light" 4 "Red_light_flash" 5 "Green_light_flash" 6 "Yellow_light_flash" ;
VAL_ 719 TSR_TFL2_LightType 0 "No_warning" 1 "S" 2 "LT" 3 "RT" 4 "TA" 5 "SLT" 6 "SRT" 7 "SLRT" 8 "STA" 9 "Red_light_allow_to_turn_left" 10 "Red_light_allow_to_turn_right" ;
VAL_ 719 TSR_TFL1_LightColor 0 "No_warning" 1 "Red_light" 2 "Green_light" 3 "Yellow_light" 4 "Red_light_flash" 5 "Green_light_flash" 6 "Yellow_light_flash" ;
VAL_ 719 TSR_TFL7_LightTime 0 "Valid_value" ;
VAL_ 719 TSR_TFL6_LightTime 0 "Valid_value" ;
VAL_ 719 NavDecActive 0 "Inactive" 1 "NavDec_Active" 2 "NavDec_Take_Over_Warning" 3 "SPL_60_NavDec_Take_Over_Warning" 4 "SPL_70_NavDec_Take_Over_Warning" 5 "SPL_80_NavDec_Take_Over_Warning" 6 "SPL_90_NavDec_Take_Over_Warning" 7 "SPL_100_NavDec_Take_Over_Warning" 8 "SPL_110_NavDec_Take_Over_Warning" 9 "SPL_120_NavDec_Take_Over_Warning" 10 "Set_speed_over_NavDec" 11 "Reserved" ;
VAL_ 719 LCMode_Swt_Resp 0 "Normal" 1 "Sport" 2 "Comfort" ;
VAL_ 719 RainMode_Swt_Resp 0 "OFF" 1 "ON" ;
VAL_ 719 TSR_Traffic_Light_Ri 0 "No_Display" 1 "Greenlight" 2 "Redlight" 3 "Yellowlight" ;
VAL_ 719 TSR_Traffic_Light_Le 0 "No_Display" 1 "Greenlight" 2 "Redlight" 3 "Yellowlight" ;
VAL_ 719 TSR_Traffic_Light_Through 0 "No_Display" 1 "Greenlight" 2 "Redlight" 3 "Yellowlight" ;
VAL_ 719 TSR_Traffic_Light 0 "No_Display" 1 "Greenlight" 2 "Redlight" 3 "Yellowlight" ;
VAL_ 719 LaneChngCfmSwt_Resp 0 "OFF" 1 "ON" ;
VAL_ 719 ALC_SwtReq_Resp 0 "OFF" 1 "ON" ;
VAL_ 719 AutoSpdSetSwt_Resp 0 "OFF" 1 "ON" ;
VAL_ 719 VoiceBrdcSwt_Resp 0 "OFF" 1 "ON" ;
VAL_ 719 UsrManSts_Resp 0 "OFF" 1 "Page_1" 2 "Page_2" 3 "Page_3" 4 "Page_4" 5 "Page_5" 6 "Page_6" 7 "Page_7" 8 "Page_8" 9 "Page_9" ;
VAL_ 719 HWA_InhibitWarn 0 "Default" 1 "Environment_inhibit" 2 "Attention" 3 "Handson" 4 "Seatbelt" 5 "Close_door" 6 "DMS_Off" 7 "Forward_gear" ;
VAL_ 719 Grid_Mark_Detn 0 "Not_dectected" 1 "Dectected" 3 "Invalid" ;
VAL_ 719 Zebra_Mark_Detn 0 "Not_dectected" 1 "Dectected" 3 "Invalid" ;
VAL_ 719 Stop_Mark_Detn 0 "Not_dectected" 1 "Dectected" 3 "Invalid" ;
VAL_ 719 IFC_Line02_Source 0 "Detected_value" 1 "Fitted_value" ;
VAL_ 719 TSR_Traffic_Light_Posn 0 "No_Display" 1 "Front" 2 "Left" 3 "Right" ;
VAL_ 719 NOH_WarnInfoDisp 0 "Default" 1 "Auto_store_to_debug_NOH" 2 "Restart_to_activate_NOH" 3 "Off_ramp_fail" 4 "To_mainroad_fail" 5 "Turning_fail" 6 "Toll_gate_fail" 7 "Roundabout_fail" 8 "Reroute" 9 "Lane_change_manually" 10 "NOH_resumed" 11 "Veh_merge_warn" 12 "Ramp_off_warn" 13 "GPS_fail" 14 "Lane_mark_blurred" 15 "To_drive_out_of_main_road" ;
VAL_ 719 MRC_TakOver_Req 0 "No_Display" 1 "Slow_stop" 2 "Roadside_stop" 3 "Emergent_stop" ;
VAL_ 719 IFC_Line01_Source 0 "Detected_value" 1 "Fitted_value" ;
VAL_ 719 MRC_InterSysInfoDisp 0 "Default" 1 "L_CR_fail" 2 "R_CR_fail" 3 "L_RSDS_fail" 4 "R_RSDS_fail" 5 "Radar_or_Cam_fail" ;
VAL_ 719 HWA_TakOver_Trig 0 "Default" 1 "Off_ramp_fail" 2 "To_mainroad_fail" 3 "Turning_fail" 4 "Toll_gate_fail" 5 "Roundabout_fail" 6 "To_slow_stop" ;
VAL_ 719 HWA_TakOver_Req 0 "Default" 1 "Steer_wheel_req" 2 "Takeover_req" ;
VAL_ 719 HWA_WarnInfoDisp 0 "No_Display" 1 "Construction_site_ahead" 2 "large_vehicles_warn" 3 "Night_warning" 4 "Adverse_weather_warning" 5 "Restart_to_activate_HIPilot" 6 "Camera_blocked" 7 "Auto_store_to_debug_HIPilot" 8 "Confirm_left_lane_change" 9 "Confirm_right_lane_change" 10 "Try_ALC_later" 11 "lane_change_is_cancelled_because_of_risk" 12 "lane_change_aborted" 13 "Please_Keep_Attention_distraction" 14 "Fasten_copilot_seatbelt" 15 "Curve_driving_please_hold_the_steering_wheel" ;
VAL_ 719 HWA_ALC_Trig 0 "No_Display" 1 "Slow_vehicle_ahead" ;
VAL_ 719 RollingCounter_IFC7 15 "Invalid_value" ;
VAL_ 719 HMA_Sts 0 "OFF" 1 "Passive" 2 "Active" 3 "Temporary_fault" 4 "Permanently_fault" 5 "Suppression_Condition" 6 "LowTransform_Suppression" 7 "HighTransform_Suppression" ;
VAL_ 719 HMA_HibeamReq 0 "High_Beam_Request_OFF" 1 "High_Beam_Request_ON" 2 "High_Beam_And_Laser_Beam_Request_ON" ;
VAL_ 719 IDC_L2_FWshrReq 0 "OFF" 1 "Wiper_Wash" 2 "Wash_in_Auto_Mode" ;
VAL_ 719 TSRSpdLimWarnAu 0 "No_Warning" 1 "Warning" ;
VAL_ 719 IDC_L2_FWiperReq 0 "Wiper_Off" 1 "Wiper_Auto_Or_Intermittent" 2 "Low_Speed" 3 "High_Speed" 7 "Error" ;
VAL_ 719 TSRWarnResp 0 "OFF" 1 "ON" ;
VAL_ 719 IDC_L2_TurnLightReq 0 "Turn_OFF" 1 "Turn_Left_ON" 2 "Turn_Right_ON" 3 "Turn_OFF_Light_Swt" ;
VAL_ 719 IDC_L2_EmgyLightReq 0 "Turn_OFF" 1 "Turn_ON" ;
VAL_ 719 TSR_Snvty 31 "Invalid" ;
VAL_ 719 TSRSpdLimWarn 0 "No_Warning" 1 "Warning" ;
VAL_ 719 TSRTrfcSignVal 0 "None" 1 "Snow" 2 "Fog" 3 "ThunderStorm" 4 "Rain" 5 "FWay" 6 "EFWay" 7 "Straight" 8 "FrontageLeft" 9 "TurnLeftRight" 10 "FrontageRight" 11 "Right" 12 "TurnRight" 13 "Left" 14 "TurnLeft" 15 "RelieveNoOvertake" 16 "NoOvertake" 17 "StopGiveWay" 18 "GiveWay" 19 "NoPass" 20 "NoEntry" 21 "NoCar" 22 "NoTruck" 23 "NoBus" 24 "NoTurnaround" 25 "NoStraightLeftTurn" 26 "NoStraightRightTurn" 27 "NoLeftRightTurn" 28 "NoLeftTurn" 29 "NoRightTurn" 30 "NoStraight" 31 "WarnKids" 32 "WarnPed" 33 "WarnBike" 34 "WarnWorks" 35 "WarnWildanimal" 36 "WarnCattle" 37 "ACCidentProneSection" 38 "Town" 39 "Slow" 40 "SharpTurnR" 41 "SharpTurnL" 42 "ReverseCurveL" 43 "ReverseCurveR" 44 "ContinuousBend" 45 "Crossroads" 46 "ConfluenceR" 47 "ConfluenceL" 48 "Rain_Wetness" 49 "Snow_Icy" 50 "Time" 51 "Distance_For" 52 "Distance_In" 53 "Straight" 54 "FrontageLeft" 55 "TurnLeftRight" 56 "FrontageRight" 57 "Right" 58 "Turn_Right" 59 "Left" 60 "Turn_Left" 61 "Highway_Start" 62 "Highway_End" 63 "Mortorway_Start" 64 "Mortorway_End" 65 "City_Entry" 66 "City_Exit" 67 "Residential_zones_Entry" 68 "Residential_zones_Exit" 69 "Trailer" 255 "Invalid" ;
VAL_ 719 TSRTrfcSignValCfdc 0 "Null" 1 "Implicit" 2 "Explicit" ;
VAL_ 719 TSRSpdLimSts 0 "No_Speed_Limit" 1 "Speed_Limit" 2 "Speed_Limit_Cancel" ;
VAL_ 719 TSRSpdLim 0 "No_Display" 1 "SPL5" 2 "SPL10" 3 "SPL15" 4 "SPL20" 5 "SPL25" 6 "SPL30" 7 "SPL35" 8 "SPL40" 9 "SPL45" 10 "SPL50" 11 "SPL55" 12 "SPL60" 13 "SPL65" 14 "SPL70" 15 "SPL75" 16 "SPL80" 17 "SPL85" 18 "SPL90" 19 "SPL95" 20 "SPL100" 21 "SPL105" 22 "SPL110" 23 "SPL115" 24 "SPL120" 25 "SPL125" 26 "SPL130" 27 "SPL135" 28 "SPL140" 29 "SPL145" 30 "SPL150" 63 "Invalid" ;
VAL_ 719 TSRSts 0 "OFF" 1 "Fusion_mode" 2 "Vision_mode" 3 "Navigation_only_mode" 4 "Failed" 5 "ISA_Failed" 6 "ISA_Off" ;
VAL_ 719 TSRSpdLimCfdc 0 "Null" 1 "Implicit" 2 "Explicit" ;
VAL_ 719 TSRSpdLimUnit 0 "Unknown" 1 "KMH" 2 "MPH" ;
VAL_ 719 TSRResp 0 "OFF" 1 "ON" ;
VAL_ 719 TSR_TFL1_LightType 0 "No_warning" 1 "S" 2 "LT" 3 "RT" 4 "TA" 5 "SLT" 6 "SRT" 7 "SLRT" 8 "STA" 9 "Red_light_allow_to_turn_left" 10 "Red_light_allow_to_turn_right" ;
VAL_ 719 TSR_TFL5_LightTime 0 "Valid_value" ;
VAL_ 719 TSR_TFL4_LightTime 0 "Valid_value" ;
VAL_ 719 TSR_TFL3_LightTime 0 "Valid_value" ;
VAL_ 719 TSR_TFL2_LightTime 0 "Valid_value" ;
VAL_ 719 TSR_TFL1_LightTime 0 "Valid_value" ;
VAL_ 719 TSRConSpdLimWarn 0 "No_Warning" 1 "Warning" ;
VAL_ 719 TSRConSpdLim 0 "No_Display" 1 "SPL_5" 2 "SPL_10" 3 "SPL_15" 4 "SPL_20" 5 "SPL_25" 6 "SPL_30" 7 "SPL_35" 8 "SPL_40" 9 "SPL_45" 10 "SPL_50" 11 "SPL_55" 12 "SPL_60" 13 "SPL_65" 14 "SPL_70" 15 "SPL_75" 16 "SPL_80" 17 "SPL_85" 18 "SPL_90" 19 "SPL_95" 20 "SPL_100" 21 "SPL_105" 22 "SPL_110" 23 "SPL_115" 24 "SPL_120" 25 "SPL_125" 26 "SPL_130" 27 "SPL_135" 28 "SPL_140" 29 "SPL_145" 30 "SPL_150" 63 "Invalid" ;
VAL_ 846 Sync_SyncTime 0 "Valid_value" ;
VAL_ 846 Sync_OVS 0 "Valid_value" ;
VAL_ 846 Sync_SGW 0 "Valid_value" ;
VAL_ 846 Sync_Resd 0 "Valid_value" ;
VAL_ 846 Sync_Counter 0 "Valid_value" ;
VAL_ 846 Sync_TimeDomain 0 "Valid_value" ;
VAL_ 846 Sync_CRC 0 "Valid_value" ;
VAL_ 846 Sync_Type 0 "Valid_value" ;
VAL_ 259 EngState_PHEV 0 "Stand_by" 1 "Ready" 2 "Cranking" 3 "Running" 4 "Stopping" 5 "Finish" 6 "Autostopping" ;
VAL_ 273 EngSpdVldty 0 "Invalid" 1 "Valid" 2 "Initial_Value" ;
VAL_ 283 VMCFucActvSts 0 "Initial_value" 1 "NoVMCFunctionActive" 2 "VACActiveAndPSCNotActive" 3 "VACActiveAndPSCActive" 4 "ITRActive" 5 "VACNotActiveAndPSCActive" 6 "CWCActive" 7 "SRCActive" 8 "BSCActive" 9 "BSCNotActiveAndWheelError" 10 "CCSActv" ;
VAL_ 283 AccrPedlAntiMsstpngSts 0 "Initial_Value" 1 "Not_Active" 2 "Active" 3 "Limited_Function" ;
VAL_ 283 IOTACoolingResp 0 "No_response" 1 "Response" ;
VAL_ 283 VCU_MaxSpdLimit 3001 "Invalid" ;
VAL_ 283 RollingCounter_VCU26 15 "Invalid_value" ;
VAL_ 283 DrvTrqReqOvld 0 "No_driver_override" 1 "Driver_override" 3 "Invalid_values" ;
VAL_ 283 ActTotWheelTrq 8191 "Invalid" ;
VAL_ 283 VCU_DrvReqTqWhl 4095 "Invalid" ;
VAL_ 283 MaxPsblPosWheelTrq 4095 "Invalid" ;
VAL_ 283 MinPsblNegWheelTrq 4095 "Invalid" ;
VAL_ 283 RollingCounter_VCU21 15 "Invalid_value" ;
VAL_ 283 DrvgPrkgTrqRespFlg 0 "Initial_Value" 1 "Not_Response" 2 "Responsed" ;
VAL_ 283 DrvgPrkgTrqAvailSts 0 "Initial_Value" 1 "Not_Available" 2 "Available" 3 "Available_Degraded" ;
VAL_ 283 DrvTrqReqOvrdvld 0 "Invalid" 1 "Valid" ;
VAL_ 283 RollingCounter_VCU12 15 "Invalid_value" ;
VAL_ 283 PTDrvMod 0 "Default_value" 1 "EV_FWD" 2 "EV_AWD" 3 "EV_RWD" 4 "HEV_FWD" 5 "HEV_AWD" 6 "Power_Split" 7 "Power_Split_AWD" ;
VAL_ 283 DrvMod 0 "Normal_mode_started" 1 "EV_mode_started" 2 "Save_mode_started" 3 "SPORT_mode_started" 4 "AWD_normal_mode_started" 5 "Snow_mode_started" 6 "Muddy_mode_started" 7 "Sand_mode_started" 8 "ECO_mode" 9 "SPORT_plus_mode_started" 10 "OPD_mode" 11 "Auto_mode" 12 "ECOPlus_mode" 13 "Individuation_mode" 14 "Lady_mode" 15 "Wet_mode" 16 "Track_mode" 17 "Hybrid_mode" 18 "Trailer_mode" 19 "Z_mode" ;
VAL_ 283 VCU_ACCComIf 0 "No_response" 1 "Response" ;
VAL_ 283 ActDrvMod 0 "Normal_Mode" 1 "Sport_Mode" 2 "ECO_Mode" 3 "OPD_Mode" 4 "ECOplus_Mode" 5 "Snow_Mode" 8 "Mud_Mode" 9 "Sand_Mode" 10 "Sportplus_Mode" 11 "Lady" ;
VAL_ 295 AutoLmpSwtSts_HUT 0 "Non_Auto" 1 "Auto" ;
VAL_ 295 LowBeamSwtSts_HUT 0 "OFF" 1 "ON" ;
VAL_ 295 RearFogLmpSwtSts_HUT 0 "OFF" 1 "ON" ;
VAL_ 302 RollingCounter_IBC_FD1_5 15 "Invalid_value" ;
VAL_ 302 APCFailrSts 0 "No_Error" 1 "APC1_APA_driver_not_present" 2 "APC124_too_high_slope" 3 "Too_high_speed" 4 "Unexpected_EPB_Apply" 5 "Unexpected_Gear_Intervention" 6 "VehicleBlock" 7 "Error" ;
VAL_ 302 BrkgOvrdVld 0 "Invalid" 1 "Valid" ;
VAL_ 302 MEBavailability 0 "NotAvailable" 1 "Available" ;
VAL_ 302 APCSts 0 "Standby" 1 "Active_APA" 2 "Active_RPA" 3 "Active_AVP" 4 "Active_MEB" ;
VAL_ 302 RPAavailability 0 "NotAvailable" 1 "Available" 2 "TestPending" ;
VAL_ 302 APAavailability 0 "NotAvailable" 1 "Available" ;
VAL_ 302 CddApActvVehHld 0 "Flase" 1 "True" ;
VAL_ 302 AVPavailability 0 "NotAvailable" 1 "Available" 2 "TestPending" ;
VAL_ 302 DrvBrkOvrdFlg 0 "Flase" 1 "True" ;
VAL_ 302 HydBrkgActTrq 0 "Initial_value" ;
VAL_ 302 HydBrkgTrqReq 0 "Initial_value" ;
VAL_ 302 DrvBrkgTrqReq 0 "Initial_value" ;
VAL_ 302 RollingCounter_IBC_FD1_2 15 "Invalid_value" ;
VAL_ 302 BrkHldActvSts 0 "Initial_value" 1 "Not_active" 2 "Active" ;
VAL_ 302 BrkHldAvailSts 0 "Initial_value" 1 "Not_available" 2 "Available" ;
VAL_ 302 BrkgTrqModResp 0 "Initial_value" 1 "NotActive" 2 "APA_Active" 3 "ACC_Active" ;
VAL_ 302 PrkgBrkgTrqAvailSts 0 "Initial_value" 1 "Not_available" 2 "Available" 3 "Degraded1" 4 "Degraded2" 5 "Overspeed" ;
VAL_ 302 DrvgBrkgTrqAvailSts 0 "Initial_value" 1 "Not_available" 2 "Available" 3 "Degraded1" 4 "Degraded2" ;
VAL_ 302 RollingCounter_IBC_FD1_1 15 "Invalid_value" ;
VAL_ 302 PushrodStauts 0 "Not_Pressed_Init_Default" 1 "Pressed" 3 "Error" ;
VAL_ 302 InpRodStkSts 0 "Valid" 1 "Invalid" ;
VAL_ 302 FWA_Warn 0 "No_failure_Init_Default" 1 "Warnig_level_1_for_high_Temp_of_Brake_system" 2 "Warnig_level_2_for_high_Temp_of_Brake_system" ;
VAL_ 302 PlungerPressSts 0 "Valid" 1 "Invalid" ;
VAL_ 311 RWSAngMinLimn 1023 "Initial_Value" ;
VAL_ 311 RWSAngMaxLimn 1023 "Initial_Value" ;
VAL_ 311 RollingCounter_ABS3 15 "Invalid_value" ;
VAL_ 311 ABSActv 0 "Not_Active" 1 "Active" ;
VAL_ 311 EBDActv 0 "Not_Active" 1 "Active" ;
VAL_ 311 VehSpdVld 0 "Invalid" 1 "Valid" ;
VAL_ 311 EBDFailSts 0 "No_Failure" 1 "Failure" ;
VAL_ 311 ABSFailSts 0 "No_Failure" 1 "Failure" ;
VAL_ 311 DrvTrqIncReqActv_FA 0 "Not_Active" 1 "Active" ;
VAL_ 311 DrvTrqRedReqActv_FA 0 "Not_Active" 1 "Active" ;
VAL_ 311 RollingCounter_ESP7 15 "Invalid_value" ;
VAL_ 311 APS_EngTrqReqEna 0 "No_demand" 1 "Valid_torque_demand" ;
VAL_ 311 LgtCtrlrFailr 0 "No_Error" 1 "Vehicle_Blocked" 2 "Unexpected_GearPosition" 3 "Unexpected_EPB_Action" 5 "Unexpected_GearIntervention" 6 "Active_Braking_failure" 7 "Invalid" ;
VAL_ 311 RollingCounter_ESP1 15 "Invalid_value" ;
VAL_ 311 MSRActv_RA 0 "Inactive" 1 "Active" ;
VAL_ 311 ESP_MasterCylBrkPressVld 0 "Invalid" 1 "Valid" ;
VAL_ 311 VDCActv 0 "Not_active" 1 "Active" ;
VAL_ 311 MSRActv 0 "Not_active" 1 "Active" ;
VAL_ 311 PTCActv 0 "Not_active" 1 "Active" ;
VAL_ 311 BTCActv 0 "Not_Active" 1 "Active" ;
VAL_ 311 PTCActv_RA 0 "Inactive" 1 "Active" ;
VAL_ 311 BTCActv_RA 0 "Inactive" 1 "Active" ;
VAL_ 311 ESPFuncOffSts 0 "Available_ON" 1 "Unavailable_OFF" ;
VAL_ 311 ESPBrkLmpCtrl 0 "Brake_Light_OFF" 1 "Brake_Light_ON" ;
VAL_ 311 ESPFailSts 0 "No_Failure" 1 "Failure" ;
VAL_ 311 RollingCounter_ESP2 15 "Invalid_value" ;
VAL_ 311 DrivingModDis 0 "Standard" 1 "Sport" 2 "Snow" 3 "Mud" 4 "Sand" 5 "_4L" 6 "Economic" 7 "Mode_Unkown" 8 "Auto" 9 "Sport_Up" 10 "Off_Road" 11 "Standard_2H" 12 "Expert" 13 "Standard_4H" 14 "Failed" 15 "Invalid_Value" 16 "Snow_4H" 17 "Normal_4L" 18 "Rock_4L" 19 "Pothle_4L" 20 "Mud_Or_Sand_4L" 21 "Mountain_4L" 22 "Turbo" 23 "Race" 24 "Grass_Gravel" 25 "Reserved" 26 "Wade_4H" 27 "Wade_4L" 28 "2H" 29 "4H" 30 "Noviciate" ;
VAL_ 311 DrivingModReq_ESP 0 "No_Terrain_Control" 1 "Standard" 2 "Sport" 3 "Snow_Nex" 4 "Expert" 5 "Deep_Mud" 6 "_2H" 7 "Soft_Sand" 8 "_4H" 9 "_4L" 10 "Economic" 11 "Snow_ESOF" 12 "Snow_TOD" 13 "Off_Road" 14 "Sport_Up" 15 "Invalid_Value" 16 "Standard_2H" 17 "Noviciate" 18 "Standard_4H" 19 "Snow_4H" 20 "Normal_4L" 21 "Rock_4L" 22 "Pothole_4L" 23 "Mud_or_Sand_4L" 24 "Mountain_4L" 25 "Turbo" 26 "Race" 27 "Grass_Gravel" 28 "Uneven_Nex" 29 "Wade_4H" 30 "Wade_4L" 31 "Climb_4L" ;
VAL_ 311 AVHErrSts 0 "No_Failure" 1 "Failure_When_AVH_Is_On_Need" 2 "Failure_When_Is_Not_On_Need" ;
VAL_ 311 AVHSts 0 "OFF" 1 "Standby" 2 "Active" ;
VAL_ 311 CDPActv 0 "Not_Active" 1 "Active" ;
VAL_ 311 HDCCtrl 0 "OFF" 1 "On_Active_Braking" 2 "On_Not_Active_Braking" ;
VAL_ 311 CDDActv 0 "Not_Active" 1 "Active" ;
VAL_ 311 CDDAvailable 0 "Not_Available" 1 "Available" ;
VAL_ 311 AWBAvailable 0 "Unusable" 1 "Usable" ;
VAL_ 311 AWBActv 0 "Not_Active" 1 "Active" ;
VAL_ 311 HHCSts 0 "Not_Active" 1 "Active" ;
VAL_ 311 AEBIBActv 0 "Not_active" 1 "Active" ;
VAL_ 311 AEBBAActv 0 "Not_active" 1 "Active" ;
VAL_ 311 AEBAvailable 0 "Unusable" 1 "Usable" ;
VAL_ 311 ABPAvailable 0 "Unusable" 1 "Usable" ;
VAL_ 311 ABPActv 0 "Not_Active" 1 "Active" ;
VAL_ 311 ABAavailable 0 "Unusable" 1 "Usable" ;
VAL_ 311 ABAActv 0 "Not_Active" 1 "Active" ;
VAL_ 311 ESP_DiagActv 0 "ESP_Diagnosis_Is_Inactive" 1 "ESP_Diagnosis_Is_Active" ;
VAL_ 311 CTABrkAvailable 0 "Not_Available" 1 "Available" ;
VAL_ 311 BrkDskOvrheatd 0 "Not_High" 1 "Temp_Too_High" ;
VAL_ 311 NoBrkForce 0 "EXist_brake_force" 1 "No_brake_force" ;
VAL_ 311 VehStandstill 0 "Not_standstill" 1 "Standstill" 2 "Invalid_or_short_unavailability_max3s" ;
VAL_ 311 RWSAngLimnSts 0 "No_Limit" 1 "Limiting_Rear_Steering_Angle" ;
VAL_ 311 RWSAngLimnVld 0 "Invalid" 1 "Valid" ;
VAL_ 315 RollingCounter_ABS2 15 "Invalid_value" ;
VAL_ 315 WssRREdgesSumVld 0 "Invalid" 1 "Valid" ;
VAL_ 315 WssRLEdgesSumVld 0 "Invalid" 1 "Valid" ;
VAL_ 315 RRWheelSpdVld 0 "Invalid" 1 "Valid" ;
VAL_ 315 RRWheelDriveDirection 0 "Invalid_values" 1 "Forward" 2 "Backward" 3 "Stop" ;
VAL_ 315 RLWheelSpdVld 0 "Invalid" 1 "Valid" ;
VAL_ 315 RLWheelDriveDirection 0 "Invalid_value" 1 "Forward" 2 "Backward" 3 "Stop" ;
VAL_ 315 DrvTrqIncReqActv_RA 0 "Not_Active" 1 "Active" ;
VAL_ 315 DrvTrqRedReqActv_RA 0 "Not_Active" 1 "Active" ;
VAL_ 315 RollingCounter_EPB1 15 "Invalid_value" ;
VAL_ 315 ESP_DSTSts 0 "Not_Active" 1 "Active" 2 "Not_Available" ;
VAL_ 315 EPBRedLmpSts 0 "Lamp_OFF" 1 "Lamp_ON" 2 "Lamp_Flash" ;
VAL_ 315 EPBErrSts 0 "Undefined" 1 "No_Error" 2 "Error" 3 "Diagnosis" ;
VAL_ 315 EPBSts 0 "Released" 1 "Closed" 2 "In_Progress" 3 "Unknown" ;
VAL_ 315 EPB_SwtPosn 0 "Neutral" 1 "Release" 2 "Apply" ;
VAL_ 315 EPB_SwtPosnVld 0 "Invalid" 1 "Valid" ;
VAL_ 315 RollingCounter_ABS1 15 "Invalid_value" ;
VAL_ 315 WssFREdgesSumVld 0 "Invalid" 1 "Valid" ;
VAL_ 315 WssFLEdgesSumVld 0 "Invalid" 1 "Valid" ;
VAL_ 315 FRWheelSpdVld 0 "Invalid" 1 "Valid" ;
VAL_ 315 FRWheelDriveDirection 0 "Invalid_values" 1 "Forward" 2 "Backward" 3 "Stop" ;
VAL_ 315 FLWheelSpdVld 0 "Invalid" 1 "Valid" ;
VAL_ 315 FLWheelDriveDirection 0 "Invalid_values" 1 "Forward" 2 "Backward" 3 "Stop" ;
VAL_ 320 RollingCounter_RWA_FD2_2 15 "Invalid_value" ;
VAL_ 320 SBWActr_PinionAngSpd_Backup 0 "Initial_value" ;
VAL_ 320 SBWActr_PinionAng_Backup 0 "Initial_value" ;
VAL_ 326 SuspLvlTrigSrc 0 "No_leveling" 1 "leveling_by_switch" 2 "leveling_by_driving_mode" 3 "leveling_by_expert_mode" 4 "leveling_by_vehicle_speed" 5 "leveling_by_key" 6 "leveling_by_APP" 7 "leveling_by_kicking" ;
VAL_ 326 TarLvlChg 0 "Normal" 1 "Low_Level_2_EasyAccess" 2 "Low_Level_1_Highway" 3 "High_Level_1_Off_road1" 4 "High_Level_2_Off_road2" 5 "High_Level_3_Extra_off_road" 6 "Locked_Low_Level_2_Locked_EasyAccess" 7 "Rear_Axle_Loading" ;
VAL_ 326 CurrLvlCtrlMode 0 "Normal" 1 "Low_Level_2_EasyAccess" 2 "Low_Level_1_Highway" 3 "High_Level_1_Off_road1" 4 "High_Level_2_Off_road2" 5 "High_Level_3_Extra_off_road" 6 "Locked_Low_Level_2_Locked_EasyAccess" 7 "Rear_Axle_Loading" ;
VAL_ 326 LvlAdjmtSts 0 "No_Action" 1 "Lowering" 2 "Lifting" 3 "Pending" 4 "Rear_lowering" 5 "Rear_lifting" 6 "Rear_pending" ;
VAL_ 327 RollingCounter_EPS3 15 "Invalid_value" ;
VAL_ 327 EPS_HADHndShkRespSt 0 "OFF" 4 "HWP_Active" 5 "Failure" ;
VAL_ 327 EPS_AngCmdOverRange 0 "Not_over_ange" 1 "Over_ange" ;
VAL_ 327 EPS_AvailStsforHAD 0 "Not_available" 1 "Available_degraded" 2 "Available" ;
VAL_ 327 EPS_SteerWheelAngVld 0 "Invalid" 1 "Valid" ;
VAL_ 327 EPS_HADerror_Reason 0 "No_Error" 1 "IDC_L3_Request_Is_Invalid" 2 "IDC_L3_Communication_Error" 3 "IDC_L3_Fault" 4 "EPS_Internal_Error_Detected" 5 "Under_Voltage_Detected" 6 "Over_Voltage_Detected" 7 "ADS_Requested_Steering_Angle_Is_Above_The_Limit" 8 "Change_Rate_Of_ADS_Requested_Steering_Angle_Is_Above_The_Limit" 9 "Vehicle_Speed_Wheel_Speed_Error" 10 "IDC_L2_Error" 11 "TAS_Sensor_Error" ;
VAL_ 327 EPS_SteerWheelSpdSign 0 "Left_Positive" 1 "Right_Negative" ;
VAL_ 327 EPS_SteerWheelSpd 32767 "Invalid" ;
VAL_ 327 EPS_SteerWheelAngSign 0 "Left_Positive" 1 "Right_Negative" ;
VAL_ 327 EPS_SteerWheelAng 32767 "Invalid" ;
VAL_ 327 RollingCounter_EPS2 15 "Invalid_value" ;
VAL_ 327 EPS_LKATrqOvlDlvdSts 0 "Not_Active" 1 "Active" 2 "Temporary_Inhibit" 3 "Permanently_Failed" ;
VAL_ 327 EPS_DrvInpTrqVal_HighResVld 0 "Invalid" 1 "Valid" ;
VAL_ 327 EPS_LKATorqOvrlDlvdVld 0 "Invalid" 1 "Valid" ;
VAL_ 327 EPS_LKAAngDlvdSts 0 "Not_active" 1 "Active" 2 "Temporary_inhibit" 3 "Permanently_failed" ;
VAL_ 327 RollingCounter_EPS1 15 "Invalid_value" ;
VAL_ 327 EPS_SteerMod 0 "Comfort_Mode" 1 "Sport_Mode" 2 "Handiness_Mode" ;
VAL_ 327 SteerSysFltTyp 0 "Initial_value" 1 "Adas_AngReqLimit_Exceed" 2 "Adas_AngSpdReqLimit_Exceed" 3 "Adas_TrqReqLimit_Exceed" 4 "Adas_TrqSpdReqLimit_Exceed" 5 "Adas_Msg_Invalid" 6 "Adas_VehSpdLimit_Exceed" 7 "Steer_Sys_Failure" 8 "Steer_override" 9 "Steer_Tgt_LimitExceed" ;
VAL_ 327 EPS_AvailSts 0 "Temporary_Inhibit" 1 "Available_For_Control" 2 "Active" 3 "Permanently_Failed" ;
VAL_ 327 EPS_InterferDetdVld 0 "Invalid" 1 "Valid" ;
VAL_ 327 EPS_InterferDetd 0 "No_Interference" 1 "Interference" ;
VAL_ 327 EPS_DSTCtrlSts 0 "Permanently_Fail" 1 "Temporary_Inhibit" 2 "Available_For_Control" 3 "Active" ;
VAL_ 327 EPS_FailSts 0 "No_Fault" 1 "Permanent_Error_Detected" 2 "Intermittent_Error_Detected" ;
VAL_ 327 EPS_TrqSnsrSts 0 "Normal" 1 "Abnormal" ;
VAL_ 332 RollingCounter_RWA_FD1_2 15 "Invalid_value" ;
VAL_ 332 SBWActr_PinionAngSpd 0 "Initial_value" ;
VAL_ 332 SBWActr_PinionAng 0 "Initial_value" ;
VAL_ 346 RollingCounter_LBM2 15 "Invalid_value" ;
VAL_ 346 LBMPackVoltageASIL 16383 "Invalid" ;
VAL_ 356 RollingCounter_EPS_FD2_3 15 "Invalid_value" ;
VAL_ 356 RollingCounter_EPS_FD2_2 15 "Invalid_value" ;
VAL_ 356 EPS_LKATrqOvlDlvdSts_Backup 0 "Not_active" 1 "Active" 2 "Temporary_inhibit" 3 "Permanently_failed" ;
VAL_ 356 EPS_LKAAngDlvdSts_Backup 0 "Not_active" 1 "Active" 2 "Temporary_inhibit" 3 "Permanently_failed" ;
VAL_ 356 EPS_HADHndShkRespSt_Backup 0 "Off" 1 "Reserved" 2 "Reserved" 3 "Reserved" 4 "HWP_Active" 5 "Failure" ;
VAL_ 356 EPS_AvailSts_Backup 0 "Temporary_inhibit" 1 "Available_for_control" 2 "Active" 3 "Permanently_failed" ;
VAL_ 356 EPS_DrvInpTrqVal_HiResVld_Backup 0 "Invalid" 1 "Valid" ;
VAL_ 356 EPS_AvailStsforHAD_Backup 0 "Not_available" 1 "Available_degraded" 2 "Available" ;
VAL_ 356 EPS_HADerror_Reason_Backup 0 "No_Error" 1 "IDC_L3_Backupquest_Is_Invalid_" 2 "IDC_L3_Communication_Error" 3 "IDC_L3_Fault" 4 "EPS_Internal_Error_Detected_" 5 "Under_Voltage_Detected_" 6 "Over_Voltage_Detected_" 7 "ADS_Backupquested_Steering_Angle_Is_Above_The_Limit" 8 "Change_Rate_Of_ADS_Backupquested_Steering_Angle_Is_Above_The_Limit_" 9 "Vehicle_Speed_Wheel_Speed_Error" 10 "IDC_L2_Error" 11 "TAS_Sensor_Error" ;
VAL_ 356 EPS_LKATorqOvrlDlvdVld_Backup 0 "Invalid" 1 "Valid" ;
VAL_ 356 RollingCounter_EPS_FD2_1 15 "Invalid_value" ;
VAL_ 356 EPS_TrqSnsrSts_Backup 0 "Normal" 1 "Abnormal" ;
VAL_ 356 EPS_InterferDetdVld_Backup 0 "Invalid" 1 "Valid" ;
VAL_ 356 EPS_SteerWheelSpd_Backup 32767 "Invalid" ;
VAL_ 356 EPS_SteerWheelSpdSign_Backup 0 "Left_Positive" 1 "Right_Negative" ;
VAL_ 356 EPS_SteerWheelAng_Backup 32767 "Invalid" ;
VAL_ 356 EPS_SteerWheelAngVld_Backup 0 "Invalid" 1 "Valid" ;
VAL_ 356 EPS_SteerWheelAngSign_Backup 0 "Left_Positive" 1 "Right_Negative" ;
VAL_ 356 EPS_InterferDetd_Backup 0 "No_Interference" 1 "Interference" ;
VAL_ 356 EPS_AngCmdOverRange_Backup 0 "Not_over_ange" 1 "Over_ange" ;
VAL_ 356 EPS_FailSts_Backup 0 "No_fault" 1 "Permanent_Error_Detected" 2 "Intermittent_Error_Detected" ;
VAL_ 357 TurnLmpSwtErrSts 0 "No_Error" 1 "Error" ;
VAL_ 357 HiBeamSwtSts 0 "OFF" 1 "ON" ;
VAL_ 357 OverVehBeamSwtSts 0 "OFF" 1 "ON" ;
VAL_ 357 LTurnLmpSwtSts 0 "OFF" 1 "ON" ;
VAL_ 357 RTurnLmpSwtSts 0 "OFF" 1 "ON" ;
VAL_ 357 FrntWiprSwtSts 0 "Wiper_Off" 1 "Wiper_Auto_Or_Intermittent" 2 "Low_Speed" 3 "High_Speed" 7 "Error" ;
VAL_ 357 FrntWshrSwtSts 0 "OFF" 1 "Wiper_Wash" 2 "Wash_in_Auto_Mode" ;
VAL_ 367 RollingCounter_RSDS_R_5 15 "Invalid value" ;
VAL_ 367 RiTarSts 0 "Target_Invalid" 1 "Target_Valid" 2 "No_Target" ;
VAL_ 367 RollingCounter_RSDS_R_4 15 "Invalid value" ;
VAL_ 367 ObjStsRi 0 "Invalid" 1 "New" 2 "Mature" 3 "Coasted" ;
VAL_ 367 ZoneIndRi 0 "No_Object_in_the_Zone" 1 "Object_in_BSW_Zone" 2 "Object_in_CVW_Zone" 3 "Object_in_the_Shared_Zone" ;
VAL_ 367 ObjStatyRi 0 "Stationary" 1 "Not_Stationary" ;
VAL_ 367 ObjStsLe 0 "Invalid" 1 "New" 2 "Mature" 3 "Coasted" ;
VAL_ 367 ZoneIndLe 0 "No_Object_in_the_Zone" 1 "Object_in_BSW_Zone" 2 "Object_in_CVW_Zone" 3 "Object_in_the_Shared_Zone" ;
VAL_ 367 ObjStatyLe 0 "Stationary" 1 "Not_Stationary" ;
VAL_ 367 RollingCounter_RSDS_R_3 15 "Invalid value" ;
VAL_ 367 LeTarSts 0 "Target_Invalid" 1 "Target_Valid" 2 "No_target" ;
VAL_ 388 RollingCounter_VCU_FD28_2 0 "Valid_values" 15 "Invalid_value" ;
VAL_ 388 RRIntgrtdWheelSpd 0 "Initial_value" 1 "Valid_values" ;
VAL_ 388 RLIntgrtdWheelSpd 0 "Initial_value" 1 "Valid_values" ;
VAL_ 388 RollingCounter_VCU_FD28_1 0 "Valid_values" 15 "Invalid_value" ;
VAL_ 388 EstimrResutReliabt 0 "Initial_valid" 1 "Trusted" 2 "UnTrusted" ;
VAL_ 388 EstimdRoadFricCoeff 0 "Initial_value" 1 "Valid_values" ;
VAL_ 388 FRIntgrtdWheelSpd 0 "Initial_value" 1 "Valid_values" ;
VAL_ 388 FLIntgrtdWheelSpd 0 "Initial_value" 1 "Valid_values" ;
VAL_ 388 IntgrtdVehSpd 0 "Initial_value" 1 "Valid_values" ;
VAL_ 474 TSRLimSpdChngSoundSet 0 "No_action" 1 "OFF" 2 "ON" ;
VAL_ 474 ACC_OverTakingAsscSet 0 "No_action" 1 "OFF" 2 "ON" ;
VAL_ 474 OneclickClsIntellgntDrvgReq 0 "Initial_value" 1 "OFF" 2 "ON" ;
VAL_ 474 OutdPrkgReq 0 "No_action" 1 "Request" ;
VAL_ 474 CamFolwSwtReq 0 "No_Request" 1 "Request_to_Change" ;
VAL_ 474 PrkModReq 0 "No_Action" 1 "Head_parking_in" 2 "Tail_parking_in" ;
VAL_ 474 TJA_ASCruise 0 "No_Action" 1 "OFF" 2 "ON" ;
VAL_ 474 RCTA_DispSwtReq 0 "No_Request" 1 "Request_to_Change" ;
VAL_ 474 AutoPrkOutSwtReq 0 "No_Request" 1 "Request_to_Change" ;
VAL_ 474 PrkgSlotId 0 "No_Action" ;
VAL_ 474 HAVP_UseMod 0 "No_Action" 1 "Use_on_car" 2 "Use_on_mobile" ;
VAL_ 474 HUT_HAVP_APA_Permit 0 "Idle" 1 "NO" 2 "YES" ;
VAL_ 474 UserDefinedParkCmd 0 "No_Request" 1 "Request" ;
VAL_ 474 SlotNum_VR 0 "Invalid" 1 "Select_1_carport" 2 "Select_2_carport" 3 "Select_3_carport" 4 "Select_4_carport" 5 "Select_5_carport" 6 "Select_6_carport" 7 "Select_7_carport" 8 "Select_8_carport" 9 "Select_9_carport" 10 "Select_10_carport" 11 "Select_11_carport" 12 "Select_12_carport" 13 "Select_13_carport" 14 "Select_14_carport" 15 "Select_15_carport" ;
VAL_ 474 UserDefPrkMenuSelCmd 0 "No_Request" 1 "Parallel_Slot_Selected" 2 "Vertical_Slot_Selected" 3 "Request_Back_APA" 4 "Slot_adsorption_request" 5 "Clock_wise_Selected" 6 "Anticlock_wise_Selected" ;
VAL_ 474 HUT_HAVP_Set_Path_Ending 0 "No_Request" 1 "Request" ;
VAL_ 474 HUT_HAVP_Comfirm_Btn 0 "No_Request" 1 "Request" ;
VAL_ 474 HUT_HAVP_SelfParLot_Ending 0 "No_Request" 1 "Request" ;
VAL_ 474 HUT_HAVP_Set_Starting 0 "No_Request" 1 "Request" ;
VAL_ 474 BackReq_RPA 0 "No_request" 1 "Request" ;
VAL_ 474 SteerWheelsilentReq 0 "No_action" 1 "OFF" 2 "ON" ;
VAL_ 489 BackReq_AVM 0 "No_Request" 1 "Request" ;
VAL_ 490 RmtPrkRadShieldSet 0 "No_Action" 1 "OFF" 2 "Shielded_bilateral_radar" 3 "Shield_all_radars" ;
VAL_ 493 TraOvlSwtCmd 0 "No_Request" 1 "Request" ;
VAL_ 493 StartPrkgPath2Cmd 0 "No_request" 1 "Request" ;
VAL_ 493 DeletePath2Cmd 0 "No_Request" 1 "Request" ;
VAL_ 493 StartPrkgPath1Cmd 0 "No_request" 1 "Request" ;
VAL_ 493 DeletePath1Cmd 0 "No_Request" 1 "Request" ;
VAL_ 493 SelPrkgFctnCmd 0 "No_selection" 1 "Select_APA_parking" 2 "Select_P2P_parking" 3 "Select_Explore_Forward" 4 "Select_drive_back" 5 "Select_HAVP_Parking" 6 "Select_PAVP_Parking" ;
VAL_ 493 P2P_PrkgDirectSwtCmd 0 "No_Request" 1 "Request" ;
VAL_ 493 PathLrngFinshCmd 0 "No_request" 1 "Request" ;
VAL_ 493 PathLrngStartCmd 0 "No_request" 1 "Request" ;
VAL_ 493 ParkMdlCmd 0 "No_request" 1 "Request" ;
VAL_ 493 BackReq_APS 0 "No_Request" 1 "Request" ;
VAL_ 493 SelPrkOutDirReq 0 "No_selection" 1 "Park_out_front_vertical_head_out" 2 "Park_out_rear_vertical_tail_out" 3 "Park_out_left_parallel_left_out" 4 "Park_out_right_parallel_right_out" 5 "Park_out_left_vertical_left_out" 6 "Park_out_right_vertical_right_out" ;
VAL_ 493 PrkInDirChoice 0 "None" 1 "Tail_in" 2 "Head_in" ;
VAL_ 494 APSSwtReq_VR 0 "No_Action" 1 "OFF" 2 "ON" ;
VAL_ 494 APSPrkgTypSeln 0 "No_Select" 1 "Select_Parallel_Parking" 2 "Select_Vertical_Parking" ;
VAL_ 494 SDWSwtSet 0 "No_Request" 1 "Request" ;
VAL_ 545 RollingCounter_DCT5 15 "Invalid_value" ;
VAL_ 545 ShiftLeverPosn_SBWM 0 "P" 1 "D" 2 "N" 3 "R" 4 "M" 5 "Blank" 7 "Invalid_value" ;
VAL_ 545 TGS_LEVER 0 "Select_lever_in_position_P" 5 "Select_lever_in_position_D" 6 "Select_lever_in_position_N" 7 "Select_lever_in_position_R" 8 "Select_lever_in_position_M" 14 "Intermediate_position" 15 "Invalid" ;
VAL_ 545 TGS_LEVERValid 0 "Invalid_Value" 1 "Valid_Value" ;
VAL_ 555 RollingCounter_HOD_1 15 "Invalid_value" ;
VAL_ 555 HOD_HandOffSts 0 "Initial_Value" 1 "HANDS_OFF_DETECTED" 2 "HANDS_OFF_NOT_DETECTED" 3 "HANDS_NOT_AVAILABLE" 4 "HANDS_OFF_ERROR" 15 "SNA" ;
VAL_ 555 HOD_RespErr 0 "NO_ERROR" 1 "ERROR" ;
VAL_ 555 HOD_ErrInfo 0 "NO_ERROR" 1 "HOD_EEPROM_ERROR" 2 "HOD_ROM_ERROR" 3 "HOD_WATCHDOG_ERROR" 4 "HOD_CPU_ERROR" 5 "HOD_GUARD_INTERRUPTION_ERROR" 6 "HOD_SENSE_INTERRUPTION_ERROR" 7 "HOD_CPU_DEFECT_OR_MAT_SHORTAGE" 8 "UNDERVOLTAGE_ERROR" 9 "OVERVOLTAGE_ERROR" 10 "HOD_CODING_ERROR" 11 "HOD_GENERIC_SYSTEM_ERROR" 15 "SNA" ;
VAL_ 570 CustomSwtSts_Park 0 "Released" 1 "Pressed" 2 "Error" 3 "Invalidation" ;
VAL_ 579 LgtFolwDistanceSet 0 "Initial_value" 1 "Tight_gap" 2 "Proper_gap" 3 "Large_gap" ;
VAL_ 579 IntellgntAsscLmpEnaReq 0 "Initial_value" 1 "Off" 2 "Full_bright" 3 "Olny_Parking_on" ;
VAL_ 579 UsrExperiProgAuthorSts 0 "Initial_Value" 1 "Unauthorize" 2 "Authorized" ;
VAL_ 579 SidePrkgReq 0 "Initial_value" 1 "OFF" 2 "ON" 3 "Resvered" ;
VAL_ 579 NOAFuncSet 0 "Initial_value" 1 "OFF" 2 "ON" ;
VAL_ 579 OvertakingLightModReq 0 "Initial_value" 1 "OFF" 2 "Auto_beam" 3 "Auto_beam_and_whistle" ;
VAL_ 579 IDsceneModReq 0 "Initial_value" 1 "Commuting_mode" 2 "Comfort_mode" 3 "Distract" ;
VAL_ 579 PassETCEnaReq 0 "Initial_value" 1 "No_request" 2 "Request" ;
VAL_ 579 DeviateSpdPreReq 0 "Valid_values" 63 "Invalid" ;
VAL_ 579 StartReminderEnaReq 0 "Initial_value" 1 "OFF" 2 "ON" ;
VAL_ 579 DeviateSpdFixdValReq 0 "Valid_values" 63 "Invalid" ;
VAL_ 579 HandsoffModReq 0 "Initial_value" 1 "HandsOff" 2 "Attention_And_HandsOff" ;
VAL_ 579 HWA_FaststSwtReq 0 "Initial_value" 1 "OFF" 2 "ON" 3 "Resvered" ;
VAL_ 579 DeviateSpdModSwtReq 0 "Initial_value" 1 "Fixed_value" 2 "Percentage" 3 "Resvered" ;
VAL_ 579 MapStatus 0 "Unauthorize" 1 "Authorize" ;
VAL_ 579 ADAS_gpsAuthSys 0 "Unauthorize" 1 "Authorize" ;
VAL_ 579 PrivacySts 0 "Unauthorize" 1 "Authorize" ;
VAL_ 579 UNP_SwtReq 0 "OFF" 1 "ON" ;
VAL_ 579 NOH_Act_Req 0 "Deactivate" 1 "Activate" ;
VAL_ 579 NOH_Swt_Req 0 "OFF" 1 "ON" ;
VAL_ 579 AVM_3DAngleReq 0 "No_request" 511 "Invalid" ;
VAL_ 579 PrkAreaSts 0 "No_Parking_area" 1 "Parking_area" 2 "Unknown" ;
VAL_ 579 BeginnerModSts 0 "Initial_value" 1 "OFF" 2 "ON" ;
VAL_ 579 OneClickAutDrvgSts 0 "Initial_Value" 1 "Choose" ;
VAL_ 579 HandsoffTimSet 0 "Initial" 1 "Handsoff_time_is_normal" 2 "Handsoff_time_is_long" ;
VAL_ 579 TraLightSwtReq 0 "OFF" 1 "ON" ;
VAL_ 580 InrMalfct 0 "No_Error" 1 "Error" ;
VAL_ 581 RollingCounter_ABM2 15 "Invalid_value" ;
VAL_ 581 VehDynYawRateVld 0 "Invalid" 1 "Valid" ;
VAL_ 581 VehLatAccelVld 0 "Invalid" 1 "Valid" ;
VAL_ 581 VehLgtAccelVld 0 "Invalid" 1 "Valid" ;
VAL_ 589 DrvBehvSts 0 "No_Action" 1 "Smoking" 2 "on_the_phone" 3 "Drinking" 7 "Invalid" ;
VAL_ 589 DMSSts 0 "Blindness" 1 "Error" 2 "Active" 3 "Not_Active" 7 "Invalid" ;
VAL_ 589 HeadDetn 0 "No" 1 "Yes" ;
VAL_ 589 DrowsnsLvl_ACC 0 "No_Drowsiness" 1 "Low_level_Drowsiness" 2 "Middle_level_Drowsiness" 3 "Hi_level_Drowsiness" 7 "Invalid" ;
VAL_ 589 DistrctnLvl_ACC 0 "No_distraction" 1 "Low_level_distraction" 2 "Middle_level_distraction" 3 "High_level_distraction" 7 "Invalid" ;
VAL_ 589 DrvGazSts 0 "Initial_value" 1 "Gaze_towards_forward" 2 "Gaze_away" 3 "Gaze_towards_left" 4 "Gaze_towards_right" 5 "Gaze_blocked" ;
VAL_ 596 LeSideDoRollSts 0 "No_Rolling" 1 "Up1" 2 "Up2" 3 "Up3" 4 "Up4" 5 "Up5" 6 "Up6" 7 "Up7" ;
VAL_ 596 LeSideUpRollSts 0 "No_Rolling" 1 "Up1" 2 "Up2" 3 "Up3" 4 "Up4" 5 "Up5" 6 "Up6" 7 "Up7" ;
VAL_ 604 RollingCounter_BLE1 15 "Invalid_value" ;
VAL_ 604 PrkOutModSel_Rmt1 0 "No_select" 1 "Vertical_front_left_berthing" 2 "Vertical_front_right_berthing" 3 "Vertical_rear_left_berthing" 4 "Vertical_rear_right_berthing" 5 "Line_Summon" ;
VAL_ 604 MplSmtPhoneLocn 0 "Initial_value" 1 "Smartphone_in_Car" 2 "Smartphone_in_Driver_Door_Passive_Entry_Exit_range" 3 "Smartphone_in_Passenger_Door_Passive_Entry_Exit_range" 4 "Smartphone_in_Driver_Door_Auto_Lock_range" 5 "Smartphone_in_Passenger_Door_Auto_Lock_range" 6 "Smartphone_in_Trunk_Passive_Entry_Exit_range" 7 "Smartphone_in_Passive_Entry_Exit_range" 8 "Smartphone_in_Trunk_range" 9 "Smartphone_in_Welcome_Area_range" ;
VAL_ 604 ParkChokeReq_Rmt 0 "No_Request" 1 "Request" ;
VAL_ 604 PrkOutTypeReq_Rmt 0 "No_select" 1 "Parallel_park_out" 2 "Vertical_park_out" 3 "Intelligent_Summon" ;
VAL_ 604 PrkOutVehStrtReq_Rmt_Valid 0 "Invalid" 1 "Valid" ;
VAL_ 604 PrkgSyncStrtReq_Rmt 0 "No_request" 1 "Request" ;
VAL_ 604 PrkOutModSel_Rmt 0 "No_select" 1 "Front_vertical_head_park_out" 2 "Rear_vertical_tail_park_out" 3 "Left_parallel_left_park_out" 4 "Right_parallel_right_park_out" 5 "Summon_path_one_park_out" 6 "Summon_path_two_park_out" ;
VAL_ 604 ParkAbortReq_Rmt 0 "No_request" 1 "Request" ;
VAL_ 604 PrkOutVehStrtReq_Rmt 0 "No_request" 1 "Request" ;
VAL_ 604 PrkgslidReq_Rmt 0 "User_Not_Sliding_Circle" 1 "User_Sliding_Circle" ;
VAL_ 604 SmtPhoneLocn 0 "Initial_value" 1 "Smartphone_in_Car" 2 "Smartphone_in_Passive_Entry_Exit_range" ;
VAL_ 604 BLESecuritySts 0 "Initial_Value" 1 "Not_In_Security_Certification_Status" 2 "In_Security_Certification_Status" ;
VAL_ 604 BLEConnSts 0 "Initial_Value" 1 "Not_Connection" 2 "Connection" ;
VAL_ 623 RollingCounter_HUT32 15 "Invalid_value" ;
VAL_ 623 ScrnOpSts 0 "Release" 1 "Pressed" 2 "Hold" ;
VAL_ 623 Ylevel 4095 "Invalid" ;
VAL_ 623 Xlevel 4095 "Invalid" ;
VAL_ 623 ContnPrkgReqValid 0 "Valid" 1 "Invalid" ;
VAL_ 623 DetVideoLost 0 "Nomal" 1 "Video_lost" ;
VAL_ 623 PrkgCtrlModReqValid 0 "Valid" 1 "Invalid" ;
VAL_ 623 PrkgCtrlModReq 0 "No_Action" 1 "Parking_in_car" 2 "Remote_parking" 3 "Remote_searching_slot" ;
VAL_ 623 ContnPrkgReq 0 "No_Select" 1 "Select_Continue_Parking" 2 "Cancle_Parking" 3 "Invalid" ;
VAL_ 627 TrailerSts 0 "Trailer_off" 1 "Trailer_on" ;
VAL_ 629 RollingCounter_Trailer2 15 "Invalid_value" ;
VAL_ 629 TrailerStatusVld 0 "InValid" 1 "Valid" ;
VAL_ 629 TrailerStatus 0 "Trailer_off" 1 "Trailer_on" ;
VAL_ 639 IP_Err 0 "No_Error" 1 "Error" ;
VAL_ 639 IP_VehSpdUnit 0 "kph" 1 "mph" ;
VAL_ 639 IP_VehTotDistanceValid 0 "Invalid" 1 "Valid" ;
VAL_ 639 IP_ACCErr 0 "No_Error" 1 "Error" ;
VAL_ 639 IP_VehTotDistance 16777215 "Invalid" ;
VAL_ 647 RollingCounter_HC1 15 "Invalid_value" ;
VAL_ 647 ALS_FailSts 0 "No_failure" 1 "Failure" ;
VAL_ 659 IP_VelSpdDisp_Mile 255 "Invalid" ;
VAL_ 659 IP_LagueSet 0 "Chinese" 1 "English" 2 "Russian" 3 "Spaish" 4 "Portuguese" 5 "German" 6 "French" 7 "Italian" 8 "Arabic" 9 "Thai" 10 "Ukrainian" 11 "Indonesian" 12 "Norwegian" 13 "Dutch" 14 "Hebrew" 15 "Invalid_value" ;
VAL_ 659 IP_VehSpdDisp 0 "Valid" 511 "Invalid" ;
VAL_ 670 BMS_CC2LineSts 0 "Not_Connect" 1 "Connect" 2 "Error" 3 "Discharge_connected" ;
VAL_ 707 ADAS_Posn_Rehead 0 "In_path_direction" 1 "_1point417_degrees_right" 2 "Valid_values" 126 "_178point583_degrees_right" 127 "Opposite_direction" 128 "_178point583_degrees_left_181point417_degrees_right" 129 "Valid_values" 253 "_1point417_degrees_left_358point583_degrees_right" 254 "Unknown" 255 "Invalid" ;
VAL_ 707 ADAS_Posn_Spd 0 "Equal_or_less_than_negative12point8" 1 "Valid_values" 64 "Standing_still" 65 "Valid_values" 510 "Equal_or_more_than_positive_89_point_2" 511 "Invalid_data" ;
VAL_ 707 ADAS_Posn_CurLane 0 "Unknown" 1 "Emergency_lane" 2 "Single_lane_road" 3 "Left_most_lane" 4 "Right_most_lane" 5 "One_of_middle_lanes_on_road_with_three_or_more_lanes" 7 "Invalid_data" ;
VAL_ 707 ADAS_Posn_PosConfdc 7 "Invalid_value" ;
VAL_ 707 ADAS_Posn_Age 510 "More_than_2545ms" 511 "Invalid_data" ;
VAL_ 707 ADAS_Posn_PosProbb 0 "Unknown" 31 "Invalid" ;
VAL_ 707 ADAS_Posn_Offset 8191 "Invalid_data" ;
VAL_ 707 ADAS_Posn_MsgTye 0 "System_Specific" 1 "Position" 2 "Segment" 3 "Stub" 4 "Profile_Short" 5 "Profile_Long" 6 "Meta_data" ;
VAL_ 707 NavSpdLimType 0 "Unknown" 1 "Traffic_sign" 2 "Electronic_eye" 3 "Rode_Default" ;
VAL_ 707 NavigationRoadType 0 "Unknown" 1 "Expressway" 2 "City_expressway" 3 "National_rode" 4 "Provincial_rode" 5 "County_rode" 6 "Township_road" 7 "ramp" 8 "Tunnel" 9 "Side_rode" 10 "Channel" 11 "Major_road" 12 "Ordinary_road" 13 "Village_road" ;
VAL_ 707 ALC_SwtReq 0 "OFF" 1 "ON" ;
VAL_ 707 AESSwtReq 0 "OFF" 1 "ON" ;
VAL_ 707 AEB_JASwtReq 0 "OFF" 1 "ON" ;
VAL_ 707 FCTABrkSwtReq 0 "OFF" 1 "ON" ;
VAL_ 707 FCTASwtReq 0 "OFF" 1 "ON" ;
VAL_ 707 HWA_SnvtySet 0 "Normal" 1 "High_Sensitivity" 2 "Low_Sensitivity" 3 "Max_Sensitivity" ;
VAL_ 707 NavTSRTrafSign 0 "None" 1 "Snow" 2 "Fog" 3 "ThunderStorm" 4 "Rain" 5 "FWay" 6 "EFWay" 7 "Straight" 8 "FrontageLeft" 9 "TurnLeftRight" 10 "FrontageRight" 11 "Right" 12 "TurnRight" 13 "Left" 14 "TurnLeft" 15 "RelieveNoOvertake" 16 "NoOvertake" 17 "StopGiveWay" 18 "GiveWay" 19 "NoPass" 20 "NoEntry" 21 "NoCar" 22 "NoTruck" 23 "NoBus" 24 "NoTurnaround" 25 "NoStraightLeftTurn" 26 "NoStraightRightTurn" 27 "NoLeftRightTurn" 28 "NoLeftTurn" 29 "NoRightTurn" 30 "NoStraight" 31 "WarnKids" 32 "WarnPed" 33 "WarnBike" 34 "WarnWorks" 35 "WarnWildanimal" 36 "WarnCattle" 37 "ACCidentProneSection" 38 "Town" 39 "Slow" 40 "SharpTurnR" 41 "SharpTurnL" 42 "ReverseCurveL" 43 "ReverseCurveR" 44 "ContinuousBend" 45 "Crossroads" 46 "ConfluenceR" 47 "ConfluenceL" 255 "Invalid" ;
VAL_ 707 HWA_SwtReq 0 "OFF" 1 "ON" ;
VAL_ 707 NavSpdLimSignSts 0 "Unknow" 1 "Exist_SPL_sign" 2 "Exist_Traffic_sign" 3 "Exist_SPL_and_Traffic_sign" 4 "None" 5 "Plural" ;
VAL_ 707 NavCtryType 156 "China" ;
VAL_ 707 NavSpdLimUnit_HUT 0 "Unknown" 1 "KMH" 2 "MPH" ;
VAL_ 707 NavSpdLimValue 0 "No_Display" 1 "SPL_5" 2 "SPL_10" 3 "SPL_15" 4 "SPL_20" 5 "SPL_25" 6 "SPL_30" 7 "SPL_35" 8 "SPL_40" 9 "SPL_45" 10 "SPL_50" 11 "SPL_55" 12 "SPL_60" 13 "SPL_65" 14 "SPL_70" 15 "SPL_75" 16 "SPL_80" 17 "SPL_85" 18 "SPL_90" 19 "SPL_95" 20 "SPL_100" 21 "SPL_105" 22 "SPL_110" 23 "SPL_115" 24 "SPL_120" 25 "SPL_125" 26 "SPL_130" 27 "SPL_135" 28 "SPL_140" 29 "SPL_145" 30 "SPL_150" 63 "Invalid" ;
VAL_ 707 TSR_SnvtySet 31 "Invalid" ;
VAL_ 707 ISLSwtReq 0 "OFF" 1 "ON" ;
VAL_ 707 DOWSwtReq 0 "OFF" 1 "ON" ;
VAL_ 707 AEB_PedSwtReq 0 "OFF" 1 "ON" ;
VAL_ 707 LSSSwtReq 0 "OFF" 1 "ON" ;
VAL_ 707 IntelligentEvaSwtReq 0 "OFF" 1 "ON" ;
VAL_ 707 LSSWarnFormSwtReq 0 "Voice" 1 "Haptic" 2 "Voice_Haptic" ;
VAL_ 707 TSRWarnSwtReq 0 "OFF" 1 "ON" ;
VAL_ 707 TSRSwtReq 0 "OFF" 1 "ON" ;
VAL_ 707 LDWSwtReq 0 "OFF" 1 "ON" ;
VAL_ 707 ESS_VehSwtReq 0 "OFF" 1 "ON" ;
VAL_ 707 ESS_PedSwtReq 0 "OFF" 1 "ON" ;
VAL_ 707 ELKSwtReq 0 "OFF" 1 "ON" ;
VAL_ 707 LCKSwtReq 0 "OFF" 1 "ON" ;
VAL_ 707 LKASwtReq 0 "OFF" 1 "ON" ;
VAL_ 707 AEB_VehSwtReq 0 "OFF" 1 "ON" ;
VAL_ 707 FCW_SnvtySet 0 "Normal" 1 "High_sensitivity" 2 "Low_sensitivity" ;
VAL_ 707 RCWSwtReq 0 "OFF" 1 "ON" ;
VAL_ 707 RCTABrkSwtReq 0 "OFF" 1 "ON" ;
VAL_ 707 RCTASwtReq 0 "OFF" 1 "ON" ;
VAL_ 707 LCASwtReq 0 "OFF" 1 "ON" ;
VAL_ 707 IFC_SnvtySet 0 "Normal" 1 "High_sensitivity" 2 "Low_sensitivity" ;
VAL_ 707 NOH_Btn_Sts 0 "Not_apply" 1 "Apply" ;
VAL_ 707 DR_CalibratedSts 0 "Not_Calibrated" 1 "Calibrated" ;
VAL_ 707 IntellgntcurveReq 0 "OFF" 1 "ON" ;
VAL_ 717 PassWinPosnSts_Perc 0 "Unknown" 1 "Close" 2 "Open" 3 "_5Percent_Open" 4 "_10Percent_Open" 5 "_15Percent_Open" 6 "_20Percent_Open" 7 "_25Percent_Open" 8 "_30Percent_Open" 9 "_35Percent_Open" 10 "_40Percent_Open" 11 "_45Percent_Open" 12 "_50Percent_Open" 13 "_55Percent_Open" 14 "_60Percent_Open" 15 "_65Percent_Open" 16 "_70Percent_Open" 17 "_75Percent_Open" 18 "_80Percent_Open" 19 "_85Percent_Open" 20 "_90Percent_Open" 21 "_95Percent_Open" ;
VAL_ 717 RSDS_Pass_LED_Sts 0 "No_Error" 1 "Error" ;
VAL_ 725 PassRearDoorWinPosnSts_Perc 0 "Unknown" 1 "Close" 2 "Open" 3 "_5_Percent_Open" 4 "_10_Percent_Open" 5 "_15_Percent_Open" 6 "_20_Percent_Open" 7 "_25_Percent_Open" 8 "_30_Percent_Open" 9 "_35_Percent_Open" 10 "_40_Percent_Open" 11 "_45_Percent_Open" 12 "_50_Percent_Open" 13 "_55_Percent_Open" 14 "_60_Percent_Open" 15 "_65_Percent_Open" 16 "_70_Percent_Open" 17 "_75_Percent_Open" 18 "_80_Percent_Open" 19 "_85_Percent_Open" 20 "_90_Percent_Open" 21 "_95_Percent_Open" ;
VAL_ 726 DrvgRWSModFailSts 0 "NO_Fault" 1 "DrvgAngReqLimit_Exceed" 2 "DrvgAngSpdReqLimit_Exceed" 3 "DrvgVldSig_Invalid" 4 "DrvgMsg_Invalid" 5 "PDCU_Sys_Failure" 6 "RWS_Sys_Failure" 7 "BTC_Mod_Sts" 8 "Reserved" ;
VAL_ 726 WtrAirCoolrPmp_FltSts 0 "Normal" 1 "Fail" ;
VAL_ 726 RollingCounter_VCU13 15 "Invalid_value" ;
VAL_ 726 VCU_LTRadrOutlWtrTemp 254 "Init" 255 "Invalid_Value" ;
VAL_ 726 RollingCounter_VCU3 15 "Invalid_value" ;
VAL_ 726 VCU_RdyLEDSts 0 "OFF" 1 "ON" 2 "Flashing" ;
VAL_ 728 ADAS_Stub_NumOfLaneDrvDir 0 "One_direction_road_driven_in_wrong_direction" 1 "Verbatim_values0" 2 "Verbatim_values1" 3 "Verbatim_values2" 4 "Verbatim_values3" 5 "Verbatim_values4" 6 "6_or_more_lanes" 7 "Invalid" ;
VAL_ 728 ADAS_Stub_NumOfLaneOppDir 0 "One_direction_road" 1 "One_lane_only" 2 "Indicates_2_or_more_lanes" 3 "Invalid" ;
VAL_ 728 ADAS_Stub_RtOfWay 0 "Drvg_towards_this_stub_has_priority_over_all_conflicting_vehicle_movements" 1 "Drvg_towards_this_stub_might_require_yielding_to_conflicting_vehicle_movements" 2 "Unknown" 3 "Invalid" ;
VAL_ 728 ADAS_Stub_LastStub 0 "False" 1 "True" ;
VAL_ 728 ADAS_Stub_TurnAngl 0 "In_path_direction" 1 "_1point417_degrees_right" 2 "Valid_values" 126 "_178point583_degrees_right" 127 "Opposite_direction" 128 "_178point583__degrees_left_181.417_degrees_right" 129 "Valid_values" 253 "_1point417_degrees_left_358.583_degrees_right" 254 "Unknown" 255 "Invalid" ;
VAL_ 728 ADAS_Stub_FormOfWay 0 "Unkown" 1 "Freeway_or_Controlled_Access_road_that_is_not_a_slip_road_ramp" 2 "Multiple_Carriageway_or_Multiply_Digitized_Road" 3 "Single_Carriageway_default" 4 "Roundabout_Circle" 5 "Traffic_Square_Special_Traffic_Figure" 8 "Parallel_Road_as_special_type_of_a_slip_road_ramp" 9 "Slip_Road_Ramp_on_a_Freeway_or_Controlled_Access_road" 10 "Slip_Road_Ramp_not_on_a_Freeway_or_Controlled_Access_road" 11 "Service_Road_or_Frontage_Road" 12 "Entrance_to_or_exit_of_a_Car_Park" 13 "Entrance_to_or_exit_to_Service" 14 "Pedestrian_Zone" 15 "Unknow" ;
VAL_ 728 ADAS_Stub_CmplxInsct 0 "New_path_is_not_part_of_complex_intersection" 1 "New_path_is_part_of_a_complex_intersection" 2 "Unknown" 3 "Invalid" ;
VAL_ 728 ADAS_Stub_PartOfCalcRoute 0 "New_path_from_this_point_on_is_not_part_of_Calculated_Route" 1 "New_path_from_this_point_on_is_part_of_Calculated_Route" 2 "Unknown" 3 "invalid" ;
VAL_ 728 ADAS_Stub_FuncRoadClass 0 "Unkown" 1 "Expressway" 2 "City_expressway" 3 "National_road" 4 "Provincial_rode_or_County_road" 5 "City_or_Village_road" 6 "Other_road" 7 "Invalid" ;
VAL_ 728 ADAS_Stub_RelProbb 0 "Unknown" 1 "Valid_values" 31 "Invalid" ;
VAL_ 728 ADAS_Stub_Update 0 "False" 1 "True" ;
VAL_ 728 ADAS_Stub_Retr 0 "False" 1 "True" ;
VAL_ 728 ADAS_Stub_CycCnt 0 "Valid_value1" 1 "Valid_value2" 2 "Valid_value3" 3 "Valid_value4" ;
VAL_ 728 ADAS_Stub_Offset 8191 "Invalid_data" ;
VAL_ 728 ADAS_Stub_MsgTyp 0 "System_Specific" 1 "Position" 2 "Segment" 3 "Stub" 4 "Profile_Short" 5 "Profile_Long" 6 "Meta_data" ;
VAL_ 730 ADAS_Seg_NumOfLaneDrvDir 0 "One_direction_road_driven_in_wrong_direction" 1 "Verbatim_values1" 2 "Verbatim_values2" 3 "Verbatim_values3" 4 "Verbatim_values4" 5 "Verbatim_values5" 6 "Six_or_more_lanes" 7 "Invalid" ;
VAL_ 730 ADAS_Seg_NumOfLaneOppDir 0 "One_direction_road" 1 "One_lane_only" 2 "Indicates_2_or_more_lanes" 3 "Invalid" ;
VAL_ 730 ADAS_Seg_DivideRoad 0 "Segment_is_not_part_of_a_divided_road_dual_carriageway" 1 "Segment_is_part_of_a_divided_road_dual_carriageway" 2 "Unknown" ;
VAL_ 730 ADAS_Seg_EffSpdLmtTyp 0 "Implicit_for_instance_default_speed_limit_in_the_cities" 1 "Explicit_on_traffic_sign" 2 "Explicit_by_night" 3 "Explicit_by_day" 4 "Explicit_time_of_day" 5 "Explicit_Electronic_eye" 6 "Explicit_snow" 7 "Unknown" ;
VAL_ 730 ADAS_Seg_EffSpdLmt 0 "Unknown_including_variable_value_sign_controlled" 1 "value1" 2 "value2" 3 "value3" 4 "value4" 5 "value5" 6 "value6" 7 "value7" 8 "value8" 9 "value9" 10 "value10" 11 "value11" 12 "value12" 13 "value13" 14 "value14" 15 "value15" 16 "value16" 17 "value17" 18 "value18" 19 "value19" 20 "value20" 21 "value21" 22 "value22" 23 "value23" 24 "value24" 25 "value25" 26 "value26" 27 "value27" 28 "value28" 29 "Less_Than_Unlimited" 30 "Unlimited" ;
VAL_ 730 ADAS_Seg_FormOfWay 0 "Unkown" 1 "Freeway_or_Controlled_Access_road_that_is_not_a_slip_road_ramp" 2 "Multiple_Carriageway_or_Multiply_Digitized_Road" 3 "Single_Carriageway_default" 4 "Roundabout_Circle" 5 "Traffic_Square_Special_Traffic_Figure" 8 "Parallel_Road_as_special_type_of_a_slip_road_ramp" 9 "Slip_Road_Ramp_on_a_Freeway_or_Controlled_Access_road" 10 "Slip_Road_Ramp_not_on_a_Freeway_or_Controlled_Access_road" 11 "Service_Road_or_Frontage_Road" 12 "Entrance_to_or_exit_of_a_Car_Park" 13 "Entrance_to_or_exit_to_Service" 14 "Pedestrian_Zone" 15 "Unknow" ;
VAL_ 730 ADAS_Seg_CmplxInsct 0 "Segment_is_not_part_of_complex_intersection" 1 "Segment_is_part_of_a_complex_intersection" 2 "Unknown" 3 "Invalid" ;
VAL_ 730 ADAS_Seg_PartOfCalcRoute 0 "Segment_is_not_part_of_Calculated_Route" 1 "Segment_is_part_of_Calculated_Route" 2 "Unknown" 3 "Invalid" ;
VAL_ 730 ADAS_Seg_FuncRoadClass 0 "Unkown" 1 "Expressway" 2 "City_expressway" 3 "National_road" 4 "Provincial_rode_or_County_road" 5 "City_or_Village_road" 6 "Other_road" 7 "Invalid" ;
VAL_ 730 ADAS_Seg_RelProbb 0 "Unknown" 1 "Valid_values" 31 "Invalid" ;
VAL_ 730 ADAS_Seg_Update 0 "False" 1 "True" ;
VAL_ 730 ADAS_Seg_Retr 0 "False" 1 "True" ;
VAL_ 730 ADAS_Seg_BuildUpArea 0 "Segment_is_not_part_of_a_built_up_area" 1 "Segment_is_part_of_a_built_up_area" 2 "Unknown" 3 "Invalid" ;
VAL_ 730 ADAS_Seg_Brdg 0 "Segment_is_not_part_of_a_bridge" 1 "Segment_is_part_of_a_bridge" 2 "Unknown" 3 "Invalid" ;
VAL_ 730 ADAS_Seg_Tunnel 0 "Segment_is_not_part_of_a_tunnel" 1 "Segment_is_part_of_a_tunnel" 2 "Unknown" 3 "Invalid" ;
VAL_ 730 ADAS_Seg_CycCnt 0 "Valid_value_1" 1 "Valid_value_2" 2 "Valid_value_3" 3 "Valid_value_4" ;
VAL_ 730 ADAS_Seg_Offset 8191 "Invalid_data" ;
VAL_ 730 ADAS_Seg_MsgTyp 0 "System_Specific" 1 "Position" 2 "Segment" 3 "Stub" 4 "Profile_Short" 5 "Profile_Long" 6 "Meta_data" ;
VAL_ 733 ADAS_ProfShort_Value1 1023 "Unknow" ;
VAL_ 733 ADAS_ProfShort_Value0 1023 "Unknow" ;
VAL_ 733 ADAS_ProfShort_Dist1 0 "No_other_profile_values_are_defined_in_this_message" 1023 "Invalid" ;
VAL_ 733 ADAS_ProfShort_AccurClass 0 "Hiest_accuracy" 1 "Medium_accuracy" 2 "Lowest_accuracy" 3 "Unknown" ;
VAL_ 733 ADAS_ProfShort_Update 0 "False" 1 "True" ;
VAL_ 733 ADAS_ProfShort_Retr 0 "False" 1 "True" ;
VAL_ 733 ADAS_ProfShort_CtrlPoint 0 "False" 1 "True" ;
VAL_ 733 ADAS_ProfShort_ProfTyp 0 "Unknow" 1 "Curvature" 2 "Route_Number_Types" 3 "Slope_step" 4 "Slope_LINEAR" 5 "Road_ACCessibility" 6 "Road_condition" 7 "Variable_Speed_Sign_Position" 8 "Heading_Change" 18 "History_average_speed" 19 "Traffic_Flow" ;
VAL_ 733 ADAS_ProfShort_CycCnt 0 "Valid_value_1" 1 "Valid_value_2" 2 "Valid_value_3" 3 "Valid_value_4" ;
VAL_ 733 ADAS_ProfShort_Offset 8191 "Invalid" ;
VAL_ 733 ADAS_ProfShort_MsgTyp 0 "System_Specific" 1 "Position" 2 "Segment" 3 "Stub" 4 "Profile_Short" 5 "Profile_Long" 6 "Meta_data" ;
VAL_ 734 ADAS_ProfLong_Value -2147483648 "invalid" ;
VAL_ 734 ADAS_ProfLong_Update 0 "False" 1 "True" ;
VAL_ 734 ADAS_ProfLong_Retr 0 "False" 1 "True" ;
VAL_ 734 ADAS_ProfLong_CtrlPoint 0 "False" 1 "True" ;
VAL_ 734 ADAS_ProfLong_ProfTyp 0 "Unkown" 1 "Longitude" 2 "Latitude" 3 "Altitude" 4 "Control_Point_Longitude" 5 "Control_Point_Latitude" 6 "Control_Point_Altitude" 7 "Link_Identifier" 8 "Traffic_Sign" 9 "Truck_Speed_Limits" 10 "Extended_Lane" 19 "Traffic_Event" 20 "Weather" ;
VAL_ 734 ADAS_ProfLong_CycCnt 0 "Valid_value_1" 1 "Valid_value_2" 2 "Valid_value_3" 3 "Valid_value_4" ;
VAL_ 734 ADAS_ProfLong_Offset 8191 "Invalid" ;
VAL_ 734 ADAS_ProfLong_MsgTyp 0 "System_Specific" 1 "Position" 2 "Segment" 3 "Stub" 4 "Profile_Short" 5 "Profile_Long" 6 "Meta_data" ;
VAL_ 768 ASLCtrlSts 0 "OFF" 1 "Standby" 2 "Overspeed" 3 "Limit" 5 "KickDown" ;
VAL_ 768 RWSModSts 0 "Initial_Value" 1 "PDCUMod" 2 "AdasMod" 3 "IBCMod" 4 "SBWMod" ;
VAL_ 768 RWSModFailSts 0 "NO_Fault" 1 "Adas_AngReqLimit_Exceed" 2 "Adas_AngSpdReqLimit_Exceed" 3 "ADAS_VldSig_Invalid" 4 "ADAS_Msg_Invalid" 5 "PDCU_Sys_Failure" 6 "RWS_Sys_Failure" 7 "ADAS_DrvgVldSig_Invalid" 8 "BTC_Mod_Sts" 9 "ADAS_DrvgMsg_Invalid" ;
VAL_ 795 VCU_SysFltLvl 0 "No_fault" 1 "Level1" 2 "Level2" 3 "Level3" 4 "Level4" 5 "Level5" ;
VAL_ 796 HUT_EPB_SwtPosn 0 "Neutral" 1 "Release" 2 "Apply" ;
VAL_ 799 OBC_CCLineSts 0 "Not_connected" 1 "Connected" 2 "Half_connection" 3 "Error" ;
VAL_ 822 DrvImpairmAsstReq 0 "Initial_value" 1 "OFF" 2 "ON" ;
VAL_ 827 LowPowerEgyMngmntModReq 0 "No_Action" 1 "OFF" 2 "ON" ;
VAL_ 829 T_BOX_AVPActvReq 0 "No_Request" 1 "Request_HAVP" 2 "Request_PAVP" ;
VAL_ 840 SentinelMode_HUT 0 "No_Action" 1 "OFF" 2 "ON" ;
VAL_ 849 RollingCounter_ABM1 15 "Invalid_value" ;
VAL_ 849 CrashSev_1 0 "Not_Trigger" 1 "Trigger" ;
VAL_ 849 CrashSev_2 0 "Not_Trigger" 1 "Trigger" ;
VAL_ 849 SecRowRSBR_Visual 0 "Lamp_off" 1 "Lamp_on" 3 "Lamp_blink_sound_remind" ;
VAL_ 849 DrvSBR_Visual 0 "Lamp_off" 1 "Lamp_on" 3 "Lamp_blink_And_sound_remind" ;
VAL_ 849 PassSBR_Visual 0 "Lamp_off" 1 "Lamp_on" 3 "Lamp_blink_sound_remind" ;
VAL_ 849 SecRowLSBR_Visual 0 "Lamp_off" 1 "Lamp_on" 3 "Lamp_blink_sound_remind" ;
VAL_ 849 SecRowMidSBR_Visual 0 "Lamp_off" 1 "Lamp_on" 3 "Lamp_blink_sound_remind" ;
VAL_ 849 CrashOutputSts 0 "No_crash" 2 "Front_First_level" 3 "Rear_crash_Reserved" 8 "Right_hand_side" 16 "Left_hand_side" 17 "Rollover_Reserved" 18 "Static_Roll_Reserved" ;
VAL_ 849 PassSBLockSts 0 "Buckled" 1 "Unbuckle" ;
VAL_ 849 SecRowRSBLockSts 0 "Buckled" 1 "Unbuckle" ;
VAL_ 849 DrvSBR 0 "No_Reminder" 1 "Reminder" ;
VAL_ 849 SecRowMidSBLockSts 0 "Buckled" 1 "Unbuckle" ;
VAL_ 849 AirbFailLmpCmd 0 "Lamp_OFF" 1 "Lamp_ON" ;
VAL_ 849 SecRowLSBLockSts 0 "Buckled" 1 "Unbuckle" ;
VAL_ 849 PABSwtSts 0 "Switch_OFF_PAB_Ban" 1 "Switch_ON_PAB_Not_Ban" ;
VAL_ 860 ValetParkingModSts 0 "Initial_value" 1 "OFF" 2 "ON" ;
VAL_ 879 WtrPmpSts 0 "Initial_Value" 1 "OFF" 2 "ON" 3 "Fault" ;
VAL_ 879 WtrPmpActRotSpd 0 "Initial_Value" 1 "Valid_values" 255 "Signal_Not_Populated" ;
VAL_ 880 Time_Day 0 "Invalid" ;
VAL_ 880 Time_Month 0 "Invalid" 1 "Valid_month1" 2 "Valid_month2" 3 "Valid_month3" 4 "Valid_month4" 5 "Valid_month5" 6 "Valid_month6" 7 "Valid_month7" 8 "Valid_month8" 9 "Valid_month9" 10 "Valid_month10" 11 "Valid_month11" 12 "Valid_month12" ;
VAL_ 880 Time_Year_Right 0 "Valid_year0" 1 "Valid_year1" 2 "Valid_year2" 3 "Valid_year3" 4 "Valid_year4" 5 "Valid_year5" 6 "Valid_year6" 7 "Valid_year7" 8 "Valid_year8" 9 "Valid_year9" 15 "Invalid" ;
VAL_ 880 Time_Year_Left 0 "Valid_year0" 1 "Valid_year1" 2 "Valid_year2" 3 "Valid_year3" 4 "Valid_year4" 5 "Valid_year5" 6 "Valid_year6" 7 "Valid_year7" 8 "Valid_year8" 9 "Valid_year9" 15 "Invalid" ;
VAL_ 880 Time_Second 63 "Invalid" ;
VAL_ 880 TimeMod 0 "_24" 1 "_12" ;
VAL_ 880 TimeIndcn 0 "am" 1 "pm" ;
VAL_ 880 Time_Minutes 63 "Invalid" ;
VAL_ 880 Time_Hour 31 "Invalid" ;
VAL_ 907 RollingCounter_PTCC1_1 15 "Invalid_value" ;
VAL_ 907 BSCSts 0 "Initial_Value" 1 "OFF" 2 "Standby" 3 "Active" 4 "Failed" ;
VAL_ 1001 T_BOX_SysErrSts 0 "No_Error" 1 "Error" 2 "Standby_Battery_Error" ;
VAL_ 1045 ADAS_Meta_ProtVer_Minor 0 "Valid_value_1" 1 "Valid_value_2" 2 "Valid_value_3" 3 "Valid_value_4" 4 "Valid_value_5" 5 "Valid_value_6" 6 "Valid_value_7" 7 "Valid_value_8" 8 "Valid_value_9" 9 "Valid_value_10" 10 "Valid_value_11" 11 "Valid_value_12" 12 "Valid_value_13" 13 "Valid_value_14" 14 "Valid_value_15" 15 "Valid_value_16" ;
VAL_ 1045 ADAS_Meta_SpdUnits 0 "KM_per_Hour" 1 "MPH" ;
VAL_ 1045 ADAS_Meta_MapVerYear 63 "Invalid" ;
VAL_ 1045 ADAS_Meta_MapVerQtr 0 "Valid_value_1" 1 "Valid_value_2" 2 "Valid_value_3" 3 "Valid_value_4" ;
VAL_ 1045 ADAS_Meta_RegionCode 0 "Unknow" 32767 "Invalid" ;
VAL_ 1045 ADAS_Meta_DrvSide 0 "Drvg_Side_Left" 1 "Drvg_Side_Right" ;
VAL_ 1045 ADAS_Meta_HwVer 0 "Unknown" ;
VAL_ 1045 ADAS_Meta_ProtVer_MinorSub 0 "Valid_value_1" 1 "Valid_value_2" 2 "Valid_value_3" 3 "Valid_value_4" 4 "Valid_value_5" 5 "Valid_value_6" 6 "Valid_value_7" 7 "Valid_value_8" ;
VAL_ 1045 ADAS_Meta_ProtVer_Major 0 "Valid_value_1" 1 "Valid_value_2" 2 "Valid_value_3" 3 "Valid_value_4" ;
VAL_ 1045 ADAS_Meta_CycCnt 0 "Valid_value_1" 1 "Valid_value_2" 2 "Valid_value_3" 3 "Valid_value_4" ;
VAL_ 1045 ADAS_Meta_CountryCode 0 "Unknown" ;
VAL_ 1045 ADAS_Meta_MapProvider 0 "Unknown" 1 "Nokia_HERE_NAVTEQ" 2 "TomTom_Tele_Atlas" 3 "Zenrin" 4 "IPC" 5 "NavInfo" 6 "Other" ;
VAL_ 1045 ADAS_Meta_MsgTyp 0 "System_Specific" 1 "Position" 2 "Segment" 3 "Stub" 4 "Profile_Short" 5 "Profile_Long" 6 "Meta_data" ;
VAL_ 68 CarWashModeReq 0 "OFF" 1 "ON" 2 "No_Action" ;
VAL_ 74 AutoAVMSwSet_Cmd 0 "No_Request" 1 "Request" ;
VAL_ 74 SwToFieldCalRstCmd 0 "OFF" 1 "ON" ;
VAL_ 74 View_SoftswitchCmd 0 "No_Request" 1 "Request" ;
VAL_ 74 FPAS_AutoModSwt 0 "No_Request" 1 "Request" ;
VAL_ 74 MEBSwtSet 0 "No_Request" 1 "Request" ;
VAL_ 74 CarMdlDispCmd 0 "No_Request" 1 "Request" ;
VAL_ 74 CarMdlTrsprcySwtCmd 0 "No_Request" 1 "Request" ;
VAL_ 74 AutoViewChgCmd 0 "No_Request" 1 "Request" ;
VAL_ 74 LaneCalActvtCmd 0 "OFF" 1 "ON" ;
VAL_ 74 Sgl_View_Sel 0 "No_Commands" 1 "Touch_2D_Front_Button" 2 "Touch_2D_Rear_Button" 3 "Touch_2D_Left_Button" 4 "Touch_2D_Right_Button" 5 "Touch_2D_Left_Front_Button" 6 "Touch_2D_Right_Front_Button" 7 "Touch_2D_Left_Back_Button" 8 "Touch_2D_Right_Back_Button" 9 "Touch_return_Button" 10 "Touch_Engine_Room_Button" 11 "Touch_Front_Wheel_Button" 12 "Touch_Rear_Wheel_Button" ;
VAL_ 74 AutoAVMmodSet 0 "No_Action" 1 "Half_screen" 2 "Full_screen" ;
VAL_ 74 WheelVieSwt 0 "No_Action" 1 "Request" ;
VAL_ 96 RollingCounter_HCU_HP10 15 "Invalid_value" ;
VAL_ 96 HCU_PowertrainSts 0 "Sleep" 1 "Initialize_Mode" 2 "Power_Up" 3 "Power_Down" 4 "Home" 5 "Run" 6 "Charging" 7 "Cellphone_AC" 8 "Limphome" 9 "Emergency_Mode" 10 "V2L" 11 "Prepare_Sleep" 12 "Ready" 13 "LV_Charging" 14 "LT_Charging" 15 "IL_Heating" 16 "Thermal_Run_Away" 17 "End_Of_Line" 18 "BattTempKeep" ;
VAL_ 96 RollingCounter_HCU_PT1 15 "Invalid_value" ;
VAL_ 161 RollingCounter_CSA2 15 "Invalid_value" ;
VAL_ 161 HWA_OK_OFFSwt 0 "No_Press" 1 "Pressed" ;
VAL_ 161 ManualShiftReq 0 "No_shift_no_control" 1 "Shift_up_request" 2 "Shift_down_request" 3 "Both_pedals_pressed" 6 "Invalid" 7 "Fault" ;
VAL_ 161 CC_ACCSwtErr 0 "No_Error" 1 "Error" ;
VAL_ 161 ACCTimeGapSetSwt 0 "No_press" 1 "Pressed" ;
VAL_ 161 CC_ACC_DecSetSpd_SetSwt 0 "No_Press" 1 "Pressed" ;
VAL_ 161 CC_ACC_IncSetSpd_ResuSwt 0 "No_Press" 1 "Pressed" ;
VAL_ 161 SAS_Sts 0 "SAS_Angle_And_Speed_Correct" 1 "SAS_Not_Calibrated" 2 "Intermittent_Error_Detected" 3 "Permanent_Error_Detected" ;
VAL_ 161 ACC_TimeGap_DecSetSwt 0 "No_Press" 1 "Pressed" ;
VAL_ 161 ACC_TimeGap_IncSetSwt 0 "No_press" 1 "Pressed" ;
VAL_ 161 CC_ACC_CANCEL_OFFSwt 0 "No_Press" 1 "Pressed" ;
VAL_ 161 CC_ACC_CRUISE_OFFSwt 0 "No_Press" 1 "Pressed" ;
VAL_ 161 SteerWheelSpdSign 0 "Left_Positive" 1 "Right_Negative" ;
VAL_ 161 SteerWheelSpd 32767 "Invalid" ;
VAL_ 161 SteerWheelAngSign 0 "Left_Positive" 1 "Right_Negative" ;
VAL_ 161 SteerWheelAng 32767 "Invalid" ;
VAL_ 181 RollingCounter_VCU15 15 "Invalid_value" ;
VAL_ 181 VCU_RespHWP 0 "No_response" 1 "Response" ;
VAL_ 181 VCU_HWPInterface 0 "No_response" 1 "Response" 2 "Response_partially" ;
VAL_ 181 VCU_HWPInterErrReason 0 "No_Error" 1 "ERR_with_Main_ECU_on_PTCAN" 2 "ERR_with_Main_ECU_on_PMCAN" 3 "ERR_with_Main_ECU_on_both_CAN" 4 "ERR_with_Backup_ECU_on_PTCAN" 5 "ERR_with_Backup_ECU_on_PMCAN" 6 "ERR_with_Backup_ECU_on_both_CAN" 7 "ERR_with_Main_ECU_and_Backup_ECU" 8 "ERR_with_Main_ECU_and_Backup_ECU_on_PT_CAN" 9 "ERR_with_Main_ECU_and_Backup_ECU_on_PM_CAN" ;
VAL_ 181 VCU_DrvrIntvGearSts 0 "False" 1 "True" ;
VAL_ 181 RollingCounter_VCU6 15 "Invalid_value" ;
VAL_ 181 VCU_AutParkAvlSts 0 "Not_available" 1 "Available" ;
VAL_ 181 VCU_BrkPedlSts 0 "No_Active" 1 "Brake_active" 2 "Invalid" ;
VAL_ 181 HCU_BrkPedalStsValid 0 "Invalid_Values" 1 "Valid_Values" ;
VAL_ 181 VCU_APedlPosVld 0 "Invalid" 1 "Valid" ;
VAL_ 181 VCU_AccelPedalPosnValid 0 "Invalid_Value" 1 "Valid_Value" ;
VAL_ 188 RWS_FailSts 0 "No_fault" 1 "Permanent_Error_Detected" 2 "Intermittent_Error_Detected" 3 "Unimportant_Error_Detected" ;
VAL_ 188 RWS_SteerSpd 0 "Initial_Value" ;
VAL_ 188 RWS_SteerSpdVld 0 "Invalid" 1 "Valid" ;
VAL_ 188 RWS_AngActVld 0 "Invalid" 1 "Valid" ;
VAL_ 188 RWS_AngAct 4095 "Initial_Value" ;
VAL_ 188 RWS_StsResp 0 "Initial_Value" 1 "Normal" 2 "CrabMod" 3 "ManualMod" ;
VAL_ 189 RollingCounter_ESP12 15 "Invalid_value" ;
VAL_ 189 ESP_VehHldSts 0 "Not_active" 1 "Active" ;
VAL_ 189 TgtRcprtnTrqSts 0 "Not_Initialized" 1 "Normal" 2 "Faulty" ;
VAL_ 199 E_ShiftFault 0 "E_shift_Normal" 1 "E_shift_fault" ;
VAL_ 199 DrvReqPark 0 "No_Request" 1 "Driver_request_park_button" 2 "Park_button_fault" ;
VAL_ 199 DRV_RQ_SHFT 0 "Shifter_position_zero_Z_or_POS_ZERO" 2 "Shifter_position_two_forward_twice_X2_or_POS_TWO" 3 "Shifter_position_three_forward_once_X1_or_POS_THREE" 4 "Shifter_position_four_backwards_once_Y1_POS_FOUR" 5 "Shifter_position_five_backwards_twice_Y2_POS_FIVE" 8 "Shifter_not_initialized_or_INIT" 15 "Signal_not_available_or_SNA_Double_fault_shifter_sensor" ;
VAL_ 255 RollingCounter_Body_Hei 15 "Invalid_value" ;
VAL_ 255 HeiSnsrSts_RR 0 "Initial_value" 1 "No_Failure" 2 "Failure" ;
VAL_ 255 HeiSnsrSts_RL 0 "Initial_value" 1 "No_Failure" 2 "Failure" ;
VAL_ 255 HeiSnsrSts_FR 0 "Initial_value" 1 "No_Failure" 2 "Failure" ;
VAL_ 255 HeiSnsrSts_FL 0 "Initial_value" 1 "No_Failure" 2 "Failure" ;
VAL_ 255 HeiSnsrLvlCtrlCalCmpl 0 "Initial_value" 1 "Level_calibration_not_completed" 2 "Level_calibration_completed" ;
VAL_ 255 HeiSnsrCurrHei_RR 0 "Initial_value" 255 "Invalid_value" ;
VAL_ 255 HeiSnsrCurrHei_RL 0 "Initial_value" 255 "Invalid_value" ;
VAL_ 255 HeiSnsrCurrHei_FR 0 "Initial_value" 255 "Invalid_value" ;
VAL_ 255 HeiSnsrCurrHei_FL 0 "Initial_value" 255 "Invalid_value" ;
VAL_ 473 OTApowertrainmode 0 "No_Action" 1 "Powertrain_ON" 2 "Powertrain_OFF" ;
VAL_ 568 SrPosn_VR_APP 0 "Tilt_up" 10 "_10Percent" 20 "_20Percent" 30 "_30Percent" 40 "_40Percent" 50 "_50Percent" 60 "_60Percent" 70 "_70Percent" 80 "_80Percent" 90 "_90Percent" 100 "Fully_open" 101 "Fully_close" 102 "Vent_area" ;
VAL_ 568 RLS_AmbBrightness 4095 "Invaild" ;
VAL_ 568 RLS_FwBrightness 4095 "Invaild" ;
VAL_ 569 BasicFunReq 0 "No_Control" ;
VAL_ 569 BasicFunID 0 "No_Control" 255 "End" ;
VAL_ 597 PhyHazardSwt 0 "No_pressed" 1 "Pressed" ;
VAL_ 597 RFPosnLmpFailSts_Zone 0 "No_failure" 1 "Failure" ;
VAL_ 597 LFPosnLmpFailSts_Zone 0 "No_failure" 1 "Failure" ;
VAL_ 597 RFTurnLmpFailSts_Zone 0 "No_failure" 1 "Failure" ;
VAL_ 597 LFTurnLmpFailSts_Zone 0 "No_failure" 1 "Failure" ;
VAL_ 597 RLowBeamFailSts_Zone 0 "No_failure" 1 "Failure" ;
VAL_ 597 LLowBeamFailSts_Zone 0 "No_failure" 1 "Failure" ;
VAL_ 597 RHiBeamFailSts_Zone 0 "No_failure" 1 "Failure" ;
VAL_ 597 LHiBeamFailSts_Zone 0 "No_failure" 1 "Failure" ;
VAL_ 597 HiPosnBrkLmpFailSts_Zone 0 "No_failure" 1 "Failure" ;
VAL_ 597 RRFogLmpFailSts_Zone 0 "No_failure" 1 "Failure" ;
VAL_ 597 LRFogLmpFailSts_Zone 0 "No_failure" 1 "Failure" ;
VAL_ 597 RFFogLmpFailSts_Zone 0 "No_failure" 1 "Failure" ;
VAL_ 597 LFFogLmpFailSts_Zone 0 "No_failure" 1 "Failure" ;
VAL_ 597 RBrkLmpFailSts_Zone 0 "No_failure" 1 "Failure" ;
VAL_ 597 LBrkLmpFailSts_Zone 0 "No_failure" 1 "Failure" ;
VAL_ 597 RRPosnLmpFailSts_Zone 0 "No_failure" 1 "Failure" ;
VAL_ 597 LRPosnLmpFailSts_Zone 0 "No_failure" 1 "Failure" ;
VAL_ 597 RRTurnLmpFailSts_Zone 0 "No_failure" 1 "Failure" ;
VAL_ 597 LRTurnLmpFailSts_Zone 0 "No_failure" 1 "Failure" ;
VAL_ 597 HiPosnBrkLmpOutpSts_Zone 0 "OFF" 1 "ON" ;
VAL_ 597 PosnLmpOutpSts_Zone 0 "OFF" 1 "ON" ;
VAL_ 597 RBrkLmpOutpSts_Zone 0 "OFF" 1 "ON" ;
VAL_ 597 LBrkLmpOutpSts_Zone 0 "OFF" 1 "ON" ;
VAL_ 597 RFogLmpSts_Zone 0 "OFF" 1 "ON" ;
VAL_ 597 FFogLmpSts_Zone 0 "OFF" 1 "ON" ;
VAL_ 597 RTurnLmpSts_Zone 0 "OFF" 1 "ON" ;
VAL_ 597 LTurnLmpSts_Zone 0 "OFF" 1 "ON" ;
VAL_ 597 LowBeamSts_Zone 0 "OFF" 1 "ON" ;
VAL_ 597 HiBeamSts_Zone 0 "OFF" 1 "ON" ;
VAL_ 661 SysPowerModVld 0 "Invalid" 1 "Valid" ;
VAL_ 661 SysPowerMod 0 "OFF" 1 "ACC_Reserved" 2 "ON" 3 "Crank" ;
VAL_ 669 InCarTemp 254 "Initial_value" 255 "Invalid_value" ;
VAL_ 671 RollingCounter_BCM8 15 "Invalid_value" ;
VAL_ 671 KL30BRelaySts 0 "OFF" 1 "ON" ;
VAL_ 671 WiprReq_F_PBox 0 "Wiper_Off" 1 "Wiper_action_once" 2 "Speed1_Lo" 3 "Speed2_Hi" 7 "Invalid" ;
VAL_ 671 RViewMirrorSts 0 "Unfold" 1 "Fold" ;
VAL_ 671 RSDS_RLEDSts 0 "No_Error" 1 "Error" ;
VAL_ 671 RSDS_LLEDSts 0 "No_Error" 1 "Error" ;
VAL_ 671 PASWorkCmd 0 "OFF" 1 "ON" ;
VAL_ 671 RemoteModSts 0 "Normal_Mode" 1 "Remote_Mode" ;
VAL_ 680 TranPMode_Sts 0 "Normal_Mode" 1 "Transport_Mode" ;
VAL_ 688 DrvRearDoorWinPosnSts_Perc 0 "Unknown" 1 "Close" 2 "Open" 3 "_5_Percent_Open" 4 "_10_Percent_Open" 5 "_15_Percent_Open" 6 "_20_Percent_Open" 7 "_25_Percent_Open" 8 "_30_Percent_Open" 9 "_35_Percent_Open" 10 "_40_Percent_Open" 11 "_45_Percent_Open" 12 "_50_Percent_Open" 13 "_55_Percent_Open" 14 "_60_Percent_Open" 15 "_65_Percent_Open" 16 "_70_Percent_Open" 17 "_75_Percent_Open" 18 "_80_Percent_Open" 19 "_85_Percent_Open" 20 "_90_Percent_Open" 21 "_95_Percent_Open" ;
VAL_ 699 OTA_UpgrdModSts 0 "Upgrade_mode_Off" 1 "Remote_upgrade_mode_ON_Powertrain_OFF" 2 "Normal_upgrade_mode_ON_Powertrain_OFF" ;
VAL_ 714 DrvWinPosnSts_Perc 0 "Unknown" 1 "Close" 2 "Open" 3 "_5_percent_Open" 4 "_10_percent_Open" 5 "_15_percent_Open" 6 "_20_percent_Open" 7 "_25_percent_Open" 8 "_30_percent_Open" 9 "_35_percent_Open" 10 "_40_percent_Open" 11 "_45_percent_Open" 12 "_50_percent_Open" 13 "_55_percent_Open" 14 "_60_percent_Open" 15 "_65_percent_Open" 16 "_70_percent_Open" 17 "_75_percent_Open" 18 "_80_percent_Open" 19 "_85_percent_Open" 20 "_90_percent_Open" 21 "_95_percent_Open" ;
VAL_ 714 RSDS_Driver_LED_Sts 0 "No_Error" 1 "Error" ;
VAL_ 770 WarnKeyInCarWhenExit 0 "No_Warning" 1 "Warning" ;
VAL_ 783 LowBeamReq 0 "Off" 1 "On" ;
VAL_ 783 WiprReq 0 "Wiper_Off" 1 "Wiper_action_once" 2 "Speed1_low" 3 "Speed2_high" 7 "Signal_not_available" ;
VAL_ 783 HazardLmpSts 0 "OFF" 1 "ON" ;
VAL_ 793 RollingCounter_BCM1 15 "Invalid_value" ;
VAL_ 793 RLSFailSts 0 "No_Failure" 1 "Failure" ;
VAL_ 793 HoodSts 0 "Closed" 1 "Open" ;
VAL_ 793 WindshldWiprActvSts 0 "Not_active" 1 "Active" ;
VAL_ 793 RRDoorSts 0 "Closed" 1 "Open" ;
VAL_ 793 PassengerDoorSts 0 "Closed" 1 "Open" ;
VAL_ 793 LRDoorSts 0 "Closed" 1 "Open" ;
VAL_ 793 DrvDoorSts 0 "Closed" 1 "Open" ;
VAL_ 793 TrunkSts 0 "Closed" 1 "Open" ;
VAL_ 833 TPMS_AutoLoctSts 0 "Auto_Learn_or_Auto_Locate_not_in_progress_TPMS_is_base_system" 1 "Auto_Learn_in_progress" 2 "Auto_Locate_in_progress_Auto_Learn_complete" 3 "Auto_Locate_complete" 4 "Auto_Learn_timeout" 5 "Auto_Locate_timeout" ;
VAL_ 833 RRTireTempSts 0 "Normal" 1 "High" 2 "Not_Available" ;
VAL_ 833 RLTireTempSts 0 "Normal" 1 "High" 2 "Not_Available" ;
VAL_ 833 FRTireTempSts 0 "Normal" 1 "High" 2 "Not_available" ;
VAL_ 833 FLTireTempSts 0 "Normal" 1 "High" 2 "Not_available" ;
VAL_ 833 RRTirePressIndSts 0 "Normal" 1 "Low" 3 "High" 4 "Not_Available" ;
VAL_ 833 RLTirePressIndSts 0 "Normal" 1 "Low" 3 "High" 4 "Not_Available" ;
VAL_ 833 TirePressSysFailrIndcn 0 "No_failure" 1 "Failure" ;
VAL_ 833 FRTirePressIndSts 0 "Normal" 1 "Low" 3 "High" 4 "Not_available" ;
VAL_ 833 FLTirePressIndSts 0 "Normal" 1 "Low" 3 "High" 4 "Not_available" ;
VAL_ 837 EnvModDetn 0 "Day" 1 "Night" 2 "Tunnel" 3 "Darkstart" ;
VAL_ 837 DrvDoorLockSts 0 "Lock" 1 "Unlock" ;
VAL_ 901 ACAmbTemp 254 "Initial_Value" 255 "Invalid_Value" ;
VAL_ 901 ACFrntBlwrSpd 0 "Off" 1 "Level_1_Low" 2 "Level_2" 3 "Level_3" 4 "Level_4" 5 "Level_5" 6 "Level_6" 7 "Level_7_Hi" 8 "Auto_OFF" 9 "Auto1" 10 "Auto2" 11 "Auto3" 12 "Auto4" 13 "Auto5" 14 "Auto_blower_level" 15 "Initial_value" ;
VAL_ 917 RRTireTemp 255 "Invalid_Value" ;
VAL_ 917 RRTirePress 255 "Invalid_Value" ;
VAL_ 917 RLTireTemp 255 "Invalid_Value" ;
VAL_ 917 RLTirePress 255 "Invalid_Value" ;
VAL_ 917 FRTireTemp 255 "Invalid_Value" ;
VAL_ 917 FRTirePress 255 "Invalid_Value" ;
VAL_ 917 FLTireTemp 255 "Invalid_Value" ;
VAL_ 917 FLTirePress 255 "Invalid_Value" ;
VAL_ 165 DoorHndlBtnActn 0 "No_Action" 1 "Main_Door_Handle_Click" 2 "Main_Door_Handle_Tap_and_hold" 3 "Passenger_door_handle_Click" 4 "Passenger_door_handle_Tap_and_hold" ;
VAL_ 165 PhyKeyPressActn 0 "No_Action" 1 "Key_unlock_Tap_and_hold" 2 "Click_any_key" 3 "Block_keyTap_and_hold" ;
VAL_ 165 PhyKeyPosnSts 0 "No_Action" 1 "Inside" 2 "Outside" ;
